VERSION ""

NS_ :

BS_:

BU_: LED_Driver ISC

BO_ 3221225472 VECTOR__INDEPENDENT_SIG_MSG: 0 Vector__XXX
 SG_ Led_S_0_value : 0|8@1+ (1,0) [0|255] "" Vector__XXX
 SG_ Led_break_value : 0|8@1+ (1,0) [0|255] "" Vector__XXX
 SG_ Led_S_0_value : 0|8@1+ (1,0) [0|255] "" Vector__XXX

BO_ 1280 ISC_Ctrl_Right_LED_A_00: 64 ISC
 SG_ Led0064_value : 504|8@1+ (1,0) [0|255] "" Vector__XXX
 SG_ Led0063_value : 496|8@1+ (1,0) [0|255] "" Vector__XXX
 SG_ Led0062_value : 488|8@1+ (1,0) [0|255] "" Vector__XXX
 SG_ Led0061_value : 480|8@1+ (1,0) [0|255] "" Vector__XXX
 SG_ Led0060_value : 472|8@1+ (1,0) [0|255] "" Vector__XXX
 SG_ Led0059_value : 464|8@1+ (1,0) [0|255] "" Vector__XXX
 SG_ Led0058_value : 456|8@1+ (1,0) [0|255] "" Vector__XXX
 SG_ Led0057_value : 448|8@1+ (1,0) [0|255] "" Vector__XXX
 SG_ Led0056_value : 440|8@1+ (1,0) [0|255] "" Vector__XXX
 SG_ Led0055_value : 432|8@1+ (1,0) [0|255] "" Vector__XXX
 SG_ Led0054_value : 424|8@1+ (1,0) [0|255] "" Vector__XXX
 SG_ Led0053_value : 416|8@1+ (1,0) [0|255] "" Vector__XXX
 SG_ Led0052_value : 408|8@1+ (1,0) [0|255] "" Vector__XXX
 SG_ Led0051_value : 400|8@1+ (1,0) [0|255] "" Vector__XXX
 SG_ Led0050_value : 392|8@1+ (1,0) [0|255] "" Vector__XXX
 SG_ Led0049_value : 384|8@1+ (1,0) [0|255] "" Vector__XXX
 SG_ Led0048_value : 376|8@1+ (1,0) [0|255] "" Vector__XXX
 SG_ Led0047_value : 368|8@1+ (1,0) [0|255] "" Vector__XXX
 SG_ Led0046_value : 360|8@1+ (1,0) [0|255] "" Vector__XXX
 SG_ Led0045_value : 352|8@1+ (1,0) [0|255] "" Vector__XXX
 SG_ Led0044_value : 344|8@1+ (1,0) [0|255] "" Vector__XXX
 SG_ Led0043_value : 336|8@1+ (1,0) [0|255] "" Vector__XXX
 SG_ Led0042_value : 328|8@1+ (1,0) [0|255] "" Vector__XXX
 SG_ Led0041_value : 320|8@1+ (1,0) [0|255] "" Vector__XXX
 SG_ Led0040_value : 312|8@1+ (1,0) [0|255] "" Vector__XXX
 SG_ Led0039_value : 304|8@1+ (1,0) [0|255] "" Vector__XXX
 SG_ Led0038_value : 296|8@1+ (1,0) [0|255] "" Vector__XXX
 SG_ Led0037_value : 288|8@1+ (1,0) [0|255] "" Vector__XXX
 SG_ Led0036_value : 280|8@1+ (1,0) [0|255] "" Vector__XXX
 SG_ Led0035_value : 272|8@1+ (1,0) [0|255] "" Vector__XXX
 SG_ Led0034_value : 264|8@1+ (1,0) [0|255] "" Vector__XXX
 SG_ Led0033_value : 256|8@1+ (1,0) [0|255] "" Vector__XXX
 SG_ Led0032_value : 248|8@1+ (1,0) [0|255] "" Vector__XXX
 SG_ Led0031_value : 240|8@1+ (1,0) [0|255] "" Vector__XXX
 SG_ Led0030_value : 232|8@1+ (1,0) [0|255] "" Vector__XXX
 SG_ Led0029_value : 224|8@1+ (1,0) [0|255] "" Vector__XXX
 SG_ Led0028_value : 216|8@1+ (1,0) [0|255] "" Vector__XXX
 SG_ Led0027_value : 208|8@1+ (1,0) [0|255] "" Vector__XXX
 SG_ Led0026_value : 200|8@1+ (1,0) [0|255] "" Vector__XXX
 SG_ Led0025_value : 192|8@1+ (1,0) [0|255] "" Vector__XXX
 SG_ Led0024_value : 184|8@1+ (1,0) [0|255] "" Vector__XXX
 SG_ Led0023_value : 176|8@1+ (1,0) [0|255] "" Vector__XXX
 SG_ Led0022_value : 168|8@1+ (1,0) [0|255] "" Vector__XXX
 SG_ Led0021_value : 160|8@1+ (1,0) [0|255] "" Vector__XXX
 SG_ Led0020_value : 152|8@1+ (1,0) [0|255] "" Vector__XXX
 SG_ Led0019_value : 144|8@1+ (1,0) [0|255] "" Vector__XXX
 SG_ Led0018_value : 136|8@1+ (1,0) [0|255] "" Vector__XXX
 SG_ Led0017_value : 128|8@1+ (1,0) [0|255] "" Vector__XXX
 SG_ Led0016_value : 120|8@1+ (1,0) [0|255] "" Vector__XXX
 SG_ Led0015_value : 112|8@1+ (1,0) [0|255] "" Vector__XXX
 SG_ Led0014_value : 104|8@1+ (1,0) [0|255] "" Vector__XXX
 SG_ Led0013_value : 96|8@1+ (1,0) [0|255] "" Vector__XXX
 SG_ Led0012_value : 88|8@1+ (1,0) [0|255] "" Vector__XXX
 SG_ Led0011_value : 80|8@1+ (1,0) [0|255] "" Vector__XXX
 SG_ Led0010_value : 72|8@1+ (1,0) [0|255] "" Vector__XXX
 SG_ Led0009_value : 64|8@1+ (1,0) [0|255] "" Vector__XXX
 SG_ Led0008_value : 56|8@1+ (1,0) [0|255] "" Vector__XXX
 SG_ Led0007_value : 48|8@1+ (1,0) [0|255] "" Vector__XXX
 SG_ Led0006_value : 40|8@1+ (1,0) [0|255] "" Vector__XXX
 SG_ Led0005_value : 32|8@1+ (1,0) [0|255] "" Vector__XXX
 SG_ Led0004_value : 24|8@1+ (1,0) [0|255] "" Vector__XXX
 SG_ Led0003_value : 16|8@1+ (1,0) [0|255] "" Vector__XXX
 SG_ Led0002_value : 8|8@1+ (1,0) [0|255] "" Vector__XXX
 SG_ Led0001_value : 0|8@1+ (1,0) [0|255] "" Vector__XXX

BO_ 768 ISC_Ctrl_Left_LED_A_00: 64 ISC
 SG_ Led0064_value : 504|8@1+ (1,0) [0|255] "" Vector__XXX
 SG_ Led0063_value : 496|8@1+ (1,0) [0|255] "" Vector__XXX
 SG_ Led0062_value : 488|8@1+ (1,0) [0|255] "" Vector__XXX
 SG_ Led0061_value : 480|8@1+ (1,0) [0|255] "" Vector__XXX
 SG_ Led0060_value : 472|8@1+ (1,0) [0|255] "" Vector__XXX
 SG_ Led0059_value : 464|8@1+ (1,0) [0|255] "" Vector__XXX
 SG_ Led0058_value : 456|8@1+ (1,0) [0|255] "" Vector__XXX
 SG_ Led0057_value : 448|8@1+ (1,0) [0|255] "" Vector__XXX
 SG_ Led0056_value : 440|8@1+ (1,0) [0|255] "" Vector__XXX
 SG_ Led0055_value : 432|8@1+ (1,0) [0|255] "" Vector__XXX
 SG_ Led0054_value : 424|8@1+ (1,0) [0|255] "" Vector__XXX
 SG_ Led0053_value : 416|8@1+ (1,0) [0|255] "" Vector__XXX
 SG_ Led0052_value : 408|8@1+ (1,0) [0|255] "" Vector__XXX
 SG_ Led0051_value : 400|8@1+ (1,0) [0|255] "" Vector__XXX
 SG_ Led0050_value : 392|8@1+ (1,0) [0|255] "" Vector__XXX
 SG_ Led0049_value : 384|8@1+ (1,0) [0|255] "" Vector__XXX
 SG_ Led0048_value : 376|8@1+ (1,0) [0|255] "" Vector__XXX
 SG_ Led0047_value : 368|8@1+ (1,0) [0|255] "" Vector__XXX
 SG_ Led0046_value : 360|8@1+ (1,0) [0|255] "" Vector__XXX
 SG_ Led0045_value : 352|8@1+ (1,0) [0|255] "" Vector__XXX
 SG_ Led0044_value : 344|8@1+ (1,0) [0|255] "" Vector__XXX
 SG_ Led0043_value : 336|8@1+ (1,0) [0|255] "" Vector__XXX
 SG_ Led0042_value : 328|8@1+ (1,0) [0|255] "" Vector__XXX
 SG_ Led0041_value : 320|8@1+ (1,0) [0|255] "" Vector__XXX
 SG_ Led0040_value : 312|8@1+ (1,0) [0|255] "" Vector__XXX
 SG_ Led0039_value : 304|8@1+ (1,0) [0|255] "" Vector__XXX
 SG_ Led0038_value : 296|8@1+ (1,0) [0|255] "" Vector__XXX
 SG_ Led0037_value : 288|8@1+ (1,0) [0|255] "" Vector__XXX
 SG_ Led0036_value : 280|8@1+ (1,0) [0|255] "" Vector__XXX
 SG_ Led0035_value : 272|8@1+ (1,0) [0|255] "" Vector__XXX
 SG_ Led0034_value : 264|8@1+ (1,0) [0|255] "" Vector__XXX
 SG_ Led0033_value : 256|8@1+ (1,0) [0|255] "" Vector__XXX
 SG_ Led0032_value : 248|8@1+ (1,0) [0|255] "" Vector__XXX
 SG_ Led0031_value : 240|8@1+ (1,0) [0|255] "" Vector__XXX
 SG_ Led0030_value : 232|8@1+ (1,0) [0|255] "" Vector__XXX
 SG_ Led0029_value : 224|8@1+ (1,0) [0|255] "" Vector__XXX
 SG_ Led0028_value : 216|8@1+ (1,0) [0|255] "" Vector__XXX
 SG_ Led0027_value : 208|8@1+ (1,0) [0|255] "" Vector__XXX
 SG_ Led0026_value : 200|8@1+ (1,0) [0|255] "" Vector__XXX
 SG_ Led0025_value : 192|8@1+ (1,0) [0|255] "" Vector__XXX
 SG_ Led0024_value : 184|8@1+ (1,0) [0|255] "" Vector__XXX
 SG_ Led0023_value : 176|8@1+ (1,0) [0|255] "" Vector__XXX
 SG_ Led0022_value : 168|8@1+ (1,0) [0|255] "" Vector__XXX
 SG_ Led0021_value : 160|8@1+ (1,0) [0|255] "" Vector__XXX
 SG_ Led0020_value : 152|8@1+ (1,0) [0|255] "" Vector__XXX
 SG_ Led0019_value : 144|8@1+ (1,0) [0|255] "" Vector__XXX
 SG_ Led0018_value : 136|8@1+ (1,0) [0|255] "" Vector__XXX
 SG_ Led0017_value : 128|8@1+ (1,0) [0|255] "" Vector__XXX
 SG_ Led0016_value : 120|8@1+ (1,0) [0|255] "" Vector__XXX
 SG_ Led0015_value : 112|8@1+ (1,0) [0|255] "" Vector__XXX
 SG_ Led0014_value : 104|8@1+ (1,0) [0|255] "" Vector__XXX
 SG_ Led0013_value : 96|8@1+ (1,0) [0|255] "" Vector__XXX
 SG_ Led0012_value : 88|8@1+ (1,0) [0|255] "" Vector__XXX
 SG_ Led0011_value : 80|8@1+ (1,0) [0|255] "" Vector__XXX
 SG_ Led0010_value : 72|8@1+ (1,0) [0|255] "" Vector__XXX
 SG_ Led0009_value : 64|8@1+ (1,0) [0|255] "" Vector__XXX
 SG_ Led0008_value : 56|8@1+ (1,0) [0|255] "" Vector__XXX
 SG_ Led0007_value : 48|8@1+ (1,0) [0|255] "" Vector__XXX
 SG_ Led0006_value : 40|8@1+ (1,0) [0|255] "" Vector__XXX
 SG_ Led0005_value : 32|8@1+ (1,0) [0|255] "" Vector__XXX
 SG_ Led0004_value : 24|8@1+ (1,0) [0|255] "" Vector__XXX
 SG_ Led0003_value : 16|8@1+ (1,0) [0|255] "" Vector__XXX
 SG_ Led0002_value : 8|8@1+ (1,0) [0|255] "" Vector__XXX
 SG_ Led0001_value : 0|8@1+ (1,0) [0|255] "" Vector__XXX

BO_ 1024 ISC_Ctrl_LED_B_00: 64 ISC
 SG_ Led0064_value : 504|8@1+ (1,0) [0|255] "" Vector__XXX
 SG_ Led0063_value : 496|8@1+ (1,0) [0|255] "" Vector__XXX
 SG_ Led0062_value : 488|8@1+ (1,0) [0|255] "" Vector__XXX
 SG_ Led0061_value : 480|8@1+ (1,0) [0|255] "" Vector__XXX
 SG_ Led0060_value : 472|8@1+ (1,0) [0|255] "" Vector__XXX
 SG_ Led0059_value : 464|8@1+ (1,0) [0|255] "" Vector__XXX
 SG_ Led0058_value : 456|8@1+ (1,0) [0|255] "" Vector__XXX
 SG_ Led0057_value : 448|8@1+ (1,0) [0|255] "" Vector__XXX
 SG_ Led0056_value : 440|8@1+ (1,0) [0|255] "" Vector__XXX
 SG_ Led0055_value : 432|8@1+ (1,0) [0|255] "" Vector__XXX
 SG_ Led0054_value : 424|8@1+ (1,0) [0|255] "" Vector__XXX
 SG_ Led0053_value : 416|8@1+ (1,0) [0|255] "" Vector__XXX
 SG_ Led0052_value : 408|8@1+ (1,0) [0|255] "" Vector__XXX
 SG_ Led0051_value : 400|8@1+ (1,0) [0|255] "" Vector__XXX
 SG_ Led0050_value : 392|8@1+ (1,0) [0|255] "" Vector__XXX
 SG_ Led0049_value : 384|8@1+ (1,0) [0|255] "" Vector__XXX
 SG_ Led0048_value : 376|8@1+ (1,0) [0|255] "" Vector__XXX
 SG_ Led0047_value : 368|8@1+ (1,0) [0|255] "" Vector__XXX
 SG_ Led0046_value : 360|8@1+ (1,0) [0|255] "" Vector__XXX
 SG_ Led0045_value : 352|8@1+ (1,0) [0|255] "" Vector__XXX
 SG_ Led0044_value : 344|8@1+ (1,0) [0|255] "" Vector__XXX
 SG_ Led0043_value : 336|8@1+ (1,0) [0|255] "" Vector__XXX
 SG_ Led0042_value : 328|8@1+ (1,0) [0|255] "" Vector__XXX
 SG_ Led0041_value : 320|8@1+ (1,0) [0|255] "" Vector__XXX
 SG_ Led0040_value : 312|8@1+ (1,0) [0|255] "" Vector__XXX
 SG_ Led0039_value : 304|8@1+ (1,0) [0|255] "" Vector__XXX
 SG_ Led0038_value : 296|8@1+ (1,0) [0|255] "" Vector__XXX
 SG_ Led0037_value : 288|8@1+ (1,0) [0|255] "" Vector__XXX
 SG_ Led0036_value : 280|8@1+ (1,0) [0|255] "" Vector__XXX
 SG_ Led0035_value : 272|8@1+ (1,0) [0|255] "" Vector__XXX
 SG_ Led0034_value : 264|8@1+ (1,0) [0|255] "" Vector__XXX
 SG_ Led0033_value : 256|8@1+ (1,0) [0|255] "" Vector__XXX
 SG_ Led0032_value : 248|8@1+ (1,0) [0|255] "" Vector__XXX
 SG_ Led0031_value : 240|8@1+ (1,0) [0|255] "" Vector__XXX
 SG_ Led0030_value : 232|8@1+ (1,0) [0|255] "" Vector__XXX
 SG_ Led0029_value : 224|8@1+ (1,0) [0|255] "" Vector__XXX
 SG_ Led0028_value : 216|8@1+ (1,0) [0|255] "" Vector__XXX
 SG_ Led0027_value : 208|8@1+ (1,0) [0|255] "" Vector__XXX
 SG_ Led0026_value : 200|8@1+ (1,0) [0|255] "" Vector__XXX
 SG_ Led0025_value : 192|8@1+ (1,0) [0|255] "" Vector__XXX
 SG_ Led0024_value : 184|8@1+ (1,0) [0|255] "" Vector__XXX
 SG_ Led0023_value : 176|8@1+ (1,0) [0|255] "" Vector__XXX
 SG_ Led0022_value : 168|8@1+ (1,0) [0|255] "" Vector__XXX
 SG_ Led0021_value : 160|8@1+ (1,0) [0|255] "" Vector__XXX
 SG_ Led0020_value : 152|8@1+ (1,0) [0|255] "" Vector__XXX
 SG_ Led0019_value : 144|8@1+ (1,0) [0|255] "" Vector__XXX
 SG_ Led0018_value : 136|8@1+ (1,0) [0|255] "" Vector__XXX
 SG_ Led0017_value : 128|8@1+ (1,0) [0|255] "" Vector__XXX
 SG_ Led0016_value : 120|8@1+ (1,0) [0|255] "" Vector__XXX
 SG_ Led0015_value : 112|8@1+ (1,0) [0|255] "" Vector__XXX
 SG_ Led0014_value : 104|8@1+ (1,0) [0|255] "" Vector__XXX
 SG_ Led0013_value : 96|8@1+ (1,0) [0|255] "" Vector__XXX
 SG_ Led0012_value : 88|8@1+ (1,0) [0|255] "" Vector__XXX
 SG_ Led0011_value : 80|8@1+ (1,0) [0|255] "" Vector__XXX
 SG_ Led0010_value : 72|8@1+ (1,0) [0|255] "" Vector__XXX
 SG_ Led0009_value : 64|8@1+ (1,0) [0|255] "" Vector__XXX
 SG_ Led0008_value : 56|8@1+ (1,0) [0|255] "" Vector__XXX
 SG_ Led0007_value : 48|8@1+ (1,0) [0|255] "" Vector__XXX
 SG_ Led0006_value : 40|8@1+ (1,0) [0|255] "" Vector__XXX
 SG_ Led0005_value : 32|8@1+ (1,0) [0|255] "" Vector__XXX
 SG_ Led0004_value : 24|8@1+ (1,0) [0|255] "" Vector__XXX
 SG_ Led0003_value : 16|8@1+ (1,0) [0|255] "" Vector__XXX
 SG_ Led0002_value : 8|8@1+ (1,0) [0|255] "" Vector__XXX
 SG_ Led0001_value : 0|8@1+ (1,0) [0|255] "" Vector__XXX

BO_ 1713 Rear_FaultLed_Feedback_Right_A: 64 LED_Driver
 SG_ Led0299_fault : 298|1@1+ (1,0) [0|1] "" Vector__XXX
 SG_ Led0298_fault : 297|1@1+ (1,0) [0|1] "" Vector__XXX
 SG_ Led0297_fault : 296|1@1+ (1,0) [0|1] "" Vector__XXX
 SG_ Led0296_fault : 295|1@1+ (1,0) [0|1] "" Vector__XXX
 SG_ Led0295_fault : 294|1@1+ (1,0) [0|1] "" Vector__XXX
 SG_ Led0294_fault : 293|1@1+ (1,0) [0|1] "" Vector__XXX
 SG_ Led0293_fault : 292|1@1+ (1,0) [0|1] "" Vector__XXX
 SG_ Led0292_fault : 291|1@1+ (1,0) [0|1] "" Vector__XXX
 SG_ Led0291_fault : 290|1@1+ (1,0) [0|1] "" Vector__XXX
 SG_ Led0290_fault : 289|1@1+ (1,0) [0|1] "" Vector__XXX
 SG_ Led0289_fault : 288|1@1+ (1,0) [0|1] "" Vector__XXX
 SG_ Led0288_fault : 287|1@1+ (1,0) [0|1] "" Vector__XXX
 SG_ Led0287_fault : 286|1@1+ (1,0) [0|1] "" Vector__XXX
 SG_ Led0286_fault : 285|1@1+ (1,0) [0|1] "" Vector__XXX
 SG_ Led0285_fault : 284|1@1+ (1,0) [0|1] "" Vector__XXX
 SG_ Led0284_fault : 283|1@1+ (1,0) [0|1] "" Vector__XXX
 SG_ Led0283_fault : 282|1@1+ (1,0) [0|1] "" Vector__XXX
 SG_ Led0282_fault : 281|1@1+ (1,0) [0|1] "" Vector__XXX
 SG_ Led0281_fault : 280|1@1+ (1,0) [0|1] "" Vector__XXX
 SG_ Led0280_fault : 279|1@1+ (1,0) [0|1] "" Vector__XXX
 SG_ Led0279_fault : 278|1@1+ (1,0) [0|1] "" Vector__XXX
 SG_ Led0278_fault : 277|1@1+ (1,0) [0|1] "" Vector__XXX
 SG_ Led0277_fault : 276|1@1+ (1,0) [0|1] "" Vector__XXX
 SG_ Led0276_fault : 275|1@1+ (1,0) [0|1] "" Vector__XXX
 SG_ Led0275_fault : 274|1@1+ (1,0) [0|1] "" Vector__XXX
 SG_ Led0274_fault : 273|1@1+ (1,0) [0|1] "" Vector__XXX
 SG_ Led0273_fault : 272|1@1+ (1,0) [0|1] "" Vector__XXX
 SG_ Led0272_fault : 271|1@1+ (1,0) [0|1] "" Vector__XXX
 SG_ Led0271_fault : 270|1@1+ (1,0) [0|1] "" Vector__XXX
 SG_ Led0270_fault : 269|1@1+ (1,0) [0|1] "" Vector__XXX
 SG_ Led0269_fault : 268|1@1+ (1,0) [0|1] "" Vector__XXX
 SG_ Led0268_fault : 267|1@1+ (1,0) [0|1] "" Vector__XXX
 SG_ Led0267_fault : 266|1@1+ (1,0) [0|1] "" Vector__XXX
 SG_ Led0266_fault : 265|1@1+ (1,0) [0|1] "" Vector__XXX
 SG_ Led0265_fault : 264|1@1+ (1,0) [0|1] "" Vector__XXX
 SG_ Led0264_fault : 263|1@1+ (1,0) [0|1] "" Vector__XXX
 SG_ Led0263_fault : 262|1@1+ (1,0) [0|1] "" Vector__XXX
 SG_ Led0262_fault : 261|1@1+ (1,0) [0|1] "" Vector__XXX
 SG_ Led0261_fault : 260|1@1+ (1,0) [0|1] "" Vector__XXX
 SG_ Led0260_fault : 259|1@1+ (1,0) [0|1] "" Vector__XXX
 SG_ Led0259_fault : 258|1@1+ (1,0) [0|1] "" Vector__XXX
 SG_ Led0258_fault : 257|1@1+ (1,0) [0|1] "" Vector__XXX
 SG_ Led0257_fault : 256|1@1+ (1,0) [0|1] "" Vector__XXX
 SG_ Led0256_fault : 255|1@1+ (1,0) [0|1] "" Vector__XXX
 SG_ Led0255_fault : 254|1@1+ (1,0) [0|1] "" Vector__XXX
 SG_ Led0254_fault : 253|1@1+ (1,0) [0|1] "" Vector__XXX
 SG_ Led0253_fault : 252|1@1+ (1,0) [0|1] "" Vector__XXX
 SG_ Led0252_fault : 251|1@1+ (1,0) [0|1] "" Vector__XXX
 SG_ Led0251_fault : 250|1@1+ (1,0) [0|1] "" Vector__XXX
 SG_ Led0250_fault : 249|1@1+ (1,0) [0|1] "" Vector__XXX
 SG_ Led0249_fault : 248|1@1+ (1,0) [0|1] "" Vector__XXX
 SG_ Led0248_fault : 247|1@1+ (1,0) [0|1] "" Vector__XXX
 SG_ Led0247_fault : 246|1@1+ (1,0) [0|1] "" Vector__XXX
 SG_ Led0246_fault : 245|1@1+ (1,0) [0|1] "" Vector__XXX
 SG_ Led0245_fault : 244|1@1+ (1,0) [0|1] "" Vector__XXX
 SG_ Led0244_fault : 243|1@1+ (1,0) [0|1] "" Vector__XXX
 SG_ Led0243_fault : 242|1@1+ (1,0) [0|1] "" Vector__XXX
 SG_ Led0242_fault : 241|1@1+ (1,0) [0|1] "" Vector__XXX
 SG_ Led0241_fault : 240|1@1+ (1,0) [0|1] "" Vector__XXX
 SG_ Led0240_fault : 239|1@1+ (1,0) [0|1] "" Vector__XXX
 SG_ Led0239_fault : 238|1@1+ (1,0) [0|1] "" Vector__XXX
 SG_ Led0238_fault : 237|1@1+ (1,0) [0|1] "" Vector__XXX
 SG_ Led0237_fault : 236|1@1+ (1,0) [0|1] "" Vector__XXX
 SG_ Led0236_fault : 235|1@1+ (1,0) [0|1] "" Vector__XXX
 SG_ Led0235_fault : 234|1@1+ (1,0) [0|1] "" Vector__XXX
 SG_ Led0234_fault : 233|1@1+ (1,0) [0|1] "" Vector__XXX
 SG_ Led0233_fault : 232|1@1+ (1,0) [0|1] "" Vector__XXX
 SG_ Led0232_fault : 231|1@1+ (1,0) [0|1] "" Vector__XXX
 SG_ Led0231_fault : 230|1@1+ (1,0) [0|1] "" Vector__XXX
 SG_ Led0230_fault : 229|1@1+ (1,0) [0|1] "" Vector__XXX
 SG_ Led0229_fault : 228|1@1+ (1,0) [0|1] "" Vector__XXX
 SG_ Led0228_fault : 227|1@1+ (1,0) [0|1] "" Vector__XXX
 SG_ Led0227_fault : 226|1@1+ (1,0) [0|1] "" Vector__XXX
 SG_ Led0226_fault : 225|1@1+ (1,0) [0|1] "" Vector__XXX
 SG_ Led0225_fault : 224|1@1+ (1,0) [0|1] "" Vector__XXX
 SG_ Led0224_fault : 223|1@1+ (1,0) [0|1] "" Vector__XXX
 SG_ Led0223_fault : 222|1@1+ (1,0) [0|1] "" Vector__XXX
 SG_ Led0222_fault : 221|1@1+ (1,0) [0|1] "" Vector__XXX
 SG_ Led0221_fault : 220|1@1+ (1,0) [0|1] "" Vector__XXX
 SG_ Led0220_fault : 219|1@1+ (1,0) [0|1] "" Vector__XXX
 SG_ Led0219_fault : 218|1@1+ (1,0) [0|1] "" Vector__XXX
 SG_ Led0218_fault : 217|1@1+ (1,0) [0|1] "" Vector__XXX
 SG_ Led0217_fault : 216|1@1+ (1,0) [0|1] "" Vector__XXX
 SG_ Led0216_fault : 215|1@1+ (1,0) [0|1] "" Vector__XXX
 SG_ Led0215_fault : 214|1@1+ (1,0) [0|1] "" Vector__XXX
 SG_ Led0214_fault : 213|1@1+ (1,0) [0|1] "" Vector__XXX
 SG_ Led0213_fault : 212|1@1+ (1,0) [0|1] "" Vector__XXX
 SG_ Led0212_fault : 211|1@1+ (1,0) [0|1] "" Vector__XXX
 SG_ Led0211_fault : 210|1@1+ (1,0) [0|1] "" Vector__XXX
 SG_ Led0210_fault : 209|1@1+ (1,0) [0|1] "" Vector__XXX
 SG_ Led0209_fault : 208|1@1+ (1,0) [0|1] "" Vector__XXX
 SG_ Led0208_fault : 207|1@1+ (1,0) [0|1] "" Vector__XXX
 SG_ Led0207_fault : 206|1@1+ (1,0) [0|1] "" Vector__XXX
 SG_ Led0206_fault : 205|1@1+ (1,0) [0|1] "" Vector__XXX
 SG_ Led0205_fault : 204|1@1+ (1,0) [0|1] "" Vector__XXX
 SG_ Led0204_fault : 203|1@1+ (1,0) [0|1] "" Vector__XXX
 SG_ Led0203_fault : 202|1@1+ (1,0) [0|1] "" Vector__XXX
 SG_ Led0202_fault : 201|1@1+ (1,0) [0|1] "" Vector__XXX
 SG_ Led0201_fault : 200|1@1+ (1,0) [0|1] "" Vector__XXX
 SG_ Led0200_fault : 199|1@1+ (1,0) [0|1] "" Vector__XXX
 SG_ Led0199_fault : 198|1@1+ (1,0) [0|1] "" Vector__XXX
 SG_ Led0198_fault : 197|1@1+ (1,0) [0|1] "" Vector__XXX
 SG_ Led0197_fault : 196|1@1+ (1,0) [0|1] "" Vector__XXX
 SG_ Led0196_fault : 195|1@1+ (1,0) [0|1] "" Vector__XXX
 SG_ Led0195_fault : 194|1@1+ (1,0) [0|1] "" Vector__XXX
 SG_ Led0194_fault : 193|1@1+ (1,0) [0|1] "" Vector__XXX
 SG_ Led0193_fault : 192|1@1+ (1,0) [0|1] "" Vector__XXX
 SG_ Led0192_fault : 191|1@1+ (1,0) [0|1] "" Vector__XXX
 SG_ Led0191_fault : 190|1@1+ (1,0) [0|1] "" Vector__XXX
 SG_ Led0190_fault : 189|1@1+ (1,0) [0|1] "" Vector__XXX
 SG_ Led0189_fault : 188|1@1+ (1,0) [0|1] "" Vector__XXX
 SG_ Led0188_fault : 187|1@1+ (1,0) [0|1] "" Vector__XXX
 SG_ Led0187_fault : 186|1@1+ (1,0) [0|1] "" Vector__XXX
 SG_ Led0186_fault : 185|1@1+ (1,0) [0|1] "" Vector__XXX
 SG_ Led0185_fault : 184|1@1+ (1,0) [0|1] "" Vector__XXX
 SG_ Led0184_fault : 183|1@1+ (1,0) [0|1] "" Vector__XXX
 SG_ Led0183_fault : 182|1@1+ (1,0) [0|1] "" Vector__XXX
 SG_ Led0182_fault : 181|1@1+ (1,0) [0|1] "" Vector__XXX
 SG_ Led0181_fault : 180|1@1+ (1,0) [0|1] "" Vector__XXX
 SG_ Led0180_fault : 179|1@1+ (1,0) [0|1] "" Vector__XXX
 SG_ Led0179_fault : 178|1@1+ (1,0) [0|1] "" Vector__XXX
 SG_ Led0178_fault : 177|1@1+ (1,0) [0|1] "" Vector__XXX
 SG_ Led0177_fault : 176|1@1+ (1,0) [0|1] "" Vector__XXX
 SG_ Led0176_fault : 175|1@1+ (1,0) [0|1] "" Vector__XXX
 SG_ Led0175_fault : 174|1@1+ (1,0) [0|1] "" Vector__XXX
 SG_ Led0174_fault : 173|1@1+ (1,0) [0|1] "" Vector__XXX
 SG_ Led0173_fault : 172|1@1+ (1,0) [0|1] "" Vector__XXX
 SG_ Led0172_fault : 171|1@1+ (1,0) [0|1] "" Vector__XXX
 SG_ Led0171_fault : 170|1@1+ (1,0) [0|1] "" Vector__XXX
 SG_ Led0170_fault : 169|1@1+ (1,0) [0|1] "" Vector__XXX
 SG_ Led0169_fault : 168|1@1+ (1,0) [0|1] "" Vector__XXX
 SG_ Led0168_fault : 167|1@1+ (1,0) [0|1] "" Vector__XXX
 SG_ Led0167_fault : 166|1@1+ (1,0) [0|1] "" Vector__XXX
 SG_ Led0166_fault : 165|1@1+ (1,0) [0|1] "" Vector__XXX
 SG_ Led0165_fault : 164|1@1+ (1,0) [0|1] "" Vector__XXX
 SG_ Led0164_fault : 163|1@1+ (1,0) [0|1] "" Vector__XXX
 SG_ Led0163_fault : 162|1@1+ (1,0) [0|1] "" Vector__XXX
 SG_ Led0162_fault : 161|1@1+ (1,0) [0|1] "" Vector__XXX
 SG_ Led0161_fault : 160|1@1+ (1,0) [0|1] "" Vector__XXX
 SG_ Led0160_fault : 159|1@1+ (1,0) [0|1] "" Vector__XXX
 SG_ Led0159_fault : 158|1@1+ (1,0) [0|1] "" Vector__XXX
 SG_ Led0158_fault : 157|1@1+ (1,0) [0|1] "" Vector__XXX
 SG_ Led0157_fault : 156|1@1+ (1,0) [0|1] "" Vector__XXX
 SG_ Led0156_fault : 155|1@1+ (1,0) [0|1] "" Vector__XXX
 SG_ Led0155_fault : 154|1@1+ (1,0) [0|1] "" Vector__XXX
 SG_ Led0154_fault : 153|1@1+ (1,0) [0|1] "" Vector__XXX
 SG_ Led0153_fault : 152|1@1+ (1,0) [0|1] "" Vector__XXX
 SG_ Led0152_fault : 151|1@1+ (1,0) [0|1] "" Vector__XXX
 SG_ Led0151_fault : 150|1@1+ (1,0) [0|1] "" Vector__XXX
 SG_ Led0150_fault : 149|1@1+ (1,0) [0|1] "" Vector__XXX
 SG_ Led0149_fault : 148|1@1+ (1,0) [0|1] "" Vector__XXX
 SG_ Led0148_fault : 147|1@1+ (1,0) [0|1] "" Vector__XXX
 SG_ Led0147_fault : 146|1@1+ (1,0) [0|1] "" Vector__XXX
 SG_ Led0146_fault : 145|1@1+ (1,0) [0|1] "" Vector__XXX
 SG_ Led0145_fault : 144|1@1+ (1,0) [0|1] "" Vector__XXX
 SG_ Led0144_fault : 143|1@1+ (1,0) [0|1] "" Vector__XXX
 SG_ Led0143_fault : 142|1@1+ (1,0) [0|1] "" Vector__XXX
 SG_ Led0142_fault : 141|1@1+ (1,0) [0|1] "" Vector__XXX
 SG_ Led0141_fault : 140|1@1+ (1,0) [0|1] "" Vector__XXX
 SG_ Led0140_fault : 139|1@1+ (1,0) [0|1] "" Vector__XXX
 SG_ Led0139_fault : 138|1@1+ (1,0) [0|1] "" Vector__XXX
 SG_ Led0138_fault : 137|1@1+ (1,0) [0|1] "" Vector__XXX
 SG_ Led0137_fault : 136|1@1+ (1,0) [0|1] "" Vector__XXX
 SG_ Led0136_fault : 135|1@1+ (1,0) [0|1] "" Vector__XXX
 SG_ Led0135_fault : 134|1@1+ (1,0) [0|1] "" Vector__XXX
 SG_ Led0134_fault : 133|1@1+ (1,0) [0|1] "" Vector__XXX
 SG_ Led0133_fault : 132|1@1+ (1,0) [0|1] "" Vector__XXX
 SG_ Led0132_fault : 131|1@1+ (1,0) [0|1] "" Vector__XXX
 SG_ Led0131_fault : 130|1@1+ (1,0) [0|1] "" Vector__XXX
 SG_ Led0130_fault : 129|1@1+ (1,0) [0|1] "" Vector__XXX
 SG_ Led0129_fault : 128|1@1+ (1,0) [0|1] "" Vector__XXX
 SG_ Led0128_fault : 127|1@1+ (1,0) [0|1] "" Vector__XXX
 SG_ Led0127_fault : 126|1@1+ (1,0) [0|1] "" Vector__XXX
 SG_ Led0126_fault : 125|1@1+ (1,0) [0|1] "" Vector__XXX
 SG_ Led0125_fault : 124|1@1+ (1,0) [0|1] "" Vector__XXX
 SG_ Led0124_fault : 123|1@1+ (1,0) [0|1] "" Vector__XXX
 SG_ Led0123_fault : 122|1@1+ (1,0) [0|1] "" Vector__XXX
 SG_ Led0122_fault : 121|1@1+ (1,0) [0|1] "" Vector__XXX
 SG_ Led0121_fault : 120|1@1+ (1,0) [0|1] "" Vector__XXX
 SG_ Led0120_fault : 119|1@1+ (1,0) [0|1] "" Vector__XXX
 SG_ Led0119_fault : 118|1@1+ (1,0) [0|1] "" Vector__XXX
 SG_ Led0118_fault : 117|1@1+ (1,0) [0|1] "" Vector__XXX
 SG_ Led0117_fault : 116|1@1+ (1,0) [0|1] "" Vector__XXX
 SG_ Led0116_fault : 115|1@1+ (1,0) [0|1] "" Vector__XXX
 SG_ Led0115_fault : 114|1@1+ (1,0) [0|1] "" Vector__XXX
 SG_ Led0114_fault : 113|1@1+ (1,0) [0|1] "" Vector__XXX
 SG_ Led0113_fault : 112|1@1+ (1,0) [0|1] "" Vector__XXX
 SG_ Led0112_fault : 111|1@1+ (1,0) [0|1] "" Vector__XXX
 SG_ Led0111_fault : 110|1@1+ (1,0) [0|1] "" Vector__XXX
 SG_ Led0110_fault : 109|1@1+ (1,0) [0|1] "" Vector__XXX
 SG_ Led0109_fault : 108|1@1+ (1,0) [0|1] "" Vector__XXX
 SG_ Led0108_fault : 107|1@1+ (1,0) [0|1] "" Vector__XXX
 SG_ Led0107_fault : 106|1@1+ (1,0) [0|1] "" Vector__XXX
 SG_ Led0106_fault : 105|1@1+ (1,0) [0|1] "" Vector__XXX
 SG_ Led0105_fault : 104|1@1+ (1,0) [0|1] "" Vector__XXX
 SG_ Led0104_fault : 103|1@1+ (1,0) [0|1] "" Vector__XXX
 SG_ Led0103_fault : 102|1@1+ (1,0) [0|1] "" Vector__XXX
 SG_ Led0102_fault : 101|1@1+ (1,0) [0|1] "" Vector__XXX
 SG_ Led0101_fault : 100|1@1+ (1,0) [0|1] "" Vector__XXX
 SG_ Led0100_fault : 99|1@1+ (1,0) [0|1] "" Vector__XXX
 SG_ Led0099_fault : 98|1@1+ (1,0) [0|1] "" Vector__XXX
 SG_ Led0098_fault : 97|1@1+ (1,0) [0|1] "" Vector__XXX
 SG_ Led0097_fault : 96|1@1+ (1,0) [0|1] "" Vector__XXX
 SG_ Led0096_fault : 95|1@1+ (1,0) [0|1] "" Vector__XXX
 SG_ Led0095_fault : 94|1@1+ (1,0) [0|1] "" Vector__XXX
 SG_ Led0094_fault : 93|1@1+ (1,0) [0|1] "" Vector__XXX
 SG_ Led0093_fault : 92|1@1+ (1,0) [0|1] "" Vector__XXX
 SG_ Led0092_fault : 91|1@1+ (1,0) [0|1] "" Vector__XXX
 SG_ Led0091_fault : 90|1@1+ (1,0) [0|1] "" Vector__XXX
 SG_ Led0090_fault : 89|1@1+ (1,0) [0|1] "" Vector__XXX
 SG_ Led0089_fault : 88|1@1+ (1,0) [0|1] "" Vector__XXX
 SG_ Led0088_fault : 87|1@1+ (1,0) [0|1] "" Vector__XXX
 SG_ Led0087_fault : 86|1@1+ (1,0) [0|1] "" Vector__XXX
 SG_ Led0086_fault : 85|1@1+ (1,0) [0|1] "" Vector__XXX
 SG_ Led0085_fault : 84|1@1+ (1,0) [0|1] "" Vector__XXX
 SG_ Led0084_fault : 83|1@1+ (1,0) [0|1] "" Vector__XXX
 SG_ Led0083_fault : 82|1@1+ (1,0) [0|1] "" Vector__XXX
 SG_ Led0082_fault : 81|1@1+ (1,0) [0|1] "" Vector__XXX
 SG_ Led0081_fault : 80|1@1+ (1,0) [0|1] "" Vector__XXX
 SG_ Led0080_fault : 79|1@1+ (1,0) [0|1] "" Vector__XXX
 SG_ Led0079_fault : 78|1@1+ (1,0) [0|1] "" Vector__XXX
 SG_ Led0078_fault : 77|1@1+ (1,0) [0|1] "" Vector__XXX
 SG_ Led0077_fault : 76|1@1+ (1,0) [0|1] "" Vector__XXX
 SG_ Led0076_fault : 75|1@1+ (1,0) [0|1] "" Vector__XXX
 SG_ Led0075_fault : 74|1@1+ (1,0) [0|1] "" Vector__XXX
 SG_ Led0074_fault : 73|1@1+ (1,0) [0|1] "" Vector__XXX
 SG_ Led0073_fault : 72|1@1+ (1,0) [0|1] "" Vector__XXX
 SG_ Led0072_fault : 71|1@1+ (1,0) [0|1] "" Vector__XXX
 SG_ Led0071_fault : 70|1@1+ (1,0) [0|1] "" Vector__XXX
 SG_ Led0070_fault : 69|1@1+ (1,0) [0|1] "" Vector__XXX
 SG_ Led0069_fault : 68|1@1+ (1,0) [0|1] "" Vector__XXX
 SG_ Led0068_fault : 67|1@1+ (1,0) [0|1] "" Vector__XXX
 SG_ Led0067_fault : 66|1@1+ (1,0) [0|1] "" Vector__XXX
 SG_ Led0066_fault : 65|1@1+ (1,0) [0|1] "" Vector__XXX
 SG_ Led0065_fault : 64|1@1+ (1,0) [0|1] "" Vector__XXX
 SG_ Led0064_fault : 63|1@1+ (1,0) [0|1] "" Vector__XXX
 SG_ Led0063_fault : 62|1@1+ (1,0) [0|1] "" Vector__XXX
 SG_ Led0062_fault : 61|1@1+ (1,0) [0|1] "" Vector__XXX
 SG_ Led0061_fault : 60|1@1+ (1,0) [0|1] "" Vector__XXX
 SG_ Led0060_fault : 59|1@1+ (1,0) [0|1] "" Vector__XXX
 SG_ Led0059_fault : 58|1@1+ (1,0) [0|1] "" Vector__XXX
 SG_ Led0058_fault : 57|1@1+ (1,0) [0|1] "" Vector__XXX
 SG_ Led0057_fault : 56|1@1+ (1,0) [0|1] "" Vector__XXX
 SG_ Led0056_fault : 55|1@1+ (1,0) [0|1] "" Vector__XXX
 SG_ Led0055_fault : 54|1@1+ (1,0) [0|1] "" Vector__XXX
 SG_ Led0054_fault : 53|1@1+ (1,0) [0|1] "" Vector__XXX
 SG_ Led0053_fault : 52|1@1+ (1,0) [0|1] "" Vector__XXX
 SG_ Led0052_fault : 51|1@1+ (1,0) [0|1] "" Vector__XXX
 SG_ Led0051_fault : 50|1@1+ (1,0) [0|1] "" Vector__XXX
 SG_ Led0050_fault : 49|1@1+ (1,0) [0|1] "" Vector__XXX
 SG_ Led0049_fault : 48|1@1+ (1,0) [0|1] "" Vector__XXX
 SG_ Led0048_fault : 47|1@1+ (1,0) [0|1] "" Vector__XXX
 SG_ Led0047_fault : 46|1@1+ (1,0) [0|1] "" Vector__XXX
 SG_ Led0046_fault : 45|1@1+ (1,0) [0|1] "" Vector__XXX
 SG_ Led0045_fault : 44|1@1+ (1,0) [0|1] "" Vector__XXX
 SG_ Led0044_fault : 43|1@1+ (1,0) [0|1] "" Vector__XXX
 SG_ Led0043_fault : 42|1@1+ (1,0) [0|1] "" Vector__XXX
 SG_ Led0042_fault : 41|1@1+ (1,0) [0|1] "" Vector__XXX
 SG_ Led0041_fault : 40|1@1+ (1,0) [0|1] "" Vector__XXX
 SG_ Led0040_fault : 39|1@1+ (1,0) [0|1] "" Vector__XXX
 SG_ Led0039_fault : 38|1@1+ (1,0) [0|1] "" Vector__XXX
 SG_ Led0038_fault : 37|1@1+ (1,0) [0|1] "" Vector__XXX
 SG_ Led0037_fault : 36|1@1+ (1,0) [0|1] "" Vector__XXX
 SG_ Led0036_fault : 35|1@1+ (1,0) [0|1] "" Vector__XXX
 SG_ Led0035_fault : 34|1@1+ (1,0) [0|1] "" Vector__XXX
 SG_ Led0034_fault : 33|1@1+ (1,0) [0|1] "" Vector__XXX
 SG_ Led0033_fault : 32|1@1+ (1,0) [0|1] "" Vector__XXX
 SG_ Led0032_fault : 31|1@1+ (1,0) [0|1] "" Vector__XXX
 SG_ Led0031_fault : 30|1@1+ (1,0) [0|1] "" Vector__XXX
 SG_ Led0030_fault : 29|1@1+ (1,0) [0|1] "" Vector__XXX
 SG_ Led0029_fault : 28|1@1+ (1,0) [0|1] "" Vector__XXX
 SG_ Led0028_fault : 27|1@1+ (1,0) [0|1] "" Vector__XXX
 SG_ Led0027_fault : 26|1@1+ (1,0) [0|1] "" Vector__XXX
 SG_ Led0026_fault : 25|1@1+ (1,0) [0|1] "" Vector__XXX
 SG_ Led0025_fault : 24|1@1+ (1,0) [0|1] "" Vector__XXX
 SG_ Led0024_fault : 23|1@1+ (1,0) [0|1] "" Vector__XXX
 SG_ Led0023_fault : 22|1@1+ (1,0) [0|1] "" Vector__XXX
 SG_ Led0022_fault : 21|1@1+ (1,0) [0|1] "" Vector__XXX
 SG_ Led0021_fault : 20|1@1+ (1,0) [0|1] "" Vector__XXX
 SG_ Led0020_fault : 19|1@1+ (1,0) [0|1] "" Vector__XXX
 SG_ Led0019_fault : 18|1@1+ (1,0) [0|1] "" Vector__XXX
 SG_ Led0018_fault : 17|1@1+ (1,0) [0|1] "" Vector__XXX
 SG_ Led0017_fault : 16|1@1+ (1,0) [0|1] "" Vector__XXX
 SG_ Led0016_fault : 15|1@1+ (1,0) [0|1] "" Vector__XXX
 SG_ Led0015_fault : 14|1@1+ (1,0) [0|1] "" Vector__XXX
 SG_ Led0014_fault : 13|1@1+ (1,0) [0|1] "" Vector__XXX
 SG_ Led0013_fault : 12|1@1+ (1,0) [0|1] "" Vector__XXX
 SG_ Led0012_fault : 11|1@1+ (1,0) [0|1] "" Vector__XXX
 SG_ Led0011_fault : 10|1@1+ (1,0) [0|1] "" Vector__XXX
 SG_ Led0010_fault : 9|1@1+ (1,0) [0|1] "" Vector__XXX
 SG_ Led0007_fault : 6|1@1+ (1,0) [0|1] "" Vector__XXX
 SG_ Led0009_fault : 8|1@1+ (1,0) [0|1] "" Vector__XXX
 SG_ Led0008_fault : 7|1@1+ (1,0) [0|1] "" Vector__XXX
 SG_ Led0006_fault : 5|1@1+ (1,0) [0|1] "" Vector__XXX
 SG_ Led0005_fault : 4|1@1+ (1,0) [0|1] "" Vector__XXX
 SG_ Led0004_fault : 3|1@1+ (1,0) [0|1] "" Vector__XXX
 SG_ Led0003_fault : 2|1@1+ (1,0) [0|1] "" Vector__XXX
 SG_ Led0002_fault : 1|1@1+ (1,0) [0|1] "" Vector__XXX
 SG_ Led0001_fault : 0|1@1+ (1,0) [0|1] "" Vector__XXX

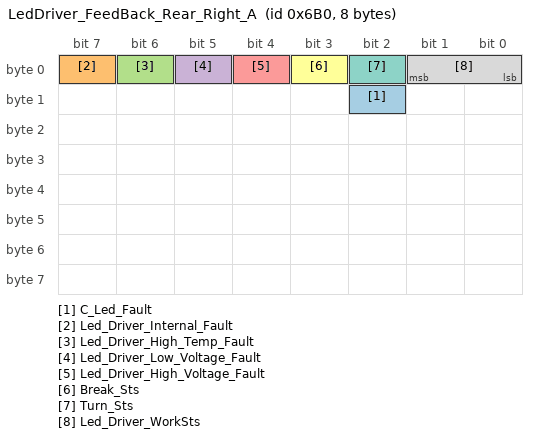
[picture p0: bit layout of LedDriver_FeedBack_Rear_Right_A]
BO_ 1712 LedDriver_FeedBack_Rear_Right_A: 8 LED_Driver
 SG_ C_Led_Fault : 10|1@1+ (1,0) [0|1] "" Vector__XXX
 SG_ Led_Driver_Internal_Fault : 7|1@1+ (1,0) [0|1] "" Vector__XXX
 SG_ Led_Driver_High_Temp_Fault : 6|1@1+ (1,0) [0|1] "" Vector__XXX
 SG_ Led_Driver_Low_Voltage_Fault : 5|1@1+ (1,0) [0|1] "" Vector__XXX
 SG_ Led_Driver_High_Voltage_Fault : 4|1@1+ (1,0) [0|1] "" Vector__XXX
 SG_ Break_Sts : 3|1@1+ (1,0) [0|1] "" Vector__XXX
 SG_ Turn_Sts : 2|1@1+ (1,0) [0|1] "" Vector__XXX
 SG_ Led_Driver_WorkSts : 0|2@1+ (1,0) [0|3] "" Vector__XXX

BO_ 1701 Rear_FaultLed_Feedback_B_05: 64 LED_Driver
 SG_ Led0415_fault : 414|1@1+ (1,0) [0|1] "" Vector__XXX
 SG_ Led0414_fault : 413|1@1+ (1,0) [0|1] "" Vector__XXX
 SG_ Led0413_fault : 412|1@1+ (1,0) [0|1] "" Vector__XXX
 SG_ Led0412_fault : 411|1@1+ (1,0) [0|1] "" Vector__XXX
 SG_ Led0411_fault : 410|1@1+ (1,0) [0|1] "" Vector__XXX
 SG_ Led0410_fault : 409|1@1+ (1,0) [0|1] "" Vector__XXX
 SG_ Led0409_fault : 408|1@1+ (1,0) [0|1] "" Vector__XXX
 SG_ Led0408_fault : 407|1@1+ (1,0) [0|1] "" Vector__XXX
 SG_ Led0407_fault : 406|1@1+ (1,0) [0|1] "" Vector__XXX
 SG_ Led0406_fault : 405|1@1+ (1,0) [0|1] "" Vector__XXX
 SG_ Led0405_fault : 404|1@1+ (1,0) [0|1] "" Vector__XXX
 SG_ Led0404_fault : 403|1@1+ (1,0) [0|1] "" Vector__XXX
 SG_ Led0403_fault : 402|1@1+ (1,0) [0|1] "" Vector__XXX
 SG_ Led0402_fault : 401|1@1+ (1,0) [0|1] "" Vector__XXX
 SG_ Led0401_fault : 400|1@1+ (1,0) [0|1] "" Vector__XXX
 SG_ Led0400_fault : 399|1@1+ (1,0) [0|1] "" Vector__XXX
 SG_ Led0399_fault : 398|1@1+ (1,0) [0|1] "" Vector__XXX
 SG_ Led0398_fault : 397|1@1+ (1,0) [0|1] "" Vector__XXX
 SG_ Led0397_fault : 396|1@1+ (1,0) [0|1] "" Vector__XXX
 SG_ Led0396_fault : 395|1@1+ (1,0) [0|1] "" Vector__XXX
 SG_ Led0395_fault : 394|1@1+ (1,0) [0|1] "" Vector__XXX
 SG_ Led0394_fault : 393|1@1+ (1,0) [0|1] "" Vector__XXX
 SG_ Led0393_fault : 392|1@1+ (1,0) [0|1] "" Vector__XXX
 SG_ Led0392_fault : 391|1@1+ (1,0) [0|1] "" Vector__XXX
 SG_ Led0391_fault : 390|1@1+ (1,0) [0|1] "" Vector__XXX
 SG_ Led0390_fault : 389|1@1+ (1,0) [0|1] "" Vector__XXX
 SG_ Led0389_fault : 388|1@1+ (1,0) [0|1] "" Vector__XXX
 SG_ Led0388_fault : 387|1@1+ (1,0) [0|1] "" Vector__XXX
 SG_ Led0387_fault : 386|1@1+ (1,0) [0|1] "" Vector__XXX
 SG_ Led0386_fault : 385|1@1+ (1,0) [0|1] "" Vector__XXX
 SG_ Led0385_fault : 384|1@1+ (1,0) [0|1] "" Vector__XXX
 SG_ Led0384_fault : 383|1@1+ (1,0) [0|1] "" Vector__XXX
 SG_ Led0383_fault : 382|1@1+ (1,0) [0|1] "" Vector__XXX
 SG_ Led0382_fault : 381|1@1+ (1,0) [0|1] "" Vector__XXX
 SG_ Led0381_fault : 380|1@1+ (1,0) [0|1] "" Vector__XXX
 SG_ Led0380_fault : 379|1@1+ (1,0) [0|1] "" Vector__XXX
 SG_ Led0379_fault : 378|1@1+ (1,0) [0|1] "" Vector__XXX
 SG_ Led0378_fault : 377|1@1+ (1,0) [0|1] "" Vector__XXX
 SG_ Led0377_fault : 376|1@1+ (1,0) [0|1] "" Vector__XXX
 SG_ Led0376_fault : 375|1@1+ (1,0) [0|1] "" Vector__XXX
 SG_ Led0375_fault : 374|1@1+ (1,0) [0|1] "" Vector__XXX
 SG_ Led0374_fault : 373|1@1+ (1,0) [0|1] "" Vector__XXX
 SG_ Led0373_fault : 372|1@1+ (1,0) [0|1] "" Vector__XXX
 SG_ Led0372_fault : 371|1@1+ (1,0) [0|1] "" Vector__XXX
 SG_ Led0371_fault : 370|1@1+ (1,0) [0|1] "" Vector__XXX
 SG_ Led0370_fault : 369|1@1+ (1,0) [0|1] "" Vector__XXX
 SG_ Led0369_fault : 368|1@1+ (1,0) [0|1] "" Vector__XXX
 SG_ Led0368_fault : 367|1@1+ (1,0) [0|1] "" Vector__XXX
 SG_ Led0367_fault : 366|1@1+ (1,0) [0|1] "" Vector__XXX
 SG_ Led0366_fault : 365|1@1+ (1,0) [0|1] "" Vector__XXX
 SG_ Led0365_fault : 364|1@1+ (1,0) [0|1] "" Vector__XXX
 SG_ Led0364_fault : 363|1@1+ (1,0) [0|1] "" Vector__XXX
 SG_ Led0363_fault : 362|1@1+ (1,0) [0|1] "" Vector__XXX
 SG_ Led0362_fault : 361|1@1+ (1,0) [0|1] "" Vector__XXX
 SG_ Led0361_fault : 360|1@1+ (1,0) [0|1] "" Vector__XXX
 SG_ Led0360_fault : 359|1@1+ (1,0) [0|1] "" Vector__XXX
 SG_ Led0359_fault : 358|1@1+ (1,0) [0|1] "" Vector__XXX
 SG_ Led0358_fault : 357|1@1+ (1,0) [0|1] "" Vector__XXX
 SG_ Led0357_fault : 356|1@1+ (1,0) [0|1] "" Vector__XXX
 SG_ Led0356_fault : 355|1@1+ (1,0) [0|1] "" Vector__XXX
 SG_ Led0355_fault : 354|1@1+ (1,0) [0|1] "" Vector__XXX
 SG_ Led0354_fault : 353|1@1+ (1,0) [0|1] "" Vector__XXX
 SG_ Led0353_fault : 352|1@1+ (1,0) [0|1] "" Vector__XXX
 SG_ Led0352_fault : 351|1@1+ (1,0) [0|1] "" Vector__XXX
 SG_ Led0351_fault : 350|1@1+ (1,0) [0|1] "" Vector__XXX
 SG_ Led0350_fault : 349|1@1+ (1,0) [0|1] "" Vector__XXX
 SG_ Led0349_fault : 348|1@1+ (1,0) [0|1] "" Vector__XXX
 SG_ Led0348_fault : 347|1@1+ (1,0) [0|1] "" Vector__XXX
 SG_ Led0347_fault : 346|1@1+ (1,0) [0|1] "" Vector__XXX
 SG_ Led0346_fault : 345|1@1+ (1,0) [0|1] "" Vector__XXX
 SG_ Led0345_fault : 344|1@1+ (1,0) [0|1] "" Vector__XXX
 SG_ Led0344_fault : 343|1@1+ (1,0) [0|1] "" Vector__XXX
 SG_ Led0343_fault : 342|1@1+ (1,0) [0|1] "" Vector__XXX
 SG_ Led0342_fault : 341|1@1+ (1,0) [0|1] "" Vector__XXX
 SG_ Led0341_fault : 340|1@1+ (1,0) [0|1] "" Vector__XXX
 SG_ Led0340_fault : 339|1@1+ (1,0) [0|1] "" Vector__XXX
 SG_ Led0339_fault : 338|1@1+ (1,0) [0|1] "" Vector__XXX
 SG_ Led0338_fault : 337|1@1+ (1,0) [0|1] "" Vector__XXX
 SG_ Led0337_fault : 336|1@1+ (1,0) [0|1] "" Vector__XXX
 SG_ Led0336_fault : 335|1@1+ (1,0) [0|1] "" Vector__XXX
 SG_ Led0335_fault : 334|1@1+ (1,0) [0|1] "" Vector__XXX
 SG_ Led0334_fault : 333|1@1+ (1,0) [0|1] "" Vector__XXX
 SG_ Led0333_fault : 332|1@1+ (1,0) [0|1] "" Vector__XXX
 SG_ Led0332_fault : 331|1@1+ (1,0) [0|1] "" Vector__XXX
 SG_ Led0331_fault : 330|1@1+ (1,0) [0|1] "" Vector__XXX
 SG_ Led0330_fault : 329|1@1+ (1,0) [0|1] "" Vector__XXX
 SG_ Led0329_fault : 328|1@1+ (1,0) [0|1] "" Vector__XXX
 SG_ Led0328_fault : 327|1@1+ (1,0) [0|1] "" Vector__XXX
 SG_ Led0327_fault : 326|1@1+ (1,0) [0|1] "" Vector__XXX
 SG_ Led0326_fault : 325|1@1+ (1,0) [0|1] "" Vector__XXX
 SG_ Led0325_fault : 324|1@1+ (1,0) [0|1] "" Vector__XXX
 SG_ Led0324_fault : 323|1@1+ (1,0) [0|1] "" Vector__XXX
 SG_ Led0323_fault : 322|1@1+ (1,0) [0|1] "" Vector__XXX
 SG_ Led0322_fault : 321|1@1+ (1,0) [0|1] "" Vector__XXX
 SG_ Led0321_fault : 320|1@1+ (1,0) [0|1] "" Vector__XXX
 SG_ Led0320_fault : 319|1@1+ (1,0) [0|1] "" Vector__XXX
 SG_ Led0319_fault : 318|1@1+ (1,0) [0|1] "" Vector__XXX
 SG_ Led0318_fault : 317|1@1+ (1,0) [0|1] "" Vector__XXX
 SG_ Led0317_fault : 316|1@1+ (1,0) [0|1] "" Vector__XXX
 SG_ Led0316_fault : 315|1@1+ (1,0) [0|1] "" Vector__XXX
 SG_ Led0315_fault : 314|1@1+ (1,0) [0|1] "" Vector__XXX
 SG_ Led0314_fault : 313|1@1+ (1,0) [0|1] "" Vector__XXX
 SG_ Led0313_fault : 312|1@1+ (1,0) [0|1] "" Vector__XXX
 SG_ Led0312_fault : 311|1@1+ (1,0) [0|1] "" Vector__XXX
 SG_ Led0311_fault : 310|1@1+ (1,0) [0|1] "" Vector__XXX
 SG_ Led0310_fault : 309|1@1+ (1,0) [0|1] "" Vector__XXX
 SG_ Led0309_fault : 308|1@1+ (1,0) [0|1] "" Vector__XXX
 SG_ Led0308_fault : 307|1@1+ (1,0) [0|1] "" Vector__XXX
 SG_ Led0307_fault : 306|1@1+ (1,0) [0|1] "" Vector__XXX
 SG_ Led0306_fault : 305|1@1+ (1,0) [0|1] "" Vector__XXX
 SG_ Led0305_fault : 304|1@1+ (1,0) [0|1] "" Vector__XXX
 SG_ Led0304_fault : 303|1@1+ (1,0) [0|1] "" Vector__XXX
 SG_ Led0303_fault : 302|1@1+ (1,0) [0|1] "" Vector__XXX
 SG_ Led0302_fault : 301|1@1+ (1,0) [0|1] "" Vector__XXX
 SG_ Led0301_fault : 300|1@1+ (1,0) [0|1] "" Vector__XXX
 SG_ Led0300_fault : 299|1@1+ (1,0) [0|1] "" Vector__XXX
 SG_ Led0299_fault : 298|1@1+ (1,0) [0|1] "" Vector__XXX
 SG_ Led0298_fault : 297|1@1+ (1,0) [0|1] "" Vector__XXX
 SG_ Led0297_fault : 296|1@1+ (1,0) [0|1] "" Vector__XXX
 SG_ Led0296_fault : 295|1@1+ (1,0) [0|1] "" Vector__XXX
 SG_ Led0295_fault : 294|1@1+ (1,0) [0|1] "" Vector__XXX
 SG_ Led0294_fault : 293|1@1+ (1,0) [0|1] "" Vector__XXX
 SG_ Led0293_fault : 292|1@1+ (1,0) [0|1] "" Vector__XXX
 SG_ Led0292_fault : 291|1@1+ (1,0) [0|1] "" Vector__XXX
 SG_ Led0291_fault : 290|1@1+ (1,0) [0|1] "" Vector__XXX
 SG_ Led0290_fault : 289|1@1+ (1,0) [0|1] "" Vector__XXX
 SG_ Led0289_fault : 288|1@1+ (1,0) [0|1] "" Vector__XXX
 SG_ Led0288_fault : 287|1@1+ (1,0) [0|1] "" Vector__XXX
 SG_ Led0287_fault : 286|1@1+ (1,0) [0|1] "" Vector__XXX
 SG_ Led0286_fault : 285|1@1+ (1,0) [0|1] "" Vector__XXX
 SG_ Led0285_fault : 284|1@1+ (1,0) [0|1] "" Vector__XXX
 SG_ Led0284_fault : 283|1@1+ (1,0) [0|1] "" Vector__XXX
 SG_ Led0283_fault : 282|1@1+ (1,0) [0|1] "" Vector__XXX
 SG_ Led0282_fault : 281|1@1+ (1,0) [0|1] "" Vector__XXX
 SG_ Led0281_fault : 280|1@1+ (1,0) [0|1] "" Vector__XXX
 SG_ Led0280_fault : 279|1@1+ (1,0) [0|1] "" Vector__XXX
 SG_ Led0279_fault : 278|1@1+ (1,0) [0|1] "" Vector__XXX
 SG_ Led0278_fault : 277|1@1+ (1,0) [0|1] "" Vector__XXX
 SG_ Led0277_fault : 276|1@1+ (1,0) [0|1] "" Vector__XXX
 SG_ Led0276_fault : 275|1@1+ (1,0) [0|1] "" Vector__XXX
 SG_ Led0275_fault : 274|1@1+ (1,0) [0|1] "" Vector__XXX
 SG_ Led0274_fault : 273|1@1+ (1,0) [0|1] "" Vector__XXX
 SG_ Led0273_fault : 272|1@1+ (1,0) [0|1] "" Vector__XXX
 SG_ Led0272_fault : 271|1@1+ (1,0) [0|1] "" Vector__XXX
 SG_ Led0271_fault : 270|1@1+ (1,0) [0|1] "" Vector__XXX
 SG_ Led0270_fault : 269|1@1+ (1,0) [0|1] "" Vector__XXX
 SG_ Led0269_fault : 268|1@1+ (1,0) [0|1] "" Vector__XXX
 SG_ Led0268_fault : 267|1@1+ (1,0) [0|1] "" Vector__XXX
 SG_ Led0267_fault : 266|1@1+ (1,0) [0|1] "" Vector__XXX
 SG_ Led0266_fault : 265|1@1+ (1,0) [0|1] "" Vector__XXX
 SG_ Led0265_fault : 264|1@1+ (1,0) [0|1] "" Vector__XXX
 SG_ Led0264_fault : 263|1@1+ (1,0) [0|1] "" Vector__XXX
 SG_ Led0263_fault : 262|1@1+ (1,0) [0|1] "" Vector__XXX
 SG_ Led0262_fault : 261|1@1+ (1,0) [0|1] "" Vector__XXX
 SG_ Led0261_fault : 260|1@1+ (1,0) [0|1] "" Vector__XXX
 SG_ Led0260_fault : 259|1@1+ (1,0) [0|1] "" Vector__XXX
 SG_ Led0259_fault : 258|1@1+ (1,0) [0|1] "" Vector__XXX
 SG_ Led0258_fault : 257|1@1+ (1,0) [0|1] "" Vector__XXX
 SG_ Led0257_fault : 256|1@1+ (1,0) [0|1] "" Vector__XXX
 SG_ Led0256_fault : 255|1@1+ (1,0) [0|1] "" Vector__XXX
 SG_ Led0255_fault : 254|1@1+ (1,0) [0|1] "" Vector__XXX
 SG_ Led0254_fault : 253|1@1+ (1,0) [0|1] "" Vector__XXX
 SG_ Led0253_fault : 252|1@1+ (1,0) [0|1] "" Vector__XXX
 SG_ Led0252_fault : 251|1@1+ (1,0) [0|1] "" Vector__XXX
 SG_ Led0251_fault : 250|1@1+ (1,0) [0|1] "" Vector__XXX
 SG_ Led0250_fault : 249|1@1+ (1,0) [0|1] "" Vector__XXX
 SG_ Led0249_fault : 248|1@1+ (1,0) [0|1] "" Vector__XXX
 SG_ Led0248_fault : 247|1@1+ (1,0) [0|1] "" Vector__XXX
 SG_ Led0247_fault : 246|1@1+ (1,0) [0|1] "" Vector__XXX
 SG_ Led0246_fault : 245|1@1+ (1,0) [0|1] "" Vector__XXX
 SG_ Led0245_fault : 244|1@1+ (1,0) [0|1] "" Vector__XXX
 SG_ Led0244_fault : 243|1@1+ (1,0) [0|1] "" Vector__XXX
 SG_ Led0243_fault : 242|1@1+ (1,0) [0|1] "" Vector__XXX
 SG_ Led0242_fault : 241|1@1+ (1,0) [0|1] "" Vector__XXX
 SG_ Led0241_fault : 240|1@1+ (1,0) [0|1] "" Vector__XXX
 SG_ Led0240_fault : 239|1@1+ (1,0) [0|1] "" Vector__XXX
 SG_ Led0239_fault : 238|1@1+ (1,0) [0|1] "" Vector__XXX
 SG_ Led0238_fault : 237|1@1+ (1,0) [0|1] "" Vector__XXX
 SG_ Led0237_fault : 236|1@1+ (1,0) [0|1] "" Vector__XXX
 SG_ Led0236_fault : 235|1@1+ (1,0) [0|1] "" Vector__XXX
 SG_ Led0235_fault : 234|1@1+ (1,0) [0|1] "" Vector__XXX
 SG_ Led0234_fault : 233|1@1+ (1,0) [0|1] "" Vector__XXX
 SG_ Led0233_fault : 232|1@1+ (1,0) [0|1] "" Vector__XXX
 SG_ Led0232_fault : 231|1@1+ (1,0) [0|1] "" Vector__XXX
 SG_ Led0231_fault : 230|1@1+ (1,0) [0|1] "" Vector__XXX
 SG_ Led0230_fault : 229|1@1+ (1,0) [0|1] "" Vector__XXX
 SG_ Led0229_fault : 228|1@1+ (1,0) [0|1] "" Vector__XXX
 SG_ Led0228_fault : 227|1@1+ (1,0) [0|1] "" Vector__XXX
 SG_ Led0227_fault : 226|1@1+ (1,0) [0|1] "" Vector__XXX
 SG_ Led0226_fault : 225|1@1+ (1,0) [0|1] "" Vector__XXX
 SG_ Led0225_fault : 224|1@1+ (1,0) [0|1] "" Vector__XXX
 SG_ Led0224_fault : 223|1@1+ (1,0) [0|1] "" Vector__XXX
 SG_ Led0223_fault : 222|1@1+ (1,0) [0|1] "" Vector__XXX
 SG_ Led0222_fault : 221|1@1+ (1,0) [0|1] "" Vector__XXX
 SG_ Led0221_fault : 220|1@1+ (1,0) [0|1] "" Vector__XXX
 SG_ Led0220_fault : 219|1@1+ (1,0) [0|1] "" Vector__XXX
 SG_ Led0219_fault : 218|1@1+ (1,0) [0|1] "" Vector__XXX
 SG_ Led0218_fault : 217|1@1+ (1,0) [0|1] "" Vector__XXX
 SG_ Led0217_fault : 216|1@1+ (1,0) [0|1] "" Vector__XXX
 SG_ Led0216_fault : 215|1@1+ (1,0) [0|1] "" Vector__XXX
 SG_ Led0215_fault : 214|1@1+ (1,0) [0|1] "" Vector__XXX
 SG_ Led0214_fault : 213|1@1+ (1,0) [0|1] "" Vector__XXX
 SG_ Led0213_fault : 212|1@1+ (1,0) [0|1] "" Vector__XXX
 SG_ Led0212_fault : 211|1@1+ (1,0) [0|1] "" Vector__XXX
 SG_ Led0211_fault : 210|1@1+ (1,0) [0|1] "" Vector__XXX
 SG_ Led0210_fault : 209|1@1+ (1,0) [0|1] "" Vector__XXX
 SG_ Led0209_fault : 208|1@1+ (1,0) [0|1] "" Vector__XXX
 SG_ Led0208_fault : 207|1@1+ (1,0) [0|1] "" Vector__XXX
 SG_ Led0207_fault : 206|1@1+ (1,0) [0|1] "" Vector__XXX
 SG_ Led0206_fault : 205|1@1+ (1,0) [0|1] "" Vector__XXX
 SG_ Led0205_fault : 204|1@1+ (1,0) [0|1] "" Vector__XXX
 SG_ Led0204_fault : 203|1@1+ (1,0) [0|1] "" Vector__XXX
 SG_ Led0203_fault : 202|1@1+ (1,0) [0|1] "" Vector__XXX
 SG_ Led0202_fault : 201|1@1+ (1,0) [0|1] "" Vector__XXX
 SG_ Led0201_fault : 200|1@1+ (1,0) [0|1] "" Vector__XXX
 SG_ Led0200_fault : 199|1@1+ (1,0) [0|1] "" Vector__XXX
 SG_ Led0199_fault : 198|1@1+ (1,0) [0|1] "" Vector__XXX
 SG_ Led0198_fault : 197|1@1+ (1,0) [0|1] "" Vector__XXX
 SG_ Led0197_fault : 196|1@1+ (1,0) [0|1] "" Vector__XXX
 SG_ Led0196_fault : 195|1@1+ (1,0) [0|1] "" Vector__XXX
 SG_ Led0195_fault : 194|1@1+ (1,0) [0|1] "" Vector__XXX
 SG_ Led0194_fault : 193|1@1+ (1,0) [0|1] "" Vector__XXX
 SG_ Led0193_fault : 192|1@1+ (1,0) [0|1] "" Vector__XXX
 SG_ Led0192_fault : 191|1@1+ (1,0) [0|1] "" Vector__XXX
 SG_ Led0191_fault : 190|1@1+ (1,0) [0|1] "" Vector__XXX
 SG_ Led0190_fault : 189|1@1+ (1,0) [0|1] "" Vector__XXX
 SG_ Led0189_fault : 188|1@1+ (1,0) [0|1] "" Vector__XXX
 SG_ Led0188_fault : 187|1@1+ (1,0) [0|1] "" Vector__XXX
 SG_ Led0187_fault : 186|1@1+ (1,0) [0|1] "" Vector__XXX
 SG_ Led0186_fault : 185|1@1+ (1,0) [0|1] "" Vector__XXX
 SG_ Led0185_fault : 184|1@1+ (1,0) [0|1] "" Vector__XXX
 SG_ Led0184_fault : 183|1@1+ (1,0) [0|1] "" Vector__XXX
 SG_ Led0183_fault : 182|1@1+ (1,0) [0|1] "" Vector__XXX
 SG_ Led0182_fault : 181|1@1+ (1,0) [0|1] "" Vector__XXX
 SG_ Led0181_fault : 180|1@1+ (1,0) [0|1] "" Vector__XXX
 SG_ Led0180_fault : 179|1@1+ (1,0) [0|1] "" Vector__XXX
 SG_ Led0179_fault : 178|1@1+ (1,0) [0|1] "" Vector__XXX
 SG_ Led0178_fault : 177|1@1+ (1,0) [0|1] "" Vector__XXX
 SG_ Led0177_fault : 176|1@1+ (1,0) [0|1] "" Vector__XXX
 SG_ Led0176_fault : 175|1@1+ (1,0) [0|1] "" Vector__XXX
 SG_ Led0175_fault : 174|1@1+ (1,0) [0|1] "" Vector__XXX
 SG_ Led0174_fault : 173|1@1+ (1,0) [0|1] "" Vector__XXX
 SG_ Led0173_fault : 172|1@1+ (1,0) [0|1] "" Vector__XXX
 SG_ Led0172_fault : 171|1@1+ (1,0) [0|1] "" Vector__XXX
 SG_ Led0171_fault : 170|1@1+ (1,0) [0|1] "" Vector__XXX
 SG_ Led0170_fault : 169|1@1+ (1,0) [0|1] "" Vector__XXX
 SG_ Led0169_fault : 168|1@1+ (1,0) [0|1] "" Vector__XXX
 SG_ Led0168_fault : 167|1@1+ (1,0) [0|1] "" Vector__XXX
 SG_ Led0167_fault : 166|1@1+ (1,0) [0|1] "" Vector__XXX
 SG_ Led0166_fault : 165|1@1+ (1,0) [0|1] "" Vector__XXX
 SG_ Led0165_fault : 164|1@1+ (1,0) [0|1] "" Vector__XXX
 SG_ Led0164_fault : 163|1@1+ (1,0) [0|1] "" Vector__XXX
 SG_ Led0163_fault : 162|1@1+ (1,0) [0|1] "" Vector__XXX
 SG_ Led0162_fault : 161|1@1+ (1,0) [0|1] "" Vector__XXX
 SG_ Led0161_fault : 160|1@1+ (1,0) [0|1] "" Vector__XXX
 SG_ Led0160_fault : 159|1@1+ (1,0) [0|1] "" Vector__XXX
 SG_ Led0159_fault : 158|1@1+ (1,0) [0|1] "" Vector__XXX
 SG_ Led0158_fault : 157|1@1+ (1,0) [0|1] "" Vector__XXX
 SG_ Led0157_fault : 156|1@1+ (1,0) [0|1] "" Vector__XXX
 SG_ Led0156_fault : 155|1@1+ (1,0) [0|1] "" Vector__XXX
 SG_ Led0155_fault : 154|1@1+ (1,0) [0|1] "" Vector__XXX
 SG_ Led0154_fault : 153|1@1+ (1,0) [0|1] "" Vector__XXX
 SG_ Led0153_fault : 152|1@1+ (1,0) [0|1] "" Vector__XXX
 SG_ Led0152_fault : 151|1@1+ (1,0) [0|1] "" Vector__XXX
 SG_ Led0151_fault : 150|1@1+ (1,0) [0|1] "" Vector__XXX
 SG_ Led0150_fault : 149|1@1+ (1,0) [0|1] "" Vector__XXX
 SG_ Led0149_fault : 148|1@1+ (1,0) [0|1] "" Vector__XXX
 SG_ Led0148_fault : 147|1@1+ (1,0) [0|1] "" Vector__XXX
 SG_ Led0147_fault : 146|1@1+ (1,0) [0|1] "" Vector__XXX
 SG_ Led0146_fault : 145|1@1+ (1,0) [0|1] "" Vector__XXX
 SG_ Led0145_fault : 144|1@1+ (1,0) [0|1] "" Vector__XXX
 SG_ Led0144_fault : 143|1@1+ (1,0) [0|1] "" Vector__XXX
 SG_ Led0143_fault : 142|1@1+ (1,0) [0|1] "" Vector__XXX
 SG_ Led0142_fault : 141|1@1+ (1,0) [0|1] "" Vector__XXX
 SG_ Led0141_fault : 140|1@1+ (1,0) [0|1] "" Vector__XXX
 SG_ Led0140_fault : 139|1@1+ (1,0) [0|1] "" Vector__XXX
 SG_ Led0139_fault : 138|1@1+ (1,0) [0|1] "" Vector__XXX
 SG_ Led0138_fault : 137|1@1+ (1,0) [0|1] "" Vector__XXX
 SG_ Led0137_fault : 136|1@1+ (1,0) [0|1] "" Vector__XXX
 SG_ Led0136_fault : 135|1@1+ (1,0) [0|1] "" Vector__XXX
 SG_ Led0135_fault : 134|1@1+ (1,0) [0|1] "" Vector__XXX
 SG_ Led0134_fault : 133|1@1+ (1,0) [0|1] "" Vector__XXX
 SG_ Led0133_fault : 132|1@1+ (1,0) [0|1] "" Vector__XXX
 SG_ Led0132_fault : 131|1@1+ (1,0) [0|1] "" Vector__XXX
 SG_ Led0131_fault : 130|1@1+ (1,0) [0|1] "" Vector__XXX
 SG_ Led0130_fault : 129|1@1+ (1,0) [0|1] "" Vector__XXX
 SG_ Led0129_fault : 128|1@1+ (1,0) [0|1] "" Vector__XXX
 SG_ Led0128_fault : 127|1@1+ (1,0) [0|1] "" Vector__XXX
 SG_ Led0127_fault : 126|1@1+ (1,0) [0|1] "" Vector__XXX
 SG_ Led0126_fault : 125|1@1+ (1,0) [0|1] "" Vector__XXX
 SG_ Led0125_fault : 124|1@1+ (1,0) [0|1] "" Vector__XXX
 SG_ Led0124_fault : 123|1@1+ (1,0) [0|1] "" Vector__XXX
 SG_ Led0123_fault : 122|1@1+ (1,0) [0|1] "" Vector__XXX
 SG_ Led0122_fault : 121|1@1+ (1,0) [0|1] "" Vector__XXX
 SG_ Led0121_fault : 120|1@1+ (1,0) [0|1] "" Vector__XXX
 SG_ Led0120_fault : 119|1@1+ (1,0) [0|1] "" Vector__XXX
 SG_ Led0119_fault : 118|1@1+ (1,0) [0|1] "" Vector__XXX
 SG_ Led0118_fault : 117|1@1+ (1,0) [0|1] "" Vector__XXX
 SG_ Led0117_fault : 116|1@1+ (1,0) [0|1] "" Vector__XXX
 SG_ Led0116_fault : 115|1@1+ (1,0) [0|1] "" Vector__XXX
 SG_ Led0115_fault : 114|1@1+ (1,0) [0|1] "" Vector__XXX
 SG_ Led0114_fault : 113|1@1+ (1,0) [0|1] "" Vector__XXX
 SG_ Led0113_fault : 112|1@1+ (1,0) [0|1] "" Vector__XXX
 SG_ Led0112_fault : 111|1@1+ (1,0) [0|1] "" Vector__XXX
 SG_ Led0111_fault : 110|1@1+ (1,0) [0|1] "" Vector__XXX
 SG_ Led0110_fault : 109|1@1+ (1,0) [0|1] "" Vector__XXX
 SG_ Led0109_fault : 108|1@1+ (1,0) [0|1] "" Vector__XXX
 SG_ Led0108_fault : 107|1@1+ (1,0) [0|1] "" Vector__XXX
 SG_ Led0107_fault : 106|1@1+ (1,0) [0|1] "" Vector__XXX
 SG_ Led0106_fault : 105|1@1+ (1,0) [0|1] "" Vector__XXX
 SG_ Led0105_fault : 104|1@1+ (1,0) [0|1] "" Vector__XXX
 SG_ Led0104_fault : 103|1@1+ (1,0) [0|1] "" Vector__XXX
 SG_ Led0103_fault : 102|1@1+ (1,0) [0|1] "" Vector__XXX
 SG_ Led0102_fault : 101|1@1+ (1,0) [0|1] "" Vector__XXX
 SG_ Led0101_fault : 100|1@1+ (1,0) [0|1] "" Vector__XXX
 SG_ Led0100_fault : 99|1@1+ (1,0) [0|1] "" Vector__XXX
 SG_ Led0099_fault : 98|1@1+ (1,0) [0|1] "" Vector__XXX
 SG_ Led0098_fault : 97|1@1+ (1,0) [0|1] "" Vector__XXX
 SG_ Led0097_fault : 96|1@1+ (1,0) [0|1] "" Vector__XXX
 SG_ Led0096_fault : 95|1@1+ (1,0) [0|1] "" Vector__XXX
 SG_ Led0095_fault : 94|1@1+ (1,0) [0|1] "" Vector__XXX
 SG_ Led0094_fault : 93|1@1+ (1,0) [0|1] "" Vector__XXX
 SG_ Led0093_fault : 92|1@1+ (1,0) [0|1] "" Vector__XXX
 SG_ Led0092_fault : 91|1@1+ (1,0) [0|1] "" Vector__XXX
 SG_ Led0091_fault : 90|1@1+ (1,0) [0|1] "" Vector__XXX
 SG_ Led0090_fault : 89|1@1+ (1,0) [0|1] "" Vector__XXX
 SG_ Led0089_fault : 88|1@1+ (1,0) [0|1] "" Vector__XXX
 SG_ Led0088_fault : 87|1@1+ (1,0) [0|1] "" Vector__XXX
 SG_ Led0087_fault : 86|1@1+ (1,0) [0|1] "" Vector__XXX
 SG_ Led0086_fault : 85|1@1+ (1,0) [0|1] "" Vector__XXX
 SG_ Led0085_fault : 84|1@1+ (1,0) [0|1] "" Vector__XXX
 SG_ Led0084_fault : 83|1@1+ (1,0) [0|1] "" Vector__XXX
 SG_ Led0083_fault : 82|1@1+ (1,0) [0|1] "" Vector__XXX
 SG_ Led0082_fault : 81|1@1+ (1,0) [0|1] "" Vector__XXX
 SG_ Led0081_fault : 80|1@1+ (1,0) [0|1] "" Vector__XXX
 SG_ Led0080_fault : 79|1@1+ (1,0) [0|1] "" Vector__XXX
 SG_ Led0079_fault : 78|1@1+ (1,0) [0|1] "" Vector__XXX
 SG_ Led0078_fault : 77|1@1+ (1,0) [0|1] "" Vector__XXX
 SG_ Led0077_fault : 76|1@1+ (1,0) [0|1] "" Vector__XXX
 SG_ Led0076_fault : 75|1@1+ (1,0) [0|1] "" Vector__XXX
 SG_ Led0075_fault : 74|1@1+ (1,0) [0|1] "" Vector__XXX
 SG_ Led0074_fault : 73|1@1+ (1,0) [0|1] "" Vector__XXX
 SG_ Led0073_fault : 72|1@1+ (1,0) [0|1] "" Vector__XXX
 SG_ Led0072_fault : 71|1@1+ (1,0) [0|1] "" Vector__XXX
 SG_ Led0071_fault : 70|1@1+ (1,0) [0|1] "" Vector__XXX
 SG_ Led0070_fault : 69|1@1+ (1,0) [0|1] "" Vector__XXX
 SG_ Led0069_fault : 68|1@1+ (1,0) [0|1] "" Vector__XXX
 SG_ Led0068_fault : 67|1@1+ (1,0) [0|1] "" Vector__XXX
 SG_ Led0067_fault : 66|1@1+ (1,0) [0|1] "" Vector__XXX
 SG_ Led0066_fault : 65|1@1+ (1,0) [0|1] "" Vector__XXX
 SG_ Led0065_fault : 64|1@1+ (1,0) [0|1] "" Vector__XXX
 SG_ Led0064_fault : 63|1@1+ (1,0) [0|1] "" Vector__XXX
 SG_ Led0063_fault : 62|1@1+ (1,0) [0|1] "" Vector__XXX
 SG_ Led0062_fault : 61|1@1+ (1,0) [0|1] "" Vector__XXX
 SG_ Led0061_fault : 60|1@1+ (1,0) [0|1] "" Vector__XXX
 SG_ Led0060_fault : 59|1@1+ (1,0) [0|1] "" Vector__XXX
 SG_ Led0059_fault : 58|1@1+ (1,0) [0|1] "" Vector__XXX
 SG_ Led0058_fault : 57|1@1+ (1,0) [0|1] "" Vector__XXX
 SG_ Led0057_fault : 56|1@1+ (1,0) [0|1] "" Vector__XXX
 SG_ Led0056_fault : 55|1@1+ (1,0) [0|1] "" Vector__XXX
 SG_ Led0055_fault : 54|1@1+ (1,0) [0|1] "" Vector__XXX
 SG_ Led0054_fault : 53|1@1+ (1,0) [0|1] "" Vector__XXX
 SG_ Led0053_fault : 52|1@1+ (1,0) [0|1] "" Vector__XXX
 SG_ Led0052_fault : 51|1@1+ (1,0) [0|1] "" Vector__XXX
 SG_ Led0051_fault : 50|1@1+ (1,0) [0|1] "" Vector__XXX
 SG_ Led0050_fault : 49|1@1+ (1,0) [0|1] "" Vector__XXX
 SG_ Led0049_fault : 48|1@1+ (1,0) [0|1] "" Vector__XXX
 SG_ Led0048_fault : 47|1@1+ (1,0) [0|1] "" Vector__XXX
 SG_ Led0047_fault : 46|1@1+ (1,0) [0|1] "" Vector__XXX
 SG_ Led0046_fault : 45|1@1+ (1,0) [0|1] "" Vector__XXX
 SG_ Led0045_fault : 44|1@1+ (1,0) [0|1] "" Vector__XXX
 SG_ Led0044_fault : 43|1@1+ (1,0) [0|1] "" Vector__XXX
 SG_ Led0043_fault : 42|1@1+ (1,0) [0|1] "" Vector__XXX
 SG_ Led0042_fault : 41|1@1+ (1,0) [0|1] "" Vector__XXX
 SG_ Led0041_fault : 40|1@1+ (1,0) [0|1] "" Vector__XXX
 SG_ Led0040_fault : 39|1@1+ (1,0) [0|1] "" Vector__XXX
 SG_ Led0039_fault : 38|1@1+ (1,0) [0|1] "" Vector__XXX
 SG_ Led0038_fault : 37|1@1+ (1,0) [0|1] "" Vector__XXX
 SG_ Led0037_fault : 36|1@1+ (1,0) [0|1] "" Vector__XXX
 SG_ Led0036_fault : 35|1@1+ (1,0) [0|1] "" Vector__XXX
 SG_ Led0035_fault : 34|1@1+ (1,0) [0|1] "" Vector__XXX
 SG_ Led0034_fault : 33|1@1+ (1,0) [0|1] "" Vector__XXX
 SG_ Led0033_fault : 32|1@1+ (1,0) [0|1] "" Vector__XXX
 SG_ Led0032_fault : 31|1@1+ (1,0) [0|1] "" Vector__XXX
 SG_ Led0031_fault : 30|1@1+ (1,0) [0|1] "" Vector__XXX
 SG_ Led0030_fault : 29|1@1+ (1,0) [0|1] "" Vector__XXX
 SG_ Led0029_fault : 28|1@1+ (1,0) [0|1] "" Vector__XXX
 SG_ Led0028_fault : 27|1@1+ (1,0) [0|1] "" Vector__XXX
 SG_ Led0027_fault : 26|1@1+ (1,0) [0|1] "" Vector__XXX
 SG_ Led0026_fault : 25|1@1+ (1,0) [0|1] "" Vector__XXX
 SG_ Led0025_fault : 24|1@1+ (1,0) [0|1] "" Vector__XXX
 SG_ Led0024_fault : 23|1@1+ (1,0) [0|1] "" Vector__XXX
 SG_ Led0023_fault : 22|1@1+ (1,0) [0|1] "" Vector__XXX
 SG_ Led0022_fault : 21|1@1+ (1,0) [0|1] "" Vector__XXX
 SG_ Led0021_fault : 20|1@1+ (1,0) [0|1] "" Vector__XXX
 SG_ Led0020_fault : 19|1@1+ (1,0) [0|1] "" Vector__XXX
 SG_ Led0019_fault : 18|1@1+ (1,0) [0|1] "" Vector__XXX
 SG_ Led0018_fault : 17|1@1+ (1,0) [0|1] "" Vector__XXX
 SG_ Led0017_fault : 16|1@1+ (1,0) [0|1] "" Vector__XXX
 SG_ Led0016_fault : 15|1@1+ (1,0) [0|1] "" Vector__XXX
 SG_ Led0015_fault : 14|1@1+ (1,0) [0|1] "" Vector__XXX
 SG_ Led0014_fault : 13|1@1+ (1,0) [0|1] "" Vector__XXX
 SG_ Led0013_fault : 12|1@1+ (1,0) [0|1] "" Vector__XXX
 SG_ Led0012_fault : 11|1@1+ (1,0) [0|1] "" Vector__XXX
 SG_ Led0011_fault : 10|1@1+ (1,0) [0|1] "" Vector__XXX
 SG_ Led0010_fault : 9|1@1+ (1,0) [0|1] "" Vector__XXX
 SG_ Led0007_fault : 6|1@1+ (1,0) [0|1] "" Vector__XXX
 SG_ Led0009_fault : 8|1@1+ (1,0) [0|1] "" Vector__XXX
 SG_ Led0008_fault : 7|1@1+ (1,0) [0|1] "" Vector__XXX
 SG_ Led0006_fault : 5|1@1+ (1,0) [0|1] "" Vector__XXX
 SG_ Led0005_fault : 4|1@1+ (1,0) [0|1] "" Vector__XXX
 SG_ Led0004_fault : 3|1@1+ (1,0) [0|1] "" Vector__XXX
 SG_ Led0003_fault : 2|1@1+ (1,0) [0|1] "" Vector__XXX
 SG_ Led0002_fault : 1|1@1+ (1,0) [0|1] "" Vector__XXX
 SG_ Led0001_fault : 0|1@1+ (1,0) [0|1] "" Vector__XXX

BO_ 1700 Rear_FaultLed_Feedback_B_04: 64 LED_Driver
 SG_ Led0512_fault : 511|1@1+ (1,0) [0|1] "" Vector__XXX
 SG_ Led0511_fault : 510|1@1+ (1,0) [0|1] "" Vector__XXX
 SG_ Led0510_fault : 509|1@1+ (1,0) [0|1] "" Vector__XXX
 SG_ Led0509_fault : 508|1@1+ (1,0) [0|1] "" Vector__XXX
 SG_ Led0508_fault : 507|1@1+ (1,0) [0|1] "" Vector__XXX
 SG_ Led0507_fault : 506|1@1+ (1,0) [0|1] "" Vector__XXX
 SG_ Led0506_fault : 505|1@1+ (1,0) [0|1] "" Vector__XXX
 SG_ Led0505_fault : 504|1@1+ (1,0) [0|1] "" Vector__XXX
 SG_ Led0504_fault : 503|1@1+ (1,0) [0|1] "" Vector__XXX
 SG_ Led0503_fault : 502|1@1+ (1,0) [0|1] "" Vector__XXX
 SG_ Led0502_fault : 501|1@1+ (1,0) [0|1] "" Vector__XXX
 SG_ Led0501_fault : 500|1@1+ (1,0) [0|1] "" Vector__XXX
 SG_ Led0500_fault : 499|1@1+ (1,0) [0|1] "" Vector__XXX
 SG_ Led0499_fault : 498|1@1+ (1,0) [0|1] "" Vector__XXX
 SG_ Led0498_fault : 497|1@1+ (1,0) [0|1] "" Vector__XXX
 SG_ Led0497_fault : 496|1@1+ (1,0) [0|1] "" Vector__XXX
 SG_ Led0496_fault : 495|1@1+ (1,0) [0|1] "" Vector__XXX
 SG_ Led0495_fault : 494|1@1+ (1,0) [0|1] "" Vector__XXX
 SG_ Led0494_fault : 493|1@1+ (1,0) [0|1] "" Vector__XXX
 SG_ Led0493_fault : 492|1@1+ (1,0) [0|1] "" Vector__XXX
 SG_ Led0492_fault : 491|1@1+ (1,0) [0|1] "" Vector__XXX
 SG_ Led0491_fault : 490|1@1+ (1,0) [0|1] "" Vector__XXX
 SG_ Led0490_fault : 489|1@1+ (1,0) [0|1] "" Vector__XXX
 SG_ Led0489_fault : 488|1@1+ (1,0) [0|1] "" Vector__XXX
 SG_ Led0488_fault : 487|1@1+ (1,0) [0|1] "" Vector__XXX
 SG_ Led0487_fault : 486|1@1+ (1,0) [0|1] "" Vector__XXX
 SG_ Led0486_fault : 485|1@1+ (1,0) [0|1] "" Vector__XXX
 SG_ Led0485_fault : 484|1@1+ (1,0) [0|1] "" Vector__XXX
 SG_ Led0484_fault : 483|1@1+ (1,0) [0|1] "" Vector__XXX
 SG_ Led0483_fault : 482|1@1+ (1,0) [0|1] "" Vector__XXX
 SG_ Led0482_fault : 481|1@1+ (1,0) [0|1] "" Vector__XXX
 SG_ Led0481_fault : 480|1@1+ (1,0) [0|1] "" Vector__XXX
 SG_ Led0480_fault : 479|1@1+ (1,0) [0|1] "" Vector__XXX
 SG_ Led0479_fault : 478|1@1+ (1,0) [0|1] "" Vector__XXX
 SG_ Led0478_fault : 477|1@1+ (1,0) [0|1] "" Vector__XXX
 SG_ Led0477_fault : 476|1@1+ (1,0) [0|1] "" Vector__XXX
 SG_ Led0476_fault : 475|1@1+ (1,0) [0|1] "" Vector__XXX
 SG_ Led0475_fault : 474|1@1+ (1,0) [0|1] "" Vector__XXX
 SG_ Led0474_fault : 473|1@1+ (1,0) [0|1] "" Vector__XXX
 SG_ Led0473_fault : 472|1@1+ (1,0) [0|1] "" Vector__XXX
 SG_ Led0472_fault : 471|1@1+ (1,0) [0|1] "" Vector__XXX
 SG_ Led0471_fault : 470|1@1+ (1,0) [0|1] "" Vector__XXX
 SG_ Led0470_fault : 469|1@1+ (1,0) [0|1] "" Vector__XXX
 SG_ Led0469_fault : 468|1@1+ (1,0) [0|1] "" Vector__XXX
 SG_ Led0468_fault : 467|1@1+ (1,0) [0|1] "" Vector__XXX
 SG_ Led0467_fault : 466|1@1+ (1,0) [0|1] "" Vector__XXX
 SG_ Led0466_fault : 465|1@1+ (1,0) [0|1] "" Vector__XXX
 SG_ Led0465_fault : 464|1@1+ (1,0) [0|1] "" Vector__XXX
 SG_ Led0464_fault : 463|1@1+ (1,0) [0|1] "" Vector__XXX
 SG_ Led0463_fault : 462|1@1+ (1,0) [0|1] "" Vector__XXX
 SG_ Led0462_fault : 461|1@1+ (1,0) [0|1] "" Vector__XXX
 SG_ Led0461_fault : 460|1@1+ (1,0) [0|1] "" Vector__XXX
 SG_ Led0460_fault : 459|1@1+ (1,0) [0|1] "" Vector__XXX
 SG_ Led0459_fault : 458|1@1+ (1,0) [0|1] "" Vector__XXX
 SG_ Led0458_fault : 457|1@1+ (1,0) [0|1] "" Vector__XXX
 SG_ Led0457_fault : 456|1@1+ (1,0) [0|1] "" Vector__XXX
 SG_ Led0456_fault : 455|1@1+ (1,0) [0|1] "" Vector__XXX
 SG_ Led0455_fault : 454|1@1+ (1,0) [0|1] "" Vector__XXX
 SG_ Led0454_fault : 453|1@1+ (1,0) [0|1] "" Vector__XXX
 SG_ Led0453_fault : 452|1@1+ (1,0) [0|1] "" Vector__XXX
 SG_ Led0452_fault : 451|1@1+ (1,0) [0|1] "" Vector__XXX
 SG_ Led0451_fault : 450|1@1+ (1,0) [0|1] "" Vector__XXX
 SG_ Led0450_fault : 449|1@1+ (1,0) [0|1] "" Vector__XXX
 SG_ Led0449_fault : 448|1@1+ (1,0) [0|1] "" Vector__XXX
 SG_ Led0448_fault : 447|1@1+ (1,0) [0|1] "" Vector__XXX
 SG_ Led0447_fault : 446|1@1+ (1,0) [0|1] "" Vector__XXX
 SG_ Led0446_fault : 445|1@1+ (1,0) [0|1] "" Vector__XXX
 SG_ Led0445_fault : 444|1@1+ (1,0) [0|1] "" Vector__XXX
 SG_ Led0444_fault : 443|1@1+ (1,0) [0|1] "" Vector__XXX
 SG_ Led0443_fault : 442|1@1+ (1,0) [0|1] "" Vector__XXX
 SG_ Led0442_fault : 441|1@1+ (1,0) [0|1] "" Vector__XXX
 SG_ Led0441_fault : 440|1@1+ (1,0) [0|1] "" Vector__XXX
 SG_ Led0440_fault : 439|1@1+ (1,0) [0|1] "" Vector__XXX
 SG_ Led0439_fault : 438|1@1+ (1,0) [0|1] "" Vector__XXX
 SG_ Led0438_fault : 437|1@1+ (1,0) [0|1] "" Vector__XXX
 SG_ Led0437_fault : 436|1@1+ (1,0) [0|1] "" Vector__XXX
 SG_ Led0436_fault : 435|1@1+ (1,0) [0|1] "" Vector__XXX
 SG_ Led0435_fault : 434|1@1+ (1,0) [0|1] "" Vector__XXX
 SG_ Led0434_fault : 433|1@1+ (1,0) [0|1] "" Vector__XXX
 SG_ Led0433_fault : 432|1@1+ (1,0) [0|1] "" Vector__XXX
 SG_ Led0432_fault : 431|1@1+ (1,0) [0|1] "" Vector__XXX
 SG_ Led0431_fault : 430|1@1+ (1,0) [0|1] "" Vector__XXX
 SG_ Led0430_fault : 429|1@1+ (1,0) [0|1] "" Vector__XXX
 SG_ Led0429_fault : 428|1@1+ (1,0) [0|1] "" Vector__XXX
 SG_ Led0428_fault : 427|1@1+ (1,0) [0|1] "" Vector__XXX
 SG_ Led0427_fault : 426|1@1+ (1,0) [0|1] "" Vector__XXX
 SG_ Led0426_fault : 425|1@1+ (1,0) [0|1] "" Vector__XXX
 SG_ Led0425_fault : 424|1@1+ (1,0) [0|1] "" Vector__XXX
 SG_ Led0424_fault : 423|1@1+ (1,0) [0|1] "" Vector__XXX
 SG_ Led0423_fault : 422|1@1+ (1,0) [0|1] "" Vector__XXX
 SG_ Led0422_fault : 421|1@1+ (1,0) [0|1] "" Vector__XXX
 SG_ Led0421_fault : 420|1@1+ (1,0) [0|1] "" Vector__XXX
 SG_ Led0420_fault : 419|1@1+ (1,0) [0|1] "" Vector__XXX
 SG_ Led0419_fault : 418|1@1+ (1,0) [0|1] "" Vector__XXX
 SG_ Led0418_fault : 417|1@1+ (1,0) [0|1] "" Vector__XXX
 SG_ Led0417_fault : 416|1@1+ (1,0) [0|1] "" Vector__XXX
 SG_ Led0416_fault : 415|1@1+ (1,0) [0|1] "" Vector__XXX
 SG_ Led0415_fault : 414|1@1+ (1,0) [0|1] "" Vector__XXX
 SG_ Led0414_fault : 413|1@1+ (1,0) [0|1] "" Vector__XXX
 SG_ Led0413_fault : 412|1@1+ (1,0) [0|1] "" Vector__XXX
 SG_ Led0412_fault : 411|1@1+ (1,0) [0|1] "" Vector__XXX
 SG_ Led0411_fault : 410|1@1+ (1,0) [0|1] "" Vector__XXX
 SG_ Led0410_fault : 409|1@1+ (1,0) [0|1] "" Vector__XXX
 SG_ Led0409_fault : 408|1@1+ (1,0) [0|1] "" Vector__XXX
 SG_ Led0408_fault : 407|1@1+ (1,0) [0|1] "" Vector__XXX
 SG_ Led0407_fault : 406|1@1+ (1,0) [0|1] "" Vector__XXX
 SG_ Led0406_fault : 405|1@1+ (1,0) [0|1] "" Vector__XXX
 SG_ Led0405_fault : 404|1@1+ (1,0) [0|1] "" Vector__XXX
 SG_ Led0404_fault : 403|1@1+ (1,0) [0|1] "" Vector__XXX
 SG_ Led0403_fault : 402|1@1+ (1,0) [0|1] "" Vector__XXX
 SG_ Led0402_fault : 401|1@1+ (1,0) [0|1] "" Vector__XXX
 SG_ Led0401_fault : 400|1@1+ (1,0) [0|1] "" Vector__XXX
 SG_ Led0400_fault : 399|1@1+ (1,0) [0|1] "" Vector__XXX
 SG_ Led0399_fault : 398|1@1+ (1,0) [0|1] "" Vector__XXX
 SG_ Led0398_fault : 397|1@1+ (1,0) [0|1] "" Vector__XXX
 SG_ Led0397_fault : 396|1@1+ (1,0) [0|1] "" Vector__XXX
 SG_ Led0396_fault : 395|1@1+ (1,0) [0|1] "" Vector__XXX
 SG_ Led0395_fault : 394|1@1+ (1,0) [0|1] "" Vector__XXX
 SG_ Led0394_fault : 393|1@1+ (1,0) [0|1] "" Vector__XXX
 SG_ Led0393_fault : 392|1@1+ (1,0) [0|1] "" Vector__XXX
 SG_ Led0392_fault : 391|1@1+ (1,0) [0|1] "" Vector__XXX
 SG_ Led0391_fault : 390|1@1+ (1,0) [0|1] "" Vector__XXX
 SG_ Led0390_fault : 389|1@1+ (1,0) [0|1] "" Vector__XXX
 SG_ Led0389_fault : 388|1@1+ (1,0) [0|1] "" Vector__XXX
 SG_ Led0388_fault : 387|1@1+ (1,0) [0|1] "" Vector__XXX
 SG_ Led0387_fault : 386|1@1+ (1,0) [0|1] "" Vector__XXX
 SG_ Led0386_fault : 385|1@1+ (1,0) [0|1] "" Vector__XXX
 SG_ Led0385_fault : 384|1@1+ (1,0) [0|1] "" Vector__XXX
 SG_ Led0384_fault : 383|1@1+ (1,0) [0|1] "" Vector__XXX
 SG_ Led0383_fault : 382|1@1+ (1,0) [0|1] "" Vector__XXX
 SG_ Led0382_fault : 381|1@1+ (1,0) [0|1] "" Vector__XXX
 SG_ Led0381_fault : 380|1@1+ (1,0) [0|1] "" Vector__XXX
 SG_ Led0380_fault : 379|1@1+ (1,0) [0|1] "" Vector__XXX
 SG_ Led0379_fault : 378|1@1+ (1,0) [0|1] "" Vector__XXX
 SG_ Led0378_fault : 377|1@1+ (1,0) [0|1] "" Vector__XXX
 SG_ Led0377_fault : 376|1@1+ (1,0) [0|1] "" Vector__XXX
 SG_ Led0376_fault : 375|1@1+ (1,0) [0|1] "" Vector__XXX
 SG_ Led0375_fault : 374|1@1+ (1,0) [0|1] "" Vector__XXX
 SG_ Led0374_fault : 373|1@1+ (1,0) [0|1] "" Vector__XXX
 SG_ Led0373_fault : 372|1@1+ (1,0) [0|1] "" Vector__XXX
 SG_ Led0372_fault : 371|1@1+ (1,0) [0|1] "" Vector__XXX
 SG_ Led0371_fault : 370|1@1+ (1,0) [0|1] "" Vector__XXX
 SG_ Led0370_fault : 369|1@1+ (1,0) [0|1] "" Vector__XXX
 SG_ Led0369_fault : 368|1@1+ (1,0) [0|1] "" Vector__XXX
 SG_ Led0368_fault : 367|1@1+ (1,0) [0|1] "" Vector__XXX
 SG_ Led0367_fault : 366|1@1+ (1,0) [0|1] "" Vector__XXX
 SG_ Led0366_fault : 365|1@1+ (1,0) [0|1] "" Vector__XXX
 SG_ Led0365_fault : 364|1@1+ (1,0) [0|1] "" Vector__XXX
 SG_ Led0364_fault : 363|1@1+ (1,0) [0|1] "" Vector__XXX
 SG_ Led0363_fault : 362|1@1+ (1,0) [0|1] "" Vector__XXX
 SG_ Led0362_fault : 361|1@1+ (1,0) [0|1] "" Vector__XXX
 SG_ Led0361_fault : 360|1@1+ (1,0) [0|1] "" Vector__XXX
 SG_ Led0360_fault : 359|1@1+ (1,0) [0|1] "" Vector__XXX
 SG_ Led0359_fault : 358|1@1+ (1,0) [0|1] "" Vector__XXX
 SG_ Led0358_fault : 357|1@1+ (1,0) [0|1] "" Vector__XXX
 SG_ Led0357_fault : 356|1@1+ (1,0) [0|1] "" Vector__XXX
 SG_ Led0356_fault : 355|1@1+ (1,0) [0|1] "" Vector__XXX
 SG_ Led0355_fault : 354|1@1+ (1,0) [0|1] "" Vector__XXX
 SG_ Led0354_fault : 353|1@1+ (1,0) [0|1] "" Vector__XXX
 SG_ Led0353_fault : 352|1@1+ (1,0) [0|1] "" Vector__XXX
 SG_ Led0352_fault : 351|1@1+ (1,0) [0|1] "" Vector__XXX
 SG_ Led0351_fault : 350|1@1+ (1,0) [0|1] "" Vector__XXX
 SG_ Led0350_fault : 349|1@1+ (1,0) [0|1] "" Vector__XXX
 SG_ Led0349_fault : 348|1@1+ (1,0) [0|1] "" Vector__XXX
 SG_ Led0348_fault : 347|1@1+ (1,0) [0|1] "" Vector__XXX
 SG_ Led0347_fault : 346|1@1+ (1,0) [0|1] "" Vector__XXX
 SG_ Led0346_fault : 345|1@1+ (1,0) [0|1] "" Vector__XXX
 SG_ Led0345_fault : 344|1@1+ (1,0) [0|1] "" Vector__XXX
 SG_ Led0344_fault : 343|1@1+ (1,0) [0|1] "" Vector__XXX
 SG_ Led0343_fault : 342|1@1+ (1,0) [0|1] "" Vector__XXX
 SG_ Led0342_fault : 341|1@1+ (1,0) [0|1] "" Vector__XXX
 SG_ Led0341_fault : 340|1@1+ (1,0) [0|1] "" Vector__XXX
 SG_ Led0340_fault : 339|1@1+ (1,0) [0|1] "" Vector__XXX
 SG_ Led0339_fault : 338|1@1+ (1,0) [0|1] "" Vector__XXX
 SG_ Led0338_fault : 337|1@1+ (1,0) [0|1] "" Vector__XXX
 SG_ Led0337_fault : 336|1@1+ (1,0) [0|1] "" Vector__XXX
 SG_ Led0336_fault : 335|1@1+ (1,0) [0|1] "" Vector__XXX
 SG_ Led0335_fault : 334|1@1+ (1,0) [0|1] "" Vector__XXX
 SG_ Led0334_fault : 333|1@1+ (1,0) [0|1] "" Vector__XXX
 SG_ Led0333_fault : 332|1@1+ (1,0) [0|1] "" Vector__XXX
 SG_ Led0332_fault : 331|1@1+ (1,0) [0|1] "" Vector__XXX
 SG_ Led0331_fault : 330|1@1+ (1,0) [0|1] "" Vector__XXX
 SG_ Led0330_fault : 329|1@1+ (1,0) [0|1] "" Vector__XXX
 SG_ Led0329_fault : 328|1@1+ (1,0) [0|1] "" Vector__XXX
 SG_ Led0328_fault : 327|1@1+ (1,0) [0|1] "" Vector__XXX
 SG_ Led0327_fault : 326|1@1+ (1,0) [0|1] "" Vector__XXX
 SG_ Led0326_fault : 325|1@1+ (1,0) [0|1] "" Vector__XXX
 SG_ Led0325_fault : 324|1@1+ (1,0) [0|1] "" Vector__XXX
 SG_ Led0324_fault : 323|1@1+ (1,0) [0|1] "" Vector__XXX
 SG_ Led0323_fault : 322|1@1+ (1,0) [0|1] "" Vector__XXX
 SG_ Led0322_fault : 321|1@1+ (1,0) [0|1] "" Vector__XXX
 SG_ Led0321_fault : 320|1@1+ (1,0) [0|1] "" Vector__XXX
 SG_ Led0320_fault : 319|1@1+ (1,0) [0|1] "" Vector__XXX
 SG_ Led0319_fault : 318|1@1+ (1,0) [0|1] "" Vector__XXX
 SG_ Led0318_fault : 317|1@1+ (1,0) [0|1] "" Vector__XXX
 SG_ Led0317_fault : 316|1@1+ (1,0) [0|1] "" Vector__XXX
 SG_ Led0316_fault : 315|1@1+ (1,0) [0|1] "" Vector__XXX
 SG_ Led0315_fault : 314|1@1+ (1,0) [0|1] "" Vector__XXX
 SG_ Led0314_fault : 313|1@1+ (1,0) [0|1] "" Vector__XXX
 SG_ Led0313_fault : 312|1@1+ (1,0) [0|1] "" Vector__XXX
 SG_ Led0312_fault : 311|1@1+ (1,0) [0|1] "" Vector__XXX
 SG_ Led0311_fault : 310|1@1+ (1,0) [0|1] "" Vector__XXX
 SG_ Led0310_fault : 309|1@1+ (1,0) [0|1] "" Vector__XXX
 SG_ Led0309_fault : 308|1@1+ (1,0) [0|1] "" Vector__XXX
 SG_ Led0308_fault : 307|1@1+ (1,0) [0|1] "" Vector__XXX
 SG_ Led0307_fault : 306|1@1+ (1,0) [0|1] "" Vector__XXX
 SG_ Led0306_fault : 305|1@1+ (1,0) [0|1] "" Vector__XXX
 SG_ Led0305_fault : 304|1@1+ (1,0) [0|1] "" Vector__XXX
 SG_ Led0304_fault : 303|1@1+ (1,0) [0|1] "" Vector__XXX
 SG_ Led0303_fault : 302|1@1+ (1,0) [0|1] "" Vector__XXX
 SG_ Led0302_fault : 301|1@1+ (1,0) [0|1] "" Vector__XXX
 SG_ Led0301_fault : 300|1@1+ (1,0) [0|1] "" Vector__XXX
 SG_ Led0300_fault : 299|1@1+ (1,0) [0|1] "" Vector__XXX
 SG_ Led0299_fault : 298|1@1+ (1,0) [0|1] "" Vector__XXX
 SG_ Led0298_fault : 297|1@1+ (1,0) [0|1] "" Vector__XXX
 SG_ Led0297_fault : 296|1@1+ (1,0) [0|1] "" Vector__XXX
 SG_ Led0296_fault : 295|1@1+ (1,0) [0|1] "" Vector__XXX
 SG_ Led0295_fault : 294|1@1+ (1,0) [0|1] "" Vector__XXX
 SG_ Led0294_fault : 293|1@1+ (1,0) [0|1] "" Vector__XXX
 SG_ Led0293_fault : 292|1@1+ (1,0) [0|1] "" Vector__XXX
 SG_ Led0292_fault : 291|1@1+ (1,0) [0|1] "" Vector__XXX
 SG_ Led0291_fault : 290|1@1+ (1,0) [0|1] "" Vector__XXX
 SG_ Led0290_fault : 289|1@1+ (1,0) [0|1] "" Vector__XXX
 SG_ Led0289_fault : 288|1@1+ (1,0) [0|1] "" Vector__XXX
 SG_ Led0288_fault : 287|1@1+ (1,0) [0|1] "" Vector__XXX
 SG_ Led0287_fault : 286|1@1+ (1,0) [0|1] "" Vector__XXX
 SG_ Led0286_fault : 285|1@1+ (1,0) [0|1] "" Vector__XXX
 SG_ Led0285_fault : 284|1@1+ (1,0) [0|1] "" Vector__XXX
 SG_ Led0284_fault : 283|1@1+ (1,0) [0|1] "" Vector__XXX
 SG_ Led0283_fault : 282|1@1+ (1,0) [0|1] "" Vector__XXX
 SG_ Led0282_fault : 281|1@1+ (1,0) [0|1] "" Vector__XXX
 SG_ Led0281_fault : 280|1@1+ (1,0) [0|1] "" Vector__XXX
 SG_ Led0280_fault : 279|1@1+ (1,0) [0|1] "" Vector__XXX
 SG_ Led0279_fault : 278|1@1+ (1,0) [0|1] "" Vector__XXX
 SG_ Led0278_fault : 277|1@1+ (1,0) [0|1] "" Vector__XXX
 SG_ Led0277_fault : 276|1@1+ (1,0) [0|1] "" Vector__XXX
 SG_ Led0276_fault : 275|1@1+ (1,0) [0|1] "" Vector__XXX
 SG_ Led0275_fault : 274|1@1+ (1,0) [0|1] "" Vector__XXX
 SG_ Led0274_fault : 273|1@1+ (1,0) [0|1] "" Vector__XXX
 SG_ Led0273_fault : 272|1@1+ (1,0) [0|1] "" Vector__XXX
 SG_ Led0272_fault : 271|1@1+ (1,0) [0|1] "" Vector__XXX
 SG_ Led0271_fault : 270|1@1+ (1,0) [0|1] "" Vector__XXX
 SG_ Led0270_fault : 269|1@1+ (1,0) [0|1] "" Vector__XXX
 SG_ Led0269_fault : 268|1@1+ (1,0) [0|1] "" Vector__XXX
 SG_ Led0268_fault : 267|1@1+ (1,0) [0|1] "" Vector__XXX
 SG_ Led0267_fault : 266|1@1+ (1,0) [0|1] "" Vector__XXX
 SG_ Led0266_fault : 265|1@1+ (1,0) [0|1] "" Vector__XXX
 SG_ Led0265_fault : 264|1@1+ (1,0) [0|1] "" Vector__XXX
 SG_ Led0264_fault : 263|1@1+ (1,0) [0|1] "" Vector__XXX
 SG_ Led0263_fault : 262|1@1+ (1,0) [0|1] "" Vector__XXX
 SG_ Led0262_fault : 261|1@1+ (1,0) [0|1] "" Vector__XXX
 SG_ Led0261_fault : 260|1@1+ (1,0) [0|1] "" Vector__XXX
 SG_ Led0260_fault : 259|1@1+ (1,0) [0|1] "" Vector__XXX
 SG_ Led0259_fault : 258|1@1+ (1,0) [0|1] "" Vector__XXX
 SG_ Led0258_fault : 257|1@1+ (1,0) [0|1] "" Vector__XXX
 SG_ Led0257_fault : 256|1@1+ (1,0) [0|1] "" Vector__XXX
 SG_ Led0256_fault : 255|1@1+ (1,0) [0|1] "" Vector__XXX
 SG_ Led0255_fault : 254|1@1+ (1,0) [0|1] "" Vector__XXX
 SG_ Led0254_fault : 253|1@1+ (1,0) [0|1] "" Vector__XXX
 SG_ Led0253_fault : 252|1@1+ (1,0) [0|1] "" Vector__XXX
 SG_ Led0252_fault : 251|1@1+ (1,0) [0|1] "" Vector__XXX
 SG_ Led0251_fault : 250|1@1+ (1,0) [0|1] "" Vector__XXX
 SG_ Led0250_fault : 249|1@1+ (1,0) [0|1] "" Vector__XXX
 SG_ Led0249_fault : 248|1@1+ (1,0) [0|1] "" Vector__XXX
 SG_ Led0248_fault : 247|1@1+ (1,0) [0|1] "" Vector__XXX
 SG_ Led0247_fault : 246|1@1+ (1,0) [0|1] "" Vector__XXX
 SG_ Led0246_fault : 245|1@1+ (1,0) [0|1] "" Vector__XXX
 SG_ Led0245_fault : 244|1@1+ (1,0) [0|1] "" Vector__XXX
 SG_ Led0244_fault : 243|1@1+ (1,0) [0|1] "" Vector__XXX
 SG_ Led0243_fault : 242|1@1+ (1,0) [0|1] "" Vector__XXX
 SG_ Led0242_fault : 241|1@1+ (1,0) [0|1] "" Vector__XXX
 SG_ Led0241_fault : 240|1@1+ (1,0) [0|1] "" Vector__XXX
 SG_ Led0240_fault : 239|1@1+ (1,0) [0|1] "" Vector__XXX
 SG_ Led0239_fault : 238|1@1+ (1,0) [0|1] "" Vector__XXX
 SG_ Led0238_fault : 237|1@1+ (1,0) [0|1] "" Vector__XXX
 SG_ Led0237_fault : 236|1@1+ (1,0) [0|1] "" Vector__XXX
 SG_ Led0236_fault : 235|1@1+ (1,0) [0|1] "" Vector__XXX
 SG_ Led0235_fault : 234|1@1+ (1,0) [0|1] "" Vector__XXX
 SG_ Led0234_fault : 233|1@1+ (1,0) [0|1] "" Vector__XXX
 SG_ Led0233_fault : 232|1@1+ (1,0) [0|1] "" Vector__XXX
 SG_ Led0232_fault : 231|1@1+ (1,0) [0|1] "" Vector__XXX
 SG_ Led0231_fault : 230|1@1+ (1,0) [0|1] "" Vector__XXX
 SG_ Led0230_fault : 229|1@1+ (1,0) [0|1] "" Vector__XXX
 SG_ Led0229_fault : 228|1@1+ (1,0) [0|1] "" Vector__XXX
 SG_ Led0228_fault : 227|1@1+ (1,0) [0|1] "" Vector__XXX
 SG_ Led0227_fault : 226|1@1+ (1,0) [0|1] "" Vector__XXX
 SG_ Led0226_fault : 225|1@1+ (1,0) [0|1] "" Vector__XXX
 SG_ Led0225_fault : 224|1@1+ (1,0) [0|1] "" Vector__XXX
 SG_ Led0224_fault : 223|1@1+ (1,0) [0|1] "" Vector__XXX
 SG_ Led0223_fault : 222|1@1+ (1,0) [0|1] "" Vector__XXX
 SG_ Led0222_fault : 221|1@1+ (1,0) [0|1] "" Vector__XXX
 SG_ Led0221_fault : 220|1@1+ (1,0) [0|1] "" Vector__XXX
 SG_ Led0220_fault : 219|1@1+ (1,0) [0|1] "" Vector__XXX
 SG_ Led0219_fault : 218|1@1+ (1,0) [0|1] "" Vector__XXX
 SG_ Led0218_fault : 217|1@1+ (1,0) [0|1] "" Vector__XXX
 SG_ Led0217_fault : 216|1@1+ (1,0) [0|1] "" Vector__XXX
 SG_ Led0216_fault : 215|1@1+ (1,0) [0|1] "" Vector__XXX
 SG_ Led0215_fault : 214|1@1+ (1,0) [0|1] "" Vector__XXX
 SG_ Led0214_fault : 213|1@1+ (1,0) [0|1] "" Vector__XXX
 SG_ Led0213_fault : 212|1@1+ (1,0) [0|1] "" Vector__XXX
 SG_ Led0212_fault : 211|1@1+ (1,0) [0|1] "" Vector__XXX
 SG_ Led0211_fault : 210|1@1+ (1,0) [0|1] "" Vector__XXX
 SG_ Led0210_fault : 209|1@1+ (1,0) [0|1] "" Vector__XXX
 SG_ Led0209_fault : 208|1@1+ (1,0) [0|1] "" Vector__XXX
 SG_ Led0208_fault : 207|1@1+ (1,0) [0|1] "" Vector__XXX
 SG_ Led0207_fault : 206|1@1+ (1,0) [0|1] "" Vector__XXX
 SG_ Led0206_fault : 205|1@1+ (1,0) [0|1] "" Vector__XXX
 SG_ Led0205_fault : 204|1@1+ (1,0) [0|1] "" Vector__XXX
 SG_ Led0204_fault : 203|1@1+ (1,0) [0|1] "" Vector__XXX
 SG_ Led0203_fault : 202|1@1+ (1,0) [0|1] "" Vector__XXX
 SG_ Led0202_fault : 201|1@1+ (1,0) [0|1] "" Vector__XXX
 SG_ Led0201_fault : 200|1@1+ (1,0) [0|1] "" Vector__XXX
 SG_ Led0200_fault : 199|1@1+ (1,0) [0|1] "" Vector__XXX
 SG_ Led0199_fault : 198|1@1+ (1,0) [0|1] "" Vector__XXX
 SG_ Led0198_fault : 197|1@1+ (1,0) [0|1] "" Vector__XXX
 SG_ Led0197_fault : 196|1@1+ (1,0) [0|1] "" Vector__XXX
 SG_ Led0196_fault : 195|1@1+ (1,0) [0|1] "" Vector__XXX
 SG_ Led0195_fault : 194|1@1+ (1,0) [0|1] "" Vector__XXX
 SG_ Led0194_fault : 193|1@1+ (1,0) [0|1] "" Vector__XXX
 SG_ Led0193_fault : 192|1@1+ (1,0) [0|1] "" Vector__XXX
 SG_ Led0192_fault : 191|1@1+ (1,0) [0|1] "" Vector__XXX
 SG_ Led0191_fault : 190|1@1+ (1,0) [0|1] "" Vector__XXX
 SG_ Led0190_fault : 189|1@1+ (1,0) [0|1] "" Vector__XXX
 SG_ Led0189_fault : 188|1@1+ (1,0) [0|1] "" Vector__XXX
 SG_ Led0188_fault : 187|1@1+ (1,0) [0|1] "" Vector__XXX
 SG_ Led0187_fault : 186|1@1+ (1,0) [0|1] "" Vector__XXX
 SG_ Led0186_fault : 185|1@1+ (1,0) [0|1] "" Vector__XXX
 SG_ Led0185_fault : 184|1@1+ (1,0) [0|1] "" Vector__XXX
 SG_ Led0184_fault : 183|1@1+ (1,0) [0|1] "" Vector__XXX
 SG_ Led0183_fault : 182|1@1+ (1,0) [0|1] "" Vector__XXX
 SG_ Led0182_fault : 181|1@1+ (1,0) [0|1] "" Vector__XXX
 SG_ Led0181_fault : 180|1@1+ (1,0) [0|1] "" Vector__XXX
 SG_ Led0180_fault : 179|1@1+ (1,0) [0|1] "" Vector__XXX
 SG_ Led0179_fault : 178|1@1+ (1,0) [0|1] "" Vector__XXX
 SG_ Led0178_fault : 177|1@1+ (1,0) [0|1] "" Vector__XXX
 SG_ Led0177_fault : 176|1@1+ (1,0) [0|1] "" Vector__XXX
 SG_ Led0176_fault : 175|1@1+ (1,0) [0|1] "" Vector__XXX
 SG_ Led0175_fault : 174|1@1+ (1,0) [0|1] "" Vector__XXX
 SG_ Led0174_fault : 173|1@1+ (1,0) [0|1] "" Vector__XXX
 SG_ Led0173_fault : 172|1@1+ (1,0) [0|1] "" Vector__XXX
 SG_ Led0172_fault : 171|1@1+ (1,0) [0|1] "" Vector__XXX
 SG_ Led0171_fault : 170|1@1+ (1,0) [0|1] "" Vector__XXX
 SG_ Led0170_fault : 169|1@1+ (1,0) [0|1] "" Vector__XXX
 SG_ Led0169_fault : 168|1@1+ (1,0) [0|1] "" Vector__XXX
 SG_ Led0168_fault : 167|1@1+ (1,0) [0|1] "" Vector__XXX
 SG_ Led0167_fault : 166|1@1+ (1,0) [0|1] "" Vector__XXX
 SG_ Led0166_fault : 165|1@1+ (1,0) [0|1] "" Vector__XXX
 SG_ Led0165_fault : 164|1@1+ (1,0) [0|1] "" Vector__XXX
 SG_ Led0164_fault : 163|1@1+ (1,0) [0|1] "" Vector__XXX
 SG_ Led0163_fault : 162|1@1+ (1,0) [0|1] "" Vector__XXX
 SG_ Led0162_fault : 161|1@1+ (1,0) [0|1] "" Vector__XXX
 SG_ Led0161_fault : 160|1@1+ (1,0) [0|1] "" Vector__XXX
 SG_ Led0160_fault : 159|1@1+ (1,0) [0|1] "" Vector__XXX
 SG_ Led0159_fault : 158|1@1+ (1,0) [0|1] "" Vector__XXX
 SG_ Led0158_fault : 157|1@1+ (1,0) [0|1] "" Vector__XXX
 SG_ Led0157_fault : 156|1@1+ (1,0) [0|1] "" Vector__XXX
 SG_ Led0156_fault : 155|1@1+ (1,0) [0|1] "" Vector__XXX
 SG_ Led0155_fault : 154|1@1+ (1,0) [0|1] "" Vector__XXX
 SG_ Led0154_fault : 153|1@1+ (1,0) [0|1] "" Vector__XXX
 SG_ Led0153_fault : 152|1@1+ (1,0) [0|1] "" Vector__XXX
 SG_ Led0152_fault : 151|1@1+ (1,0) [0|1] "" Vector__XXX
 SG_ Led0151_fault : 150|1@1+ (1,0) [0|1] "" Vector__XXX
 SG_ Led0150_fault : 149|1@1+ (1,0) [0|1] "" Vector__XXX
 SG_ Led0149_fault : 148|1@1+ (1,0) [0|1] "" Vector__XXX
 SG_ Led0148_fault : 147|1@1+ (1,0) [0|1] "" Vector__XXX
 SG_ Led0147_fault : 146|1@1+ (1,0) [0|1] "" Vector__XXX
 SG_ Led0146_fault : 145|1@1+ (1,0) [0|1] "" Vector__XXX
 SG_ Led0145_fault : 144|1@1+ (1,0) [0|1] "" Vector__XXX
 SG_ Led0144_fault : 143|1@1+ (1,0) [0|1] "" Vector__XXX
 SG_ Led0143_fault : 142|1@1+ (1,0) [0|1] "" Vector__XXX
 SG_ Led0142_fault : 141|1@1+ (1,0) [0|1] "" Vector__XXX
 SG_ Led0141_fault : 140|1@1+ (1,0) [0|1] "" Vector__XXX
 SG_ Led0140_fault : 139|1@1+ (1,0) [0|1] "" Vector__XXX
 SG_ Led0139_fault : 138|1@1+ (1,0) [0|1] "" Vector__XXX
 SG_ Led0138_fault : 137|1@1+ (1,0) [0|1] "" Vector__XXX
 SG_ Led0137_fault : 136|1@1+ (1,0) [0|1] "" Vector__XXX
 SG_ Led0136_fault : 135|1@1+ (1,0) [0|1] "" Vector__XXX
 SG_ Led0135_fault : 134|1@1+ (1,0) [0|1] "" Vector__XXX
 SG_ Led0134_fault : 133|1@1+ (1,0) [0|1] "" Vector__XXX
 SG_ Led0133_fault : 132|1@1+ (1,0) [0|1] "" Vector__XXX
 SG_ Led0132_fault : 131|1@1+ (1,0) [0|1] "" Vector__XXX
 SG_ Led0131_fault : 130|1@1+ (1,0) [0|1] "" Vector__XXX
 SG_ Led0130_fault : 129|1@1+ (1,0) [0|1] "" Vector__XXX
 SG_ Led0129_fault : 128|1@1+ (1,0) [0|1] "" Vector__XXX
 SG_ Led0128_fault : 127|1@1+ (1,0) [0|1] "" Vector__XXX
 SG_ Led0127_fault : 126|1@1+ (1,0) [0|1] "" Vector__XXX
 SG_ Led0126_fault : 125|1@1+ (1,0) [0|1] "" Vector__XXX
 SG_ Led0125_fault : 124|1@1+ (1,0) [0|1] "" Vector__XXX
 SG_ Led0124_fault : 123|1@1+ (1,0) [0|1] "" Vector__XXX
 SG_ Led0123_fault : 122|1@1+ (1,0) [0|1] "" Vector__XXX
 SG_ Led0122_fault : 121|1@1+ (1,0) [0|1] "" Vector__XXX
 SG_ Led0121_fault : 120|1@1+ (1,0) [0|1] "" Vector__XXX
 SG_ Led0120_fault : 119|1@1+ (1,0) [0|1] "" Vector__XXX
 SG_ Led0119_fault : 118|1@1+ (1,0) [0|1] "" Vector__XXX
 SG_ Led0118_fault : 117|1@1+ (1,0) [0|1] "" Vector__XXX
 SG_ Led0117_fault : 116|1@1+ (1,0) [0|1] "" Vector__XXX
 SG_ Led0116_fault : 115|1@1+ (1,0) [0|1] "" Vector__XXX
 SG_ Led0115_fault : 114|1@1+ (1,0) [0|1] "" Vector__XXX
 SG_ Led0114_fault : 113|1@1+ (1,0) [0|1] "" Vector__XXX
 SG_ Led0113_fault : 112|1@1+ (1,0) [0|1] "" Vector__XXX
 SG_ Led0112_fault : 111|1@1+ (1,0) [0|1] "" Vector__XXX
 SG_ Led0111_fault : 110|1@1+ (1,0) [0|1] "" Vector__XXX
 SG_ Led0110_fault : 109|1@1+ (1,0) [0|1] "" Vector__XXX
 SG_ Led0109_fault : 108|1@1+ (1,0) [0|1] "" Vector__XXX
 SG_ Led0108_fault : 107|1@1+ (1,0) [0|1] "" Vector__XXX
 SG_ Led0107_fault : 106|1@1+ (1,0) [0|1] "" Vector__XXX
 SG_ Led0106_fault : 105|1@1+ (1,0) [0|1] "" Vector__XXX
 SG_ Led0105_fault : 104|1@1+ (1,0) [0|1] "" Vector__XXX
 SG_ Led0104_fault : 103|1@1+ (1,0) [0|1] "" Vector__XXX
 SG_ Led0103_fault : 102|1@1+ (1,0) [0|1] "" Vector__XXX
 SG_ Led0102_fault : 101|1@1+ (1,0) [0|1] "" Vector__XXX
 SG_ Led0101_fault : 100|1@1+ (1,0) [0|1] "" Vector__XXX
 SG_ Led0100_fault : 99|1@1+ (1,0) [0|1] "" Vector__XXX
 SG_ Led0099_fault : 98|1@1+ (1,0) [0|1] "" Vector__XXX
 SG_ Led0098_fault : 97|1@1+ (1,0) [0|1] "" Vector__XXX
 SG_ Led0097_fault : 96|1@1+ (1,0) [0|1] "" Vector__XXX
 SG_ Led0096_fault : 95|1@1+ (1,0) [0|1] "" Vector__XXX
 SG_ Led0095_fault : 94|1@1+ (1,0) [0|1] "" Vector__XXX
 SG_ Led0094_fault : 93|1@1+ (1,0) [0|1] "" Vector__XXX
 SG_ Led0093_fault : 92|1@1+ (1,0) [0|1] "" Vector__XXX
 SG_ Led0092_fault : 91|1@1+ (1,0) [0|1] "" Vector__XXX
 SG_ Led0091_fault : 90|1@1+ (1,0) [0|1] "" Vector__XXX
 SG_ Led0090_fault : 89|1@1+ (1,0) [0|1] "" Vector__XXX
 SG_ Led0089_fault : 88|1@1+ (1,0) [0|1] "" Vector__XXX
 SG_ Led0088_fault : 87|1@1+ (1,0) [0|1] "" Vector__XXX
 SG_ Led0087_fault : 86|1@1+ (1,0) [0|1] "" Vector__XXX
 SG_ Led0086_fault : 85|1@1+ (1,0) [0|1] "" Vector__XXX
 SG_ Led0085_fault : 84|1@1+ (1,0) [0|1] "" Vector__XXX
 SG_ Led0084_fault : 83|1@1+ (1,0) [0|1] "" Vector__XXX
 SG_ Led0083_fault : 82|1@1+ (1,0) [0|1] "" Vector__XXX
 SG_ Led0082_fault : 81|1@1+ (1,0) [0|1] "" Vector__XXX
 SG_ Led0081_fault : 80|1@1+ (1,0) [0|1] "" Vector__XXX
 SG_ Led0080_fault : 79|1@1+ (1,0) [0|1] "" Vector__XXX
 SG_ Led0079_fault : 78|1@1+ (1,0) [0|1] "" Vector__XXX
 SG_ Led0078_fault : 77|1@1+ (1,0) [0|1] "" Vector__XXX
 SG_ Led0077_fault : 76|1@1+ (1,0) [0|1] "" Vector__XXX
 SG_ Led0076_fault : 75|1@1+ (1,0) [0|1] "" Vector__XXX
 SG_ Led0075_fault : 74|1@1+ (1,0) [0|1] "" Vector__XXX
 SG_ Led0074_fault : 73|1@1+ (1,0) [0|1] "" Vector__XXX
 SG_ Led0073_fault : 72|1@1+ (1,0) [0|1] "" Vector__XXX
 SG_ Led0072_fault : 71|1@1+ (1,0) [0|1] "" Vector__XXX
 SG_ Led0071_fault : 70|1@1+ (1,0) [0|1] "" Vector__XXX
 SG_ Led0070_fault : 69|1@1+ (1,0) [0|1] "" Vector__XXX
 SG_ Led0069_fault : 68|1@1+ (1,0) [0|1] "" Vector__XXX
 SG_ Led0068_fault : 67|1@1+ (1,0) [0|1] "" Vector__XXX
 SG_ Led0067_fault : 66|1@1+ (1,0) [0|1] "" Vector__XXX
 SG_ Led0066_fault : 65|1@1+ (1,0) [0|1] "" Vector__XXX
 SG_ Led0065_fault : 64|1@1+ (1,0) [0|1] "" Vector__XXX
 SG_ Led0064_fault : 63|1@1+ (1,0) [0|1] "" Vector__XXX
 SG_ Led0063_fault : 62|1@1+ (1,0) [0|1] "" Vector__XXX
 SG_ Led0062_fault : 61|1@1+ (1,0) [0|1] "" Vector__XXX
 SG_ Led0061_fault : 60|1@1+ (1,0) [0|1] "" Vector__XXX
 SG_ Led0060_fault : 59|1@1+ (1,0) [0|1] "" Vector__XXX
 SG_ Led0059_fault : 58|1@1+ (1,0) [0|1] "" Vector__XXX
 SG_ Led0058_fault : 57|1@1+ (1,0) [0|1] "" Vector__XXX
 SG_ Led0057_fault : 56|1@1+ (1,0) [0|1] "" Vector__XXX
 SG_ Led0056_fault : 55|1@1+ (1,0) [0|1] "" Vector__XXX
 SG_ Led0055_fault : 54|1@1+ (1,0) [0|1] "" Vector__XXX
 SG_ Led0054_fault : 53|1@1+ (1,0) [0|1] "" Vector__XXX
 SG_ Led0053_fault : 52|1@1+ (1,0) [0|1] "" Vector__XXX
 SG_ Led0052_fault : 51|1@1+ (1,0) [0|1] "" Vector__XXX
 SG_ Led0051_fault : 50|1@1+ (1,0) [0|1] "" Vector__XXX
 SG_ Led0050_fault : 49|1@1+ (1,0) [0|1] "" Vector__XXX
 SG_ Led0049_fault : 48|1@1+ (1,0) [0|1] "" Vector__XXX
 SG_ Led0048_fault : 47|1@1+ (1,0) [0|1] "" Vector__XXX
 SG_ Led0047_fault : 46|1@1+ (1,0) [0|1] "" Vector__XXX
 SG_ Led0046_fault : 45|1@1+ (1,0) [0|1] "" Vector__XXX
 SG_ Led0045_fault : 44|1@1+ (1,0) [0|1] "" Vector__XXX
 SG_ Led0044_fault : 43|1@1+ (1,0) [0|1] "" Vector__XXX
 SG_ Led0043_fault : 42|1@1+ (1,0) [0|1] "" Vector__XXX
 SG_ Led0042_fault : 41|1@1+ (1,0) [0|1] "" Vector__XXX
 SG_ Led0041_fault : 40|1@1+ (1,0) [0|1] "" Vector__XXX
 SG_ Led0040_fault : 39|1@1+ (1,0) [0|1] "" Vector__XXX
 SG_ Led0039_fault : 38|1@1+ (1,0) [0|1] "" Vector__XXX
 SG_ Led0038_fault : 37|1@1+ (1,0) [0|1] "" Vector__XXX
 SG_ Led0037_fault : 36|1@1+ (1,0) [0|1] "" Vector__XXX
 SG_ Led0036_fault : 35|1@1+ (1,0) [0|1] "" Vector__XXX
 SG_ Led0035_fault : 34|1@1+ (1,0) [0|1] "" Vector__XXX
 SG_ Led0034_fault : 33|1@1+ (1,0) [0|1] "" Vector__XXX
 SG_ Led0033_fault : 32|1@1+ (1,0) [0|1] "" Vector__XXX
 SG_ Led0032_fault : 31|1@1+ (1,0) [0|1] "" Vector__XXX
 SG_ Led0031_fault : 30|1@1+ (1,0) [0|1] "" Vector__XXX
 SG_ Led0030_fault : 29|1@1+ (1,0) [0|1] "" Vector__XXX
 SG_ Led0029_fault : 28|1@1+ (1,0) [0|1] "" Vector__XXX
 SG_ Led0028_fault : 27|1@1+ (1,0) [0|1] "" Vector__XXX
 SG_ Led0027_fault : 26|1@1+ (1,0) [0|1] "" Vector__XXX
 SG_ Led0026_fault : 25|1@1+ (1,0) [0|1] "" Vector__XXX
 SG_ Led0025_fault : 24|1@1+ (1,0) [0|1] "" Vector__XXX
 SG_ Led0024_fault : 23|1@1+ (1,0) [0|1] "" Vector__XXX
 SG_ Led0023_fault : 22|1@1+ (1,0) [0|1] "" Vector__XXX
 SG_ Led0022_fault : 21|1@1+ (1,0) [0|1] "" Vector__XXX
 SG_ Led0021_fault : 20|1@1+ (1,0) [0|1] "" Vector__XXX
 SG_ Led0020_fault : 19|1@1+ (1,0) [0|1] "" Vector__XXX
 SG_ Led0019_fault : 18|1@1+ (1,0) [0|1] "" Vector__XXX
 SG_ Led0018_fault : 17|1@1+ (1,0) [0|1] "" Vector__XXX
 SG_ Led0017_fault : 16|1@1+ (1,0) [0|1] "" Vector__XXX
 SG_ Led0016_fault : 15|1@1+ (1,0) [0|1] "" Vector__XXX
 SG_ Led0015_fault : 14|1@1+ (1,0) [0|1] "" Vector__XXX
 SG_ Led0014_fault : 13|1@1+ (1,0) [0|1] "" Vector__XXX
 SG_ Led0013_fault : 12|1@1+ (1,0) [0|1] "" Vector__XXX
 SG_ Led0012_fault : 11|1@1+ (1,0) [0|1] "" Vector__XXX
 SG_ Led0011_fault : 10|1@1+ (1,0) [0|1] "" Vector__XXX
 SG_ Led0010_fault : 9|1@1+ (1,0) [0|1] "" Vector__XXX
 SG_ Led0007_fault : 6|1@1+ (1,0) [0|1] "" Vector__XXX
 SG_ Led0009_fault : 8|1@1+ (1,0) [0|1] "" Vector__XXX
 SG_ Led0008_fault : 7|1@1+ (1,0) [0|1] "" Vector__XXX
 SG_ Led0006_fault : 5|1@1+ (1,0) [0|1] "" Vector__XXX
 SG_ Led0005_fault : 4|1@1+ (1,0) [0|1] "" Vector__XXX
 SG_ Led0004_fault : 3|1@1+ (1,0) [0|1] "" Vector__XXX
 SG_ Led0003_fault : 2|1@1+ (1,0) [0|1] "" Vector__XXX
 SG_ Led0002_fault : 1|1@1+ (1,0) [0|1] "" Vector__XXX
 SG_ Led0001_fault : 0|1@1+ (1,0) [0|1] "" Vector__XXX

CM_ BO_ 3221225472 "This is a message for not used signals, created by Vector CANdb++ DBC OLE DB Provider.";
CM_ BO_ 1280 "ISC控制后右A灯1~64 灰度信息帧";
CM_ BO_ 768 "ISC控制后左A灯1~64 灰度信息帧";
CM_ BO_ 1024 "ISC控制后B灯1~64 灰度信息帧";
CM_ BO_ 1713 "后右A灯1~299 的LED 故障反馈帧";
CM_ BO_ 1712 "后右A灯 的LED Driver反馈帧";
CM_ SG_ 1712 C_Led_Fault "C灯故障";
CM_ SG_ 1712 Led_Driver_Internal_Fault "LED Driver内部故障";
CM_ SG_ 1712 Led_Driver_High_Temp_Fault "LED Driver高温故障";
CM_ SG_ 1712 Led_Driver_Low_Voltage_Fault "LED Driver低压故障";
CM_ SG_ 1712 Led_Driver_High_Voltage_Fault "LED Driver高压故障";
CM_ SG_ 1712 Break_Sts "刹车灯信号状态";
CM_ SG_ 1712 Turn_Sts "转向灯信号状态";
CM_ SG_ 1712 Led_Driver_WorkSts "LED Driver工作状态";
CM_ BO_ 1701 "后B灯2049~2463 的LED 故障反馈帧";
CM_ BO_ 1700 "后B灯1537~2048 的LED 故障反馈帧";
BA_DEF_ BO_  "CANFD_BRS" ENUM  "0","1";
BA_DEF_  "DBName" STRING ;
BA_DEF_  "BusType" STRING ;
BA_DEF_ BO_  "VFrameFormat" ENUM  "StandardCAN","ExtendedCAN","reserved","reserved","reserved","reserved","reserved","reserved","reserved","reserved","reserved","reserved","reserved","reserved","StandardCAN_FD","ExtendedCAN_FD";
BA_DEF_DEF_  "CANFD_BRS" "1";
BA_DEF_DEF_  "DBName" "";
BA_DEF_DEF_  "BusType" "";
BA_DEF_DEF_  "VFrameFormat" "StandardCAN";
BA_ "BusType" "CAN FD";
BA_ "DBName" "S11L";
BA_ "VFrameFormat" BO_ 1280 14;
BA_ "VFrameFormat" BO_ 768 14;
BA_ "VFrameFormat" BO_ 1024 14;
BA_ "VFrameFormat" BO_ 1713 14;
BA_ "VFrameFormat" BO_ 1712 14;
BA_ "VFrameFormat" BO_ 1701 14;
BA_ "VFrameFormat" BO_ 1700 14;
VAL_ 1713 Led0299_fault 1 "fault" 0 "normal" ;
VAL_ 1713 Led0298_fault 1 "fault" 0 "normal" ;
VAL_ 1713 Led0297_fault 1 "fault" 0 "normal" ;
VAL_ 1713 Led0296_fault 1 "fault" 0 "normal" ;
VAL_ 1713 Led0295_fault 1 "fault" 0 "normal" ;
VAL_ 1713 Led0294_fault 1 "fault" 0 "normal" ;
VAL_ 1713 Led0293_fault 1 "fault" 0 "normal" ;
VAL_ 1713 Led0292_fault 1 "fault" 0 "normal" ;
VAL_ 1713 Led0291_fault 1 "fault" 0 "normal" ;
VAL_ 1713 Led0290_fault 1 "fault" 0 "normal" ;
VAL_ 1713 Led0289_fault 1 "fault" 0 "normal" ;
VAL_ 1713 Led0288_fault 1 "fault" 0 "normal" ;
VAL_ 1713 Led0287_fault 1 "fault" 0 "normal" ;
VAL_ 1713 Led0286_fault 1 "fault" 0 "normal" ;
VAL_ 1713 Led0285_fault 1 "fault" 0 "normal" ;
VAL_ 1713 Led0284_fault 1 "fault" 0 "normal" ;
VAL_ 1713 Led0283_fault 1 "fault" 0 "normal" ;
VAL_ 1713 Led0282_fault 1 "fault" 0 "normal" ;
VAL_ 1713 Led0281_fault 1 "fault" 0 "normal" ;
VAL_ 1713 Led0280_fault 1 "fault" 0 "normal" ;
VAL_ 1713 Led0279_fault 1 "fault" 0 "normal" ;
VAL_ 1713 Led0278_fault 1 "fault" 0 "normal" ;
VAL_ 1713 Led0277_fault 1 "fault" 0 "normal" ;
VAL_ 1713 Led0276_fault 1 "fault" 0 "normal" ;
VAL_ 1713 Led0275_fault 1 "fault" 0 "normal" ;
VAL_ 1713 Led0274_fault 1 "fault" 0 "normal" ;
VAL_ 1713 Led0273_fault 1 "fault" 0 "normal" ;
VAL_ 1713 Led0272_fault 1 "fault" 0 "normal" ;
VAL_ 1713 Led0271_fault 1 "fault" 0 "normal" ;
VAL_ 1713 Led0270_fault 1 "fault" 0 "normal" ;
VAL_ 1713 Led0269_fault 1 "fault" 0 "normal" ;
VAL_ 1713 Led0268_fault 1 "fault" 0 "normal" ;
VAL_ 1713 Led0267_fault 1 "fault" 0 "normal" ;
VAL_ 1713 Led0266_fault 1 "fault" 0 "normal" ;
VAL_ 1713 Led0265_fault 1 "fault" 0 "normal" ;
VAL_ 1713 Led0264_fault 1 "fault" 0 "normal" ;
VAL_ 1713 Led0263_fault 1 "fault" 0 "normal" ;
VAL_ 1713 Led0262_fault 1 "fault" 0 "normal" ;
VAL_ 1713 Led0261_fault 1 "fault" 0 "normal" ;
VAL_ 1713 Led0260_fault 1 "fault" 0 "normal" ;
VAL_ 1713 Led0259_fault 1 "fault" 0 "normal" ;
VAL_ 1713 Led0258_fault 1 "fault" 0 "normal" ;
VAL_ 1713 Led0257_fault 1 "fault" 0 "normal" ;
VAL_ 1713 Led0256_fault 1 "fault" 0 "normal" ;
VAL_ 1713 Led0255_fault 1 "fault" 0 "normal" ;
VAL_ 1713 Led0254_fault 1 "fault" 0 "normal" ;
VAL_ 1713 Led0253_fault 1 "fault" 0 "normal" ;
VAL_ 1713 Led0252_fault 1 "fault" 0 "normal" ;
VAL_ 1713 Led0251_fault 1 "fault" 0 "normal" ;
VAL_ 1713 Led0250_fault 1 "fault" 0 "normal" ;
VAL_ 1713 Led0249_fault 1 "fault" 0 "normal" ;
VAL_ 1713 Led0248_fault 1 "fault" 0 "normal" ;
VAL_ 1713 Led0247_fault 1 "fault" 0 "normal" ;
VAL_ 1713 Led0246_fault 1 "fault" 0 "normal" ;
VAL_ 1713 Led0245_fault 1 "fault" 0 "normal" ;
VAL_ 1713 Led0244_fault 1 "fault" 0 "normal" ;
VAL_ 1713 Led0243_fault 1 "fault" 0 "normal" ;
VAL_ 1713 Led0242_fault 1 "fault" 0 "normal" ;
VAL_ 1713 Led0241_fault 1 "fault" 0 "normal" ;
VAL_ 1713 Led0240_fault 1 "fault" 0 "normal" ;
VAL_ 1713 Led0239_fault 1 "fault" 0 "normal" ;
VAL_ 1713 Led0238_fault 1 "fault" 0 "normal" ;
VAL_ 1713 Led0237_fault 1 "fault" 0 "normal" ;
VAL_ 1713 Led0236_fault 1 "fault" 0 "normal" ;
VAL_ 1713 Led0235_fault 1 "fault" 0 "normal" ;
VAL_ 1713 Led0234_fault 1 "fault" 0 "normal" ;
VAL_ 1713 Led0233_fault 1 "fault" 0 "normal" ;
VAL_ 1713 Led0232_fault 1 "fault" 0 "normal" ;
VAL_ 1713 Led0231_fault 1 "fault" 0 "normal" ;
VAL_ 1713 Led0230_fault 1 "fault" 0 "normal" ;
VAL_ 1713 Led0229_fault 1 "fault" 0 "normal" ;
VAL_ 1713 Led0228_fault 1 "fault" 0 "normal" ;
VAL_ 1713 Led0227_fault 1 "fault" 0 "normal" ;
VAL_ 1713 Led0226_fault 1 "fault" 0 "normal" ;
VAL_ 1713 Led0225_fault 1 "fault" 0 "normal" ;
VAL_ 1713 Led0224_fault 1 "fault" 0 "normal" ;
VAL_ 1713 Led0223_fault 1 "fault" 0 "normal" ;
VAL_ 1713 Led0222_fault 1 "fault" 0 "normal" ;
VAL_ 1713 Led0221_fault 1 "fault" 0 "normal" ;
VAL_ 1713 Led0220_fault 1 "fault" 0 "normal" ;
VAL_ 1713 Led0219_fault 1 "fault" 0 "normal" ;
VAL_ 1713 Led0218_fault 1 "fault" 0 "normal" ;
VAL_ 1713 Led0217_fault 1 "fault" 0 "normal" ;
VAL_ 1713 Led0216_fault 1 "fault" 0 "normal" ;
VAL_ 1713 Led0215_fault 1 "fault" 0 "normal" ;
VAL_ 1713 Led0214_fault 1 "fault" 0 "normal" ;
VAL_ 1713 Led0213_fault 1 "fault" 0 "normal" ;
VAL_ 1713 Led0212_fault 1 "fault" 0 "normal" ;
VAL_ 1713 Led0211_fault 1 "fault" 0 "normal" ;
VAL_ 1713 Led0210_fault 1 "fault" 0 "normal" ;
VAL_ 1713 Led0209_fault 1 "fault" 0 "normal" ;
VAL_ 1713 Led0208_fault 1 "fault" 0 "normal" ;
VAL_ 1713 Led0207_fault 1 "fault" 0 "normal" ;
VAL_ 1713 Led0206_fault 1 "fault" 0 "normal" ;
VAL_ 1713 Led0205_fault 1 "fault" 0 "normal" ;
VAL_ 1713 Led0204_fault 1 "fault" 0 "normal" ;
VAL_ 1713 Led0203_fault 1 "fault" 0 "normal" ;
VAL_ 1713 Led0202_fault 1 "fault" 0 "normal" ;
VAL_ 1713 Led0201_fault 1 "fault" 0 "normal" ;
VAL_ 1713 Led0200_fault 1 "fault" 0 "normal" ;
VAL_ 1713 Led0199_fault 1 "fault" 0 "normal" ;
VAL_ 1713 Led0198_fault 1 "fault" 0 "normal" ;
VAL_ 1713 Led0197_fault 1 "fault" 0 "normal" ;
VAL_ 1713 Led0196_fault 1 "fault" 0 "normal" ;
VAL_ 1713 Led0195_fault 1 "fault" 0 "normal" ;
VAL_ 1713 Led0194_fault 1 "fault" 0 "normal" ;
VAL_ 1713 Led0193_fault 1 "fault" 0 "normal" ;
VAL_ 1713 Led0192_fault 1 "fault" 0 "normal" ;
VAL_ 1713 Led0191_fault 1 "fault" 0 "normal" ;
VAL_ 1713 Led0190_fault 1 "fault" 0 "normal" ;
VAL_ 1713 Led0189_fault 1 "fault" 0 "normal" ;
VAL_ 1713 Led0188_fault 1 "fault" 0 "normal" ;
VAL_ 1713 Led0187_fault 1 "fault" 0 "normal" ;
VAL_ 1713 Led0186_fault 1 "fault" 0 "normal" ;
VAL_ 1713 Led0185_fault 1 "fault" 0 "normal" ;
VAL_ 1713 Led0184_fault 1 "fault" 0 "normal" ;
VAL_ 1713 Led0183_fault 1 "fault" 0 "normal" ;
VAL_ 1713 Led0182_fault 1 "fault" 0 "normal" ;
VAL_ 1713 Led0181_fault 1 "fault" 0 "normal" ;
VAL_ 1713 Led0180_fault 1 "fault" 0 "normal" ;
VAL_ 1713 Led0179_fault 1 "fault" 0 "normal" ;
VAL_ 1713 Led0178_fault 1 "fault" 0 "normal" ;
VAL_ 1713 Led0177_fault 1 "fault" 0 "normal" ;
VAL_ 1713 Led0176_fault 1 "fault" 0 "normal" ;
VAL_ 1713 Led0175_fault 1 "fault" 0 "normal" ;
VAL_ 1713 Led0174_fault 1 "fault" 0 "normal" ;
VAL_ 1713 Led0173_fault 1 "fault" 0 "normal" ;
VAL_ 1713 Led0172_fault 1 "fault" 0 "normal" ;
VAL_ 1713 Led0171_fault 1 "fault" 0 "normal" ;
VAL_ 1713 Led0170_fault 1 "fault" 0 "normal" ;
VAL_ 1713 Led0169_fault 1 "fault" 0 "normal" ;
VAL_ 1713 Led0168_fault 1 "fault" 0 "normal" ;
VAL_ 1713 Led0167_fault 1 "fault" 0 "normal" ;
VAL_ 1713 Led0166_fault 1 "fault" 0 "normal" ;
VAL_ 1713 Led0165_fault 1 "fault" 0 "normal" ;
VAL_ 1713 Led0164_fault 1 "fault" 0 "normal" ;
VAL_ 1713 Led0163_fault 1 "fault" 0 "normal" ;
VAL_ 1713 Led0162_fault 1 "fault" 0 "normal" ;
VAL_ 1713 Led0161_fault 1 "fault" 0 "normal" ;
VAL_ 1713 Led0160_fault 1 "fault" 0 "normal" ;
VAL_ 1713 Led0159_fault 1 "fault" 0 "normal" ;
VAL_ 1713 Led0158_fault 1 "fault" 0 "normal" ;
VAL_ 1713 Led0157_fault 1 "fault" 0 "normal" ;
VAL_ 1713 Led0156_fault 1 "fault" 0 "normal" ;
VAL_ 1713 Led0155_fault 1 "fault" 0 "normal" ;
VAL_ 1713 Led0154_fault 1 "fault" 0 "normal" ;
VAL_ 1713 Led0153_fault 1 "fault" 0 "normal" ;
VAL_ 1713 Led0152_fault 1 "fault" 0 "normal" ;
VAL_ 1713 Led0151_fault 1 "fault" 0 "normal" ;
VAL_ 1713 Led0150_fault 1 "fault" 0 "normal" ;
VAL_ 1713 Led0149_fault 1 "fault" 0 "normal" ;
VAL_ 1713 Led0148_fault 1 "fault" 0 "normal" ;
VAL_ 1713 Led0147_fault 1 "fault" 0 "normal" ;
VAL_ 1713 Led0146_fault 1 "fault" 0 "normal" ;
VAL_ 1713 Led0145_fault 1 "fault" 0 "normal" ;
VAL_ 1713 Led0144_fault 1 "fault" 0 "normal" ;
VAL_ 1713 Led0143_fault 1 "fault" 0 "normal" ;
VAL_ 1713 Led0142_fault 1 "fault" 0 "normal" ;
VAL_ 1713 Led0141_fault 1 "fault" 0 "normal" ;
VAL_ 1713 Led0140_fault 1 "fault" 0 "normal" ;
VAL_ 1713 Led0139_fault 1 "fault" 0 "normal" ;
VAL_ 1713 Led0138_fault 1 "fault" 0 "normal" ;
VAL_ 1713 Led0137_fault 1 "fault" 0 "normal" ;
VAL_ 1713 Led0136_fault 1 "fault" 0 "normal" ;
VAL_ 1713 Led0135_fault 1 "fault" 0 "normal" ;
VAL_ 1713 Led0134_fault 1 "fault" 0 "normal" ;
VAL_ 1713 Led0133_fault 1 "fault" 0 "normal" ;
VAL_ 1713 Led0132_fault 1 "fault" 0 "normal" ;
VAL_ 1713 Led0131_fault 1 "fault" 0 "normal" ;
VAL_ 1713 Led0130_fault 1 "fault" 0 "normal" ;
VAL_ 1713 Led0129_fault 1 "fault" 0 "normal" ;
VAL_ 1713 Led0128_fault 1 "fault" 0 "normal" ;
VAL_ 1713 Led0127_fault 1 "fault" 0 "normal" ;
VAL_ 1713 Led0126_fault 1 "fault" 0 "normal" ;
VAL_ 1713 Led0125_fault 1 "fault" 0 "normal" ;
VAL_ 1713 Led0124_fault 1 "fault" 0 "normal" ;
VAL_ 1713 Led0123_fault 1 "fault" 0 "normal" ;
VAL_ 1713 Led0122_fault 1 "fault" 0 "normal" ;
VAL_ 1713 Led0121_fault 1 "fault" 0 "normal" ;
VAL_ 1713 Led0120_fault 1 "fault" 0 "normal" ;
VAL_ 1713 Led0119_fault 1 "fault" 0 "normal" ;
VAL_ 1713 Led0118_fault 1 "fault" 0 "normal" ;
VAL_ 1713 Led0117_fault 1 "fault" 0 "normal" ;
VAL_ 1713 Led0116_fault 1 "fault" 0 "normal" ;
VAL_ 1713 Led0115_fault 1 "fault" 0 "normal" ;
VAL_ 1713 Led0114_fault 1 "fault" 0 "normal" ;
VAL_ 1713 Led0113_fault 1 "fault" 0 "normal" ;
VAL_ 1713 Led0112_fault 1 "fault" 0 "normal" ;
VAL_ 1713 Led0111_fault 1 "fault" 0 "normal" ;
VAL_ 1713 Led0110_fault 1 "fault" 0 "normal" ;
VAL_ 1713 Led0109_fault 1 "fault" 0 "normal" ;
VAL_ 1713 Led0108_fault 1 "fault" 0 "normal" ;
VAL_ 1713 Led0107_fault 1 "fault" 0 "normal" ;
VAL_ 1713 Led0106_fault 1 "fault" 0 "normal" ;
VAL_ 1713 Led0105_fault 1 "fault" 0 "normal" ;
VAL_ 1713 Led0104_fault 1 "fault" 0 "normal" ;
VAL_ 1713 Led0103_fault 1 "fault" 0 "normal" ;
VAL_ 1713 Led0102_fault 1 "fault" 0 "normal" ;
VAL_ 1713 Led0101_fault 1 "fault" 0 "normal" ;
VAL_ 1713 Led0100_fault 1 "fault" 0 "normal" ;
VAL_ 1713 Led0099_fault 1 "fault" 0 "normal" ;
VAL_ 1713 Led0098_fault 1 "fault" 0 "normal" ;
VAL_ 1713 Led0097_fault 1 "fault" 0 "normal" ;
VAL_ 1713 Led0096_fault 1 "fault" 0 "normal" ;
VAL_ 1713 Led0095_fault 1 "fault" 0 "normal" ;
VAL_ 1713 Led0094_fault 1 "fault" 0 "normal" ;
VAL_ 1713 Led0093_fault 1 "fault" 0 "normal" ;
VAL_ 1713 Led0092_fault 1 "fault" 0 "normal" ;
VAL_ 1713 Led0091_fault 1 "fault" 0 "normal" ;
VAL_ 1713 Led0090_fault 1 "fault" 0 "normal" ;
VAL_ 1713 Led0089_fault 1 "fault" 0 "normal" ;
VAL_ 1713 Led0088_fault 1 "fault" 0 "normal" ;
VAL_ 1713 Led0087_fault 1 "fault" 0 "normal" ;
VAL_ 1713 Led0086_fault 1 "fault" 0 "normal" ;
VAL_ 1713 Led0085_fault 1 "fault" 0 "normal" ;
VAL_ 1713 Led0084_fault 1 "fault" 0 "normal" ;
VAL_ 1713 Led0083_fault 1 "fault" 0 "normal" ;
VAL_ 1713 Led0082_fault 1 "fault" 0 "normal" ;
VAL_ 1713 Led0081_fault 1 "fault" 0 "normal" ;
VAL_ 1713 Led0080_fault 1 "fault" 0 "normal" ;
VAL_ 1713 Led0079_fault 1 "fault" 0 "normal" ;
VAL_ 1713 Led0078_fault 1 "fault" 0 "normal" ;
VAL_ 1713 Led0077_fault 1 "fault" 0 "normal" ;
VAL_ 1713 Led0076_fault 1 "fault" 0 "normal" ;
VAL_ 1713 Led0075_fault 1 "fault" 0 "normal" ;
VAL_ 1713 Led0074_fault 1 "fault" 0 "normal" ;
VAL_ 1713 Led0073_fault 1 "fault" 0 "normal" ;
VAL_ 1713 Led0072_fault 1 "fault" 0 "normal" ;
VAL_ 1713 Led0071_fault 1 "fault" 0 "normal" ;
VAL_ 1713 Led0070_fault 1 "fault" 0 "normal" ;
VAL_ 1713 Led0069_fault 1 "fault" 0 "normal" ;
VAL_ 1713 Led0068_fault 1 "fault" 0 "normal" ;
VAL_ 1713 Led0067_fault 1 "fault" 0 "normal" ;
VAL_ 1713 Led0066_fault 1 "fault" 0 "normal" ;
VAL_ 1713 Led0065_fault 1 "fault" 0 "normal" ;
VAL_ 1713 Led0064_fault 1 "fault" 0 "normal" ;
VAL_ 1713 Led0063_fault 1 "fault" 0 "normal" ;
VAL_ 1713 Led0062_fault 1 "fault" 0 "normal" ;
VAL_ 1713 Led0061_fault 1 "fault" 0 "normal" ;
VAL_ 1713 Led0060_fault 1 "fault" 0 "normal" ;
VAL_ 1713 Led0059_fault 1 "fault" 0 "normal" ;
VAL_ 1713 Led0058_fault 1 "fault" 0 "normal" ;
VAL_ 1713 Led0057_fault 1 "fault" 0 "normal" ;
VAL_ 1713 Led0056_fault 1 "fault" 0 "normal" ;
VAL_ 1713 Led0055_fault 1 "fault" 0 "normal" ;
VAL_ 1713 Led0054_fault 1 "fault" 0 "normal" ;
VAL_ 1713 Led0053_fault 1 "fault" 0 "normal" ;
VAL_ 1713 Led0052_fault 1 "fault" 0 "normal" ;
VAL_ 1713 Led0051_fault 1 "fault" 0 "normal" ;
VAL_ 1713 Led0050_fault 1 "fault" 0 "normal" ;
VAL_ 1713 Led0049_fault 1 "fault" 0 "normal" ;
VAL_ 1713 Led0048_fault 1 "fault" 0 "normal" ;
VAL_ 1713 Led0047_fault 1 "fault" 0 "normal" ;
VAL_ 1713 Led0046_fault 1 "fault" 0 "normal" ;
VAL_ 1713 Led0045_fault 1 "fault" 0 "normal" ;
VAL_ 1713 Led0044_fault 1 "fault" 0 "normal" ;
VAL_ 1713 Led0043_fault 1 "fault" 0 "normal" ;
VAL_ 1713 Led0042_fault 1 "fault" 0 "normal" ;
VAL_ 1713 Led0041_fault 1 "fault" 0 "normal" ;
VAL_ 1713 Led0040_fault 1 "fault" 0 "normal" ;
VAL_ 1713 Led0039_fault 1 "fault" 0 "normal" ;
VAL_ 1713 Led0038_fault 1 "fault" 0 "normal" ;
VAL_ 1713 Led0037_fault 1 "fault" 0 "normal" ;
VAL_ 1713 Led0036_fault 1 "fault" 0 "normal" ;
VAL_ 1713 Led0035_fault 1 "fault" 0 "normal" ;
VAL_ 1713 Led0034_fault 1 "fault" 0 "normal" ;
VAL_ 1713 Led0033_fault 1 "fault" 0 "normal" ;
VAL_ 1713 Led0032_fault 1 "fault" 0 "normal" ;
VAL_ 1713 Led0031_fault 1 "fault" 0 "normal" ;
VAL_ 1713 Led0030_fault 1 "fault" 0 "normal" ;
VAL_ 1713 Led0029_fault 1 "fault" 0 "normal" ;
VAL_ 1713 Led0028_fault 1 "fault" 0 "normal" ;
VAL_ 1713 Led0027_fault 1 "fault" 0 "normal" ;
VAL_ 1713 Led0026_fault 1 "fault" 0 "normal" ;
VAL_ 1713 Led0025_fault 1 "fault" 0 "normal" ;
VAL_ 1713 Led0024_fault 1 "fault" 0 "normal" ;
VAL_ 1713 Led0023_fault 1 "fault" 0 "normal" ;
VAL_ 1713 Led0022_fault 1 "fault" 0 "normal" ;
VAL_ 1713 Led0021_fault 1 "fault" 0 "normal" ;
VAL_ 1713 Led0020_fault 1 "fault" 0 "normal" ;
VAL_ 1713 Led0019_fault 1 "fault" 0 "normal" ;
VAL_ 1713 Led0018_fault 1 "fault" 0 "normal" ;
VAL_ 1713 Led0017_fault 1 "fault" 0 "normal" ;
VAL_ 1713 Led0016_fault 1 "fault" 0 "normal" ;
VAL_ 1713 Led0015_fault 1 "fault" 0 "normal" ;
VAL_ 1713 Led0014_fault 1 "fault" 0 "normal" ;
VAL_ 1713 Led0013_fault 1 "fault" 0 "normal" ;
VAL_ 1713 Led0012_fault 1 "fault" 0 "normal" ;
VAL_ 1713 Led0011_fault 1 "fault" 0 "normal" ;
VAL_ 1713 Led0010_fault 1 "fault" 0 "normal" ;
VAL_ 1713 Led0007_fault 1 "fault" 0 "normal" ;
VAL_ 1713 Led0009_fault 1 "fault" 0 "normal" ;
VAL_ 1713 Led0008_fault 1 "fault" 0 "normal" ;
VAL_ 1713 Led0006_fault 1 "fault" 0 "normal" ;
VAL_ 1713 Led0005_fault 1 "fault" 0 "normal" ;
VAL_ 1713 Led0004_fault 1 "fault" 0 "normal" ;
VAL_ 1713 Led0003_fault 1 "fault" 0 "normal" ;
VAL_ 1713 Led0002_fault 1 "fault" 0 "normal" ;
VAL_ 1713 Led0001_fault 1 "fault" 0 "normal" ;
VAL_ 1712 C_Led_Fault 1 "fault" 0 "normal" ;
VAL_ 1712 Led_Driver_Internal_Fault 1 "fault" 0 "normal" ;
VAL_ 1712 Led_Driver_High_Temp_Fault 1 "fault" 0 "normal" ;
VAL_ 1712 Led_Driver_Low_Voltage_Fault 1 "fault" 0 "normal" ;
VAL_ 1712 Led_Driver_High_Voltage_Fault 1 "fault" 0 "normal" ;
VAL_ 1712 Break_Sts 1 "Available" 0 "Inavailable" ;
VAL_ 1712 Turn_Sts 1 "Available" 0 "Inavailable" ;
VAL_ 1712 Led_Driver_WorkSts 3 "Swtched_Off_due_to_Error" 2 "Switched_On_but_Derating" 1 "Switched_On_Normal" 0 "Switched_Off" ;
VAL_ 1701 Led0415_fault 1 "fault" 0 "normal" ;
VAL_ 1701 Led0414_fault 1 "fault" 0 "normal" ;
VAL_ 1701 Led0413_fault 1 "fault" 0 "normal" ;
VAL_ 1701 Led0412_fault 1 "fault" 0 "normal" ;
VAL_ 1701 Led0411_fault 1 "fault" 0 "normal" ;
VAL_ 1701 Led0410_fault 1 "fault" 0 "normal" ;
VAL_ 1701 Led0409_fault 1 "fault" 0 "normal" ;
VAL_ 1701 Led0408_fault 1 "fault" 0 "normal" ;
VAL_ 1701 Led0407_fault 1 "fault" 0 "normal" ;
VAL_ 1701 Led0406_fault 1 "fault" 0 "normal" ;
VAL_ 1701 Led0405_fault 1 "fault" 0 "normal" ;
VAL_ 1701 Led0404_fault 1 "fault" 0 "normal" ;
VAL_ 1701 Led0403_fault 1 "fault" 0 "normal" ;
VAL_ 1701 Led0402_fault 1 "fault" 0 "normal" ;
VAL_ 1701 Led0401_fault 1 "fault" 0 "normal" ;
VAL_ 1701 Led0400_fault 1 "fault" 0 "normal" ;
VAL_ 1701 Led0399_fault 1 "fault" 0 "normal" ;
VAL_ 1701 Led0398_fault 1 "fault" 0 "normal" ;
VAL_ 1701 Led0397_fault 1 "fault" 0 "normal" ;
VAL_ 1701 Led0396_fault 1 "fault" 0 "normal" ;
VAL_ 1701 Led0395_fault 1 "fault" 0 "normal" ;
VAL_ 1701 Led0394_fault 1 "fault" 0 "normal" ;
VAL_ 1701 Led0393_fault 1 "fault" 0 "normal" ;
VAL_ 1701 Led0392_fault 1 "fault" 0 "normal" ;
VAL_ 1701 Led0391_fault 1 "fault" 0 "normal" ;
VAL_ 1701 Led0390_fault 1 "fault" 0 "normal" ;
VAL_ 1701 Led0389_fault 1 "fault" 0 "normal" ;
VAL_ 1701 Led0388_fault 1 "fault" 0 "normal" ;
VAL_ 1701 Led0387_fault 1 "fault" 0 "normal" ;
VAL_ 1701 Led0386_fault 1 "fault" 0 "normal" ;
VAL_ 1701 Led0385_fault 1 "fault" 0 "normal" ;
VAL_ 1701 Led0384_fault 1 "fault" 0 "normal" ;
VAL_ 1701 Led0383_fault 1 "fault" 0 "normal" ;
VAL_ 1701 Led0382_fault 1 "fault" 0 "normal" ;
VAL_ 1701 Led0381_fault 1 "fault" 0 "normal" ;
VAL_ 1701 Led0380_fault 1 "fault" 0 "normal" ;
VAL_ 1701 Led0379_fault 1 "fault" 0 "normal" ;
VAL_ 1701 Led0378_fault 1 "fault" 0 "normal" ;
VAL_ 1701 Led0377_fault 1 "fault" 0 "normal" ;
VAL_ 1701 Led0376_fault 1 "fault" 0 "normal" ;
VAL_ 1701 Led0375_fault 1 "fault" 0 "normal" ;
VAL_ 1701 Led0374_fault 1 "fault" 0 "normal" ;
VAL_ 1701 Led0373_fault 1 "fault" 0 "normal" ;
VAL_ 1701 Led0372_fault 1 "fault" 0 "normal" ;
VAL_ 1701 Led0371_fault 1 "fault" 0 "normal" ;
VAL_ 1701 Led0370_fault 1 "fault" 0 "normal" ;
VAL_ 1701 Led0369_fault 1 "fault" 0 "normal" ;
VAL_ 1701 Led0368_fault 1 "fault" 0 "normal" ;
VAL_ 1701 Led0367_fault 1 "fault" 0 "normal" ;
VAL_ 1701 Led0366_fault 1 "fault" 0 "normal" ;
VAL_ 1701 Led0365_fault 1 "fault" 0 "normal" ;
VAL_ 1701 Led0364_fault 1 "fault" 0 "normal" ;
VAL_ 1701 Led0363_fault 1 "fault" 0 "normal" ;
VAL_ 1701 Led0362_fault 1 "fault" 0 "normal" ;
VAL_ 1701 Led0361_fault 1 "fault" 0 "normal" ;
VAL_ 1701 Led0360_fault 1 "fault" 0 "normal" ;
VAL_ 1701 Led0359_fault 1 "fault" 0 "normal" ;
VAL_ 1701 Led0358_fault 1 "fault" 0 "normal" ;
VAL_ 1701 Led0357_fault 1 "fault" 0 "normal" ;
VAL_ 1701 Led0356_fault 1 "fault" 0 "normal" ;
VAL_ 1701 Led0355_fault 1 "fault" 0 "normal" ;
VAL_ 1701 Led0354_fault 1 "fault" 0 "normal" ;
VAL_ 1701 Led0353_fault 1 "fault" 0 "normal" ;
VAL_ 1701 Led0352_fault 1 "fault" 0 "normal" ;
VAL_ 1701 Led0351_fault 1 "fault" 0 "normal" ;
VAL_ 1701 Led0350_fault 1 "fault" 0 "normal" ;
VAL_ 1701 Led0349_fault 1 "fault" 0 "normal" ;
VAL_ 1701 Led0348_fault 1 "fault" 0 "normal" ;
VAL_ 1701 Led0347_fault 1 "fault" 0 "normal" ;
VAL_ 1701 Led0346_fault 1 "fault" 0 "normal" ;
VAL_ 1701 Led0345_fault 1 "fault" 0 "normal" ;
VAL_ 1701 Led0344_fault 1 "fault" 0 "normal" ;
VAL_ 1701 Led0343_fault 1 "fault" 0 "normal" ;
VAL_ 1701 Led0342_fault 1 "fault" 0 "normal" ;
VAL_ 1701 Led0341_fault 1 "fault" 0 "normal" ;
VAL_ 1701 Led0340_fault 1 "fault" 0 "normal" ;
VAL_ 1701 Led0339_fault 1 "fault" 0 "normal" ;
VAL_ 1701 Led0338_fault 1 "fault" 0 "normal" ;
VAL_ 1701 Led0337_fault 1 "fault" 0 "normal" ;
VAL_ 1701 Led0336_fault 1 "fault" 0 "normal" ;
VAL_ 1701 Led0335_fault 1 "fault" 0 "normal" ;
VAL_ 1701 Led0334_fault 1 "fault" 0 "normal" ;
VAL_ 1701 Led0333_fault 1 "fault" 0 "normal" ;
VAL_ 1701 Led0332_fault 1 "fault" 0 "normal" ;
VAL_ 1701 Led0331_fault 1 "fault" 0 "normal" ;
VAL_ 1701 Led0330_fault 1 "fault" 0 "normal" ;
VAL_ 1701 Led0329_fault 1 "fault" 0 "normal" ;
VAL_ 1701 Led0328_fault 1 "fault" 0 "normal" ;
VAL_ 1701 Led0327_fault 1 "fault" 0 "normal" ;
VAL_ 1701 Led0326_fault 1 "fault" 0 "normal" ;
VAL_ 1701 Led0325_fault 1 "fault" 0 "normal" ;
VAL_ 1701 Led0324_fault 1 "fault" 0 "normal" ;
VAL_ 1701 Led0323_fault 1 "fault" 0 "normal" ;
VAL_ 1701 Led0322_fault 1 "fault" 0 "normal" ;
VAL_ 1701 Led0321_fault 1 "fault" 0 "normal" ;
VAL_ 1701 Led0320_fault 1 "fault" 0 "normal" ;
VAL_ 1701 Led0319_fault 1 "fault" 0 "normal" ;
VAL_ 1701 Led0318_fault 1 "fault" 0 "normal" ;
VAL_ 1701 Led0317_fault 1 "fault" 0 "normal" ;
VAL_ 1701 Led0316_fault 1 "fault" 0 "normal" ;
VAL_ 1701 Led0315_fault 1 "fault" 0 "normal" ;
VAL_ 1701 Led0314_fault 1 "fault" 0 "normal" ;
VAL_ 1701 Led0313_fault 1 "fault" 0 "normal" ;
VAL_ 1701 Led0312_fault 1 "fault" 0 "normal" ;
VAL_ 1701 Led0311_fault 1 "fault" 0 "normal" ;
VAL_ 1701 Led0310_fault 1 "fault" 0 "normal" ;
VAL_ 1701 Led0309_fault 1 "fault" 0 "normal" ;
VAL_ 1701 Led0308_fault 1 "fault" 0 "normal" ;
VAL_ 1701 Led0307_fault 1 "fault" 0 "normal" ;
VAL_ 1701 Led0306_fault 1 "fault" 0 "normal" ;
VAL_ 1701 Led0305_fault 1 "fault" 0 "normal" ;
VAL_ 1701 Led0304_fault 1 "fault" 0 "normal" ;
VAL_ 1701 Led0303_fault 1 "fault" 0 "normal" ;
VAL_ 1701 Led0302_fault 1 "fault" 0 "normal" ;
VAL_ 1701 Led0301_fault 1 "fault" 0 "normal" ;
VAL_ 1701 Led0300_fault 1 "fault" 0 "normal" ;
VAL_ 1701 Led0299_fault 1 "fault" 0 "normal" ;
VAL_ 1701 Led0298_fault 1 "fault" 0 "normal" ;
VAL_ 1701 Led0297_fault 1 "fault" 0 "normal" ;
VAL_ 1701 Led0296_fault 1 "fault" 0 "normal" ;
VAL_ 1701 Led0295_fault 1 "fault" 0 "normal" ;
VAL_ 1701 Led0294_fault 1 "fault" 0 "normal" ;
VAL_ 1701 Led0293_fault 1 "fault" 0 "normal" ;
VAL_ 1701 Led0292_fault 1 "fault" 0 "normal" ;
VAL_ 1701 Led0291_fault 1 "fault" 0 "normal" ;
VAL_ 1701 Led0290_fault 1 "fault" 0 "normal" ;
VAL_ 1701 Led0289_fault 1 "fault" 0 "normal" ;
VAL_ 1701 Led0288_fault 1 "fault" 0 "normal" ;
VAL_ 1701 Led0287_fault 1 "fault" 0 "normal" ;
VAL_ 1701 Led0286_fault 1 "fault" 0 "normal" ;
VAL_ 1701 Led0285_fault 1 "fault" 0 "normal" ;
VAL_ 1701 Led0284_fault 1 "fault" 0 "normal" ;
VAL_ 1701 Led0283_fault 1 "fault" 0 "normal" ;
VAL_ 1701 Led0282_fault 1 "fault" 0 "normal" ;
VAL_ 1701 Led0281_fault 1 "fault" 0 "normal" ;
VAL_ 1701 Led0280_fault 1 "fault" 0 "normal" ;
VAL_ 1701 Led0279_fault 1 "fault" 0 "normal" ;
VAL_ 1701 Led0278_fault 1 "fault" 0 "normal" ;
VAL_ 1701 Led0277_fault 1 "fault" 0 "normal" ;
VAL_ 1701 Led0276_fault 1 "fault" 0 "normal" ;
VAL_ 1701 Led0275_fault 1 "fault" 0 "normal" ;
VAL_ 1701 Led0274_fault 1 "fault" 0 "normal" ;
VAL_ 1701 Led0273_fault 1 "fault" 0 "normal" ;
VAL_ 1701 Led0272_fault 1 "fault" 0 "normal" ;
VAL_ 1701 Led0271_fault 1 "fault" 0 "normal" ;
VAL_ 1701 Led0270_fault 1 "fault" 0 "normal" ;
VAL_ 1701 Led0269_fault 1 "fault" 0 "normal" ;
VAL_ 1701 Led0268_fault 1 "fault" 0 "normal" ;
VAL_ 1701 Led0267_fault 1 "fault" 0 "normal" ;
VAL_ 1701 Led0266_fault 1 "fault" 0 "normal" ;
VAL_ 1701 Led0265_fault 1 "fault" 0 "normal" ;
VAL_ 1701 Led0264_fault 1 "fault" 0 "normal" ;
VAL_ 1701 Led0263_fault 1 "fault" 0 "normal" ;
VAL_ 1701 Led0262_fault 1 "fault" 0 "normal" ;
VAL_ 1701 Led0261_fault 1 "fault" 0 "normal" ;
VAL_ 1701 Led0260_fault 1 "fault" 0 "normal" ;
VAL_ 1701 Led0259_fault 1 "fault" 0 "normal" ;
VAL_ 1701 Led0258_fault 1 "fault" 0 "normal" ;
VAL_ 1701 Led0257_fault 1 "fault" 0 "normal" ;
VAL_ 1701 Led0256_fault 1 "fault" 0 "normal" ;
VAL_ 1701 Led0255_fault 1 "fault" 0 "normal" ;
VAL_ 1701 Led0254_fault 1 "fault" 0 "normal" ;
VAL_ 1701 Led0253_fault 1 "fault" 0 "normal" ;
VAL_ 1701 Led0252_fault 1 "fault" 0 "normal" ;
VAL_ 1701 Led0251_fault 1 "fault" 0 "normal" ;
VAL_ 1701 Led0250_fault 1 "fault" 0 "normal" ;
VAL_ 1701 Led0249_fault 1 "fault" 0 "normal" ;
VAL_ 1701 Led0248_fault 1 "fault" 0 "normal" ;
VAL_ 1701 Led0247_fault 1 "fault" 0 "normal" ;
VAL_ 1701 Led0246_fault 1 "fault" 0 "normal" ;
VAL_ 1701 Led0245_fault 1 "fault" 0 "normal" ;
VAL_ 1701 Led0244_fault 1 "fault" 0 "normal" ;
VAL_ 1701 Led0243_fault 1 "fault" 0 "normal" ;
VAL_ 1701 Led0242_fault 1 "fault" 0 "normal" ;
VAL_ 1701 Led0241_fault 1 "fault" 0 "normal" ;
VAL_ 1701 Led0240_fault 1 "fault" 0 "normal" ;
VAL_ 1701 Led0239_fault 1 "fault" 0 "normal" ;
VAL_ 1701 Led0238_fault 1 "fault" 0 "normal" ;
VAL_ 1701 Led0237_fault 1 "fault" 0 "normal" ;
VAL_ 1701 Led0236_fault 1 "fault" 0 "normal" ;
VAL_ 1701 Led0235_fault 1 "fault" 0 "normal" ;
VAL_ 1701 Led0234_fault 1 "fault" 0 "normal" ;
VAL_ 1701 Led0233_fault 1 "fault" 0 "normal" ;
VAL_ 1701 Led0232_fault 1 "fault" 0 "normal" ;
VAL_ 1701 Led0231_fault 1 "fault" 0 "normal" ;
VAL_ 1701 Led0230_fault 1 "fault" 0 "normal" ;
VAL_ 1701 Led0229_fault 1 "fault" 0 "normal" ;
VAL_ 1701 Led0228_fault 1 "fault" 0 "normal" ;
VAL_ 1701 Led0227_fault 1 "fault" 0 "normal" ;
VAL_ 1701 Led0226_fault 1 "fault" 0 "normal" ;
VAL_ 1701 Led0225_fault 1 "fault" 0 "normal" ;
VAL_ 1701 Led0224_fault 1 "fault" 0 "normal" ;
VAL_ 1701 Led0223_fault 1 "fault" 0 "normal" ;
VAL_ 1701 Led0222_fault 1 "fault" 0 "normal" ;
VAL_ 1701 Led0221_fault 1 "fault" 0 "normal" ;
VAL_ 1701 Led0220_fault 1 "fault" 0 "normal" ;
VAL_ 1701 Led0219_fault 1 "fault" 0 "normal" ;
VAL_ 1701 Led0218_fault 1 "fault" 0 "normal" ;
VAL_ 1701 Led0217_fault 1 "fault" 0 "normal" ;
VAL_ 1701 Led0216_fault 1 "fault" 0 "normal" ;
VAL_ 1701 Led0215_fault 1 "fault" 0 "normal" ;
VAL_ 1701 Led0214_fault 1 "fault" 0 "normal" ;
VAL_ 1701 Led0213_fault 1 "fault" 0 "normal" ;
VAL_ 1701 Led0212_fault 1 "fault" 0 "normal" ;
VAL_ 1701 Led0211_fault 1 "fault" 0 "normal" ;
VAL_ 1701 Led0210_fault 1 "fault" 0 "normal" ;
VAL_ 1701 Led0209_fault 1 "fault" 0 "normal" ;
VAL_ 1701 Led0208_fault 1 "fault" 0 "normal" ;
VAL_ 1701 Led0207_fault 1 "fault" 0 "normal" ;
VAL_ 1701 Led0206_fault 1 "fault" 0 "normal" ;
VAL_ 1701 Led0205_fault 1 "fault" 0 "normal" ;
VAL_ 1701 Led0204_fault 1 "fault" 0 "normal" ;
VAL_ 1701 Led0203_fault 1 "fault" 0 "normal" ;
VAL_ 1701 Led0202_fault 1 "fault" 0 "normal" ;
VAL_ 1701 Led0201_fault 1 "fault" 0 "normal" ;
VAL_ 1701 Led0200_fault 1 "fault" 0 "normal" ;
VAL_ 1701 Led0199_fault 1 "fault" 0 "normal" ;
VAL_ 1701 Led0198_fault 1 "fault" 0 "normal" ;
VAL_ 1701 Led0197_fault 1 "fault" 0 "normal" ;
VAL_ 1701 Led0196_fault 1 "fault" 0 "normal" ;
VAL_ 1701 Led0195_fault 1 "fault" 0 "normal" ;
VAL_ 1701 Led0194_fault 1 "fault" 0 "normal" ;
VAL_ 1701 Led0193_fault 1 "fault" 0 "normal" ;
VAL_ 1701 Led0192_fault 1 "fault" 0 "normal" ;
VAL_ 1701 Led0191_fault 1 "fault" 0 "normal" ;
VAL_ 1701 Led0190_fault 1 "fault" 0 "normal" ;
VAL_ 1701 Led0189_fault 1 "fault" 0 "normal" ;
VAL_ 1701 Led0188_fault 1 "fault" 0 "normal" ;
VAL_ 1701 Led0187_fault 1 "fault" 0 "normal" ;
VAL_ 1701 Led0186_fault 1 "fault" 0 "normal" ;
VAL_ 1701 Led0185_fault 1 "fault" 0 "normal" ;
VAL_ 1701 Led0184_fault 1 "fault" 0 "normal" ;
VAL_ 1701 Led0183_fault 1 "fault" 0 "normal" ;
VAL_ 1701 Led0182_fault 1 "fault" 0 "normal" ;
VAL_ 1701 Led0181_fault 1 "fault" 0 "normal" ;
VAL_ 1701 Led0180_fault 1 "fault" 0 "normal" ;
VAL_ 1701 Led0179_fault 1 "fault" 0 "normal" ;
VAL_ 1701 Led0178_fault 1 "fault" 0 "normal" ;
VAL_ 1701 Led0177_fault 1 "fault" 0 "normal" ;
VAL_ 1701 Led0176_fault 1 "fault" 0 "normal" ;
VAL_ 1701 Led0175_fault 1 "fault" 0 "normal" ;
VAL_ 1701 Led0174_fault 1 "fault" 0 "normal" ;
VAL_ 1701 Led0173_fault 1 "fault" 0 "normal" ;
VAL_ 1701 Led0172_fault 1 "fault" 0 "normal" ;
VAL_ 1701 Led0171_fault 1 "fault" 0 "normal" ;
VAL_ 1701 Led0170_fault 1 "fault" 0 "normal" ;
VAL_ 1701 Led0169_fault 1 "fault" 0 "normal" ;
VAL_ 1701 Led0168_fault 1 "fault" 0 "normal" ;
VAL_ 1701 Led0167_fault 1 "fault" 0 "normal" ;
VAL_ 1701 Led0166_fault 1 "fault" 0 "normal" ;
VAL_ 1701 Led0165_fault 1 "fault" 0 "normal" ;
VAL_ 1701 Led0164_fault 1 "fault" 0 "normal" ;
VAL_ 1701 Led0163_fault 1 "fault" 0 "normal" ;
VAL_ 1701 Led0162_fault 1 "fault" 0 "normal" ;
VAL_ 1701 Led0161_fault 1 "fault" 0 "normal" ;
VAL_ 1701 Led0160_fault 1 "fault" 0 "normal" ;
VAL_ 1701 Led0159_fault 1 "fault" 0 "normal" ;
VAL_ 1701 Led0158_fault 1 "fault" 0 "normal" ;
VAL_ 1701 Led0157_fault 1 "fault" 0 "normal" ;
VAL_ 1701 Led0156_fault 1 "fault" 0 "normal" ;
VAL_ 1701 Led0155_fault 1 "fault" 0 "normal" ;
VAL_ 1701 Led0154_fault 1 "fault" 0 "normal" ;
VAL_ 1701 Led0153_fault 1 "fault" 0 "normal" ;
VAL_ 1701 Led0152_fault 1 "fault" 0 "normal" ;
VAL_ 1701 Led0151_fault 1 "fault" 0 "normal" ;
VAL_ 1701 Led0150_fault 1 "fault" 0 "normal" ;
VAL_ 1701 Led0149_fault 1 "fault" 0 "normal" ;
VAL_ 1701 Led0148_fault 1 "fault" 0 "normal" ;
VAL_ 1701 Led0147_fault 1 "fault" 0 "normal" ;
VAL_ 1701 Led0146_fault 1 "fault" 0 "normal" ;
VAL_ 1701 Led0145_fault 1 "fault" 0 "normal" ;
VAL_ 1701 Led0144_fault 1 "fault" 0 "normal" ;
VAL_ 1701 Led0143_fault 1 "fault" 0 "normal" ;
VAL_ 1701 Led0142_fault 1 "fault" 0 "normal" ;
VAL_ 1701 Led0141_fault 1 "fault" 0 "normal" ;
VAL_ 1701 Led0140_fault 1 "fault" 0 "normal" ;
VAL_ 1701 Led0139_fault 1 "fault" 0 "normal" ;
VAL_ 1701 Led0138_fault 1 "fault" 0 "normal" ;
VAL_ 1701 Led0137_fault 1 "fault" 0 "normal" ;
VAL_ 1701 Led0136_fault 1 "fault" 0 "normal" ;
VAL_ 1701 Led0135_fault 1 "fault" 0 "normal" ;
VAL_ 1701 Led0134_fault 1 "fault" 0 "normal" ;
VAL_ 1701 Led0133_fault 1 "fault" 0 "normal" ;
VAL_ 1701 Led0132_fault 1 "fault" 0 "normal" ;
VAL_ 1701 Led0131_fault 1 "fault" 0 "normal" ;
VAL_ 1701 Led0130_fault 1 "fault" 0 "normal" ;
VAL_ 1701 Led0129_fault 1 "fault" 0 "normal" ;
VAL_ 1701 Led0128_fault 1 "fault" 0 "normal" ;
VAL_ 1701 Led0127_fault 1 "fault" 0 "normal" ;
VAL_ 1701 Led0126_fault 1 "fault" 0 "normal" ;
VAL_ 1701 Led0125_fault 1 "fault" 0 "normal" ;
VAL_ 1701 Led0124_fault 1 "fault" 0 "normal" ;
VAL_ 1701 Led0123_fault 1 "fault" 0 "normal" ;
VAL_ 1701 Led0122_fault 1 "fault" 0 "normal" ;
VAL_ 1701 Led0121_fault 1 "fault" 0 "normal" ;
VAL_ 1701 Led0120_fault 1 "fault" 0 "normal" ;
VAL_ 1701 Led0119_fault 1 "fault" 0 "normal" ;
VAL_ 1701 Led0118_fault 1 "fault" 0 "normal" ;
VAL_ 1701 Led0117_fault 1 "fault" 0 "normal" ;
VAL_ 1701 Led0116_fault 1 "fault" 0 "normal" ;
VAL_ 1701 Led0115_fault 1 "fault" 0 "normal" ;
VAL_ 1701 Led0114_fault 1 "fault" 0 "normal" ;
VAL_ 1701 Led0113_fault 1 "fault" 0 "normal" ;
VAL_ 1701 Led0112_fault 1 "fault" 0 "normal" ;
VAL_ 1701 Led0111_fault 1 "fault" 0 "normal" ;
VAL_ 1701 Led0110_fault 1 "fault" 0 "normal" ;
VAL_ 1701 Led0109_fault 1 "fault" 0 "normal" ;
VAL_ 1701 Led0108_fault 1 "fault" 0 "normal" ;
VAL_ 1701 Led0107_fault 1 "fault" 0 "normal" ;
VAL_ 1701 Led0106_fault 1 "fault" 0 "normal" ;
VAL_ 1701 Led0105_fault 1 "fault" 0 "normal" ;
VAL_ 1701 Led0104_fault 1 "fault" 0 "normal" ;
VAL_ 1701 Led0103_fault 1 "fault" 0 "normal" ;
VAL_ 1701 Led0102_fault 1 "fault" 0 "normal" ;
VAL_ 1701 Led0101_fault 1 "fault" 0 "normal" ;
VAL_ 1701 Led0100_fault 1 "fault" 0 "normal" ;
VAL_ 1701 Led0099_fault 1 "fault" 0 "normal" ;
VAL_ 1701 Led0098_fault 1 "fault" 0 "normal" ;
VAL_ 1701 Led0097_fault 1 "fault" 0 "normal" ;
VAL_ 1701 Led0096_fault 1 "fault" 0 "normal" ;
VAL_ 1701 Led0095_fault 1 "fault" 0 "normal" ;
VAL_ 1701 Led0094_fault 1 "fault" 0 "normal" ;
VAL_ 1701 Led0093_fault 1 "fault" 0 "normal" ;
VAL_ 1701 Led0092_fault 1 "fault" 0 "normal" ;
VAL_ 1701 Led0091_fault 1 "fault" 0 "normal" ;
VAL_ 1701 Led0090_fault 1 "fault" 0 "normal" ;
VAL_ 1701 Led0089_fault 1 "fault" 0 "normal" ;
VAL_ 1701 Led0088_fault 1 "fault" 0 "normal" ;
VAL_ 1701 Led0087_fault 1 "fault" 0 "normal" ;
VAL_ 1701 Led0086_fault 1 "fault" 0 "normal" ;
VAL_ 1701 Led0085_fault 1 "fault" 0 "normal" ;
VAL_ 1701 Led0084_fault 1 "fault" 0 "normal" ;
VAL_ 1701 Led0083_fault 1 "fault" 0 "normal" ;
VAL_ 1701 Led0082_fault 1 "fault" 0 "normal" ;
VAL_ 1701 Led0081_fault 1 "fault" 0 "normal" ;
VAL_ 1701 Led0080_fault 1 "fault" 0 "normal" ;
VAL_ 1701 Led0079_fault 1 "fault" 0 "normal" ;
VAL_ 1701 Led0078_fault 1 "fault" 0 "normal" ;
VAL_ 1701 Led0077_fault 1 "fault" 0 "normal" ;
VAL_ 1701 Led0076_fault 1 "fault" 0 "normal" ;
VAL_ 1701 Led0075_fault 1 "fault" 0 "normal" ;
VAL_ 1701 Led0074_fault 1 "fault" 0 "normal" ;
VAL_ 1701 Led0073_fault 1 "fault" 0 "normal" ;
VAL_ 1701 Led0072_fault 1 "fault" 0 "normal" ;
VAL_ 1701 Led0071_fault 1 "fault" 0 "normal" ;
VAL_ 1701 Led0070_fault 1 "fault" 0 "normal" ;
VAL_ 1701 Led0069_fault 1 "fault" 0 "normal" ;
VAL_ 1701 Led0068_fault 1 "fault" 0 "normal" ;
VAL_ 1701 Led0067_fault 1 "fault" 0 "normal" ;
VAL_ 1701 Led0066_fault 1 "fault" 0 "normal" ;
VAL_ 1701 Led0065_fault 1 "fault" 0 "normal" ;
VAL_ 1701 Led0064_fault 1 "fault" 0 "normal" ;
VAL_ 1701 Led0063_fault 1 "fault" 0 "normal" ;
VAL_ 1701 Led0062_fault 1 "fault" 0 "normal" ;
VAL_ 1701 Led0061_fault 1 "fault" 0 "normal" ;
VAL_ 1701 Led0060_fault 1 "fault" 0 "normal" ;
VAL_ 1701 Led0059_fault 1 "fault" 0 "normal" ;
VAL_ 1701 Led0058_fault 1 "fault" 0 "normal" ;
VAL_ 1701 Led0057_fault 1 "fault" 0 "normal" ;
VAL_ 1701 Led0056_fault 1 "fault" 0 "normal" ;
VAL_ 1701 Led0055_fault 1 "fault" 0 "normal" ;
VAL_ 1701 Led0054_fault 1 "fault" 0 "normal" ;
VAL_ 1701 Led0053_fault 1 "fault" 0 "normal" ;
VAL_ 1701 Led0052_fault 1 "fault" 0 "normal" ;
VAL_ 1701 Led0051_fault 1 "fault" 0 "normal" ;
VAL_ 1701 Led0050_fault 1 "fault" 0 "normal" ;
VAL_ 1701 Led0049_fault 1 "fault" 0 "normal" ;
VAL_ 1701 Led0048_fault 1 "fault" 0 "normal" ;
VAL_ 1701 Led0047_fault 1 "fault" 0 "normal" ;
VAL_ 1701 Led0046_fault 1 "fault" 0 "normal" ;
VAL_ 1701 Led0045_fault 1 "fault" 0 "normal" ;
VAL_ 1701 Led0044_fault 1 "fault" 0 "normal" ;
VAL_ 1701 Led0043_fault 1 "fault" 0 "normal" ;
VAL_ 1701 Led0042_fault 1 "fault" 0 "normal" ;
VAL_ 1701 Led0041_fault 1 "fault" 0 "normal" ;
VAL_ 1701 Led0040_fault 1 "fault" 0 "normal" ;
VAL_ 1701 Led0039_fault 1 "fault" 0 "normal" ;
VAL_ 1701 Led0038_fault 1 "fault" 0 "normal" ;
VAL_ 1701 Led0037_fault 1 "fault" 0 "normal" ;
VAL_ 1701 Led0036_fault 1 "fault" 0 "normal" ;
VAL_ 1701 Led0035_fault 1 "fault" 0 "normal" ;
VAL_ 1701 Led0034_fault 1 "fault" 0 "normal" ;
VAL_ 1701 Led0033_fault 1 "fault" 0 "normal" ;
VAL_ 1701 Led0032_fault 1 "fault" 0 "normal" ;
VAL_ 1701 Led0031_fault 1 "fault" 0 "normal" ;
VAL_ 1701 Led0030_fault 1 "fault" 0 "normal" ;
VAL_ 1701 Led0029_fault 1 "fault" 0 "normal" ;
VAL_ 1701 Led0028_fault 1 "fault" 0 "normal" ;
VAL_ 1701 Led0027_fault 1 "fault" 0 "normal" ;
VAL_ 1701 Led0026_fault 1 "fault" 0 "normal" ;
VAL_ 1701 Led0025_fault 1 "fault" 0 "normal" ;
VAL_ 1701 Led0024_fault 1 "fault" 0 "normal" ;
VAL_ 1701 Led0023_fault 1 "fault" 0 "normal" ;
VAL_ 1701 Led0022_fault 1 "fault" 0 "normal" ;
VAL_ 1701 Led0021_fault 1 "fault" 0 "normal" ;
VAL_ 1701 Led0020_fault 1 "fault" 0 "normal" ;
VAL_ 1701 Led0019_fault 1 "fault" 0 "normal" ;
VAL_ 1701 Led0018_fault 1 "fault" 0 "normal" ;
VAL_ 1701 Led0017_fault 1 "fault" 0 "normal" ;
VAL_ 1701 Led0016_fault 1 "fault" 0 "normal" ;
VAL_ 1701 Led0015_fault 1 "fault" 0 "normal" ;
VAL_ 1701 Led0014_fault 1 "fault" 0 "normal" ;
VAL_ 1701 Led0013_fault 1 "fault" 0 "normal" ;
VAL_ 1701 Led0012_fault 1 "fault" 0 "normal" ;
VAL_ 1701 Led0011_fault 1 "fault" 0 "normal" ;
VAL_ 1701 Led0010_fault 1 "fault" 0 "normal" ;
VAL_ 1701 Led0007_fault 1 "fault" 0 "normal" ;
VAL_ 1701 Led0009_fault 1 "fault" 0 "normal" ;
VAL_ 1701 Led0008_fault 1 "fault" 0 "normal" ;
VAL_ 1701 Led0006_fault 1 "fault" 0 "normal" ;
VAL_ 1701 Led0005_fault 1 "fault" 0 "normal" ;
VAL_ 1701 Led0004_fault 1 "fault" 0 "normal" ;
VAL_ 1701 Led0003_fault 1 "fault" 0 "normal" ;
VAL_ 1701 Led0002_fault 1 "fault" 0 "normal" ;
VAL_ 1701 Led0001_fault 1 "fault" 0 "normal" ;
VAL_ 1700 Led0512_fault 1 "fault" 0 "normal" ;
VAL_ 1700 Led0511_fault 1 "fault" 0 "normal" ;
VAL_ 1700 Led0510_fault 1 "fault" 0 "normal" ;
VAL_ 1700 Led0509_fault 1 "fault" 0 "normal" ;
VAL_ 1700 Led0508_fault 1 "fault" 0 "normal" ;
VAL_ 1700 Led0507_fault 1 "fault" 0 "normal" ;
VAL_ 1700 Led0506_fault 1 "fault" 0 "normal" ;
VAL_ 1700 Led0505_fault 1 "fault" 0 "normal" ;
VAL_ 1700 Led0504_fault 1 "fault" 0 "normal" ;
VAL_ 1700 Led0503_fault 1 "fault" 0 "normal" ;
VAL_ 1700 Led0502_fault 1 "fault" 0 "normal" ;
VAL_ 1700 Led0501_fault 1 "fault" 0 "normal" ;
VAL_ 1700 Led0500_fault 1 "fault" 0 "normal" ;
VAL_ 1700 Led0499_fault 1 "fault" 0 "normal" ;
VAL_ 1700 Led0498_fault 1 "fault" 0 "normal" ;
VAL_ 1700 Led0497_fault 1 "fault" 0 "normal" ;
VAL_ 1700 Led0496_fault 1 "fault" 0 "normal" ;
VAL_ 1700 Led0495_fault 1 "fault" 0 "normal" ;
VAL_ 1700 Led0494_fault 1 "fault" 0 "normal" ;
VAL_ 1700 Led0493_fault 1 "fault" 0 "normal" ;
VAL_ 1700 Led0492_fault 1 "fault" 0 "normal" ;
VAL_ 1700 Led0491_fault 1 "fault" 0 "normal" ;
VAL_ 1700 Led0490_fault 1 "fault" 0 "normal" ;
VAL_ 1700 Led0489_fault 1 "fault" 0 "normal" ;
VAL_ 1700 Led0488_fault 1 "fault" 0 "normal" ;
VAL_ 1700 Led0487_fault 1 "fault" 0 "normal" ;
VAL_ 1700 Led0486_fault 1 "fault" 0 "normal" ;
VAL_ 1700 Led0485_fault 1 "fault" 0 "normal" ;
VAL_ 1700 Led0484_fault 1 "fault" 0 "normal" ;
VAL_ 1700 Led0483_fault 1 "fault" 0 "normal" ;
VAL_ 1700 Led0482_fault 1 "fault" 0 "normal" ;
VAL_ 1700 Led0481_fault 1 "fault" 0 "normal" ;
VAL_ 1700 Led0480_fault 1 "fault" 0 "normal" ;
VAL_ 1700 Led0479_fault 1 "fault" 0 "normal" ;
VAL_ 1700 Led0478_fault 1 "fault" 0 "normal" ;
VAL_ 1700 Led0477_fault 1 "fault" 0 "normal" ;
VAL_ 1700 Led0476_fault 1 "fault" 0 "normal" ;
VAL_ 1700 Led0475_fault 1 "fault" 0 "normal" ;
VAL_ 1700 Led0474_fault 1 "fault" 0 "normal" ;
VAL_ 1700 Led0473_fault 1 "fault" 0 "normal" ;
VAL_ 1700 Led0472_fault 1 "fault" 0 "normal" ;
VAL_ 1700 Led0471_fault 1 "fault" 0 "normal" ;
VAL_ 1700 Led0470_fault 1 "fault" 0 "normal" ;
VAL_ 1700 Led0469_fault 1 "fault" 0 "normal" ;
VAL_ 1700 Led0468_fault 1 "fault" 0 "normal" ;
VAL_ 1700 Led0467_fault 1 "fault" 0 "normal" ;
VAL_ 1700 Led0466_fault 1 "fault" 0 "normal" ;
VAL_ 1700 Led0465_fault 1 "fault" 0 "normal" ;
VAL_ 1700 Led0464_fault 1 "fault" 0 "normal" ;
VAL_ 1700 Led0463_fault 1 "fault" 0 "normal" ;
VAL_ 1700 Led0462_fault 1 "fault" 0 "normal" ;
VAL_ 1700 Led0461_fault 1 "fault" 0 "normal" ;
VAL_ 1700 Led0460_fault 1 "fault" 0 "normal" ;
VAL_ 1700 Led0459_fault 1 "fault" 0 "normal" ;
VAL_ 1700 Led0458_fault 1 "fault" 0 "normal" ;
VAL_ 1700 Led0457_fault 1 "fault" 0 "normal" ;
VAL_ 1700 Led0456_fault 1 "fault" 0 "normal" ;
VAL_ 1700 Led0455_fault 1 "fault" 0 "normal" ;
VAL_ 1700 Led0454_fault 1 "fault" 0 "normal" ;
VAL_ 1700 Led0453_fault 1 "fault" 0 "normal" ;
VAL_ 1700 Led0452_fault 1 "fault" 0 "normal" ;
VAL_ 1700 Led0451_fault 1 "fault" 0 "normal" ;
VAL_ 1700 Led0450_fault 1 "fault" 0 "normal" ;
VAL_ 1700 Led0449_fault 1 "fault" 0 "normal" ;
VAL_ 1700 Led0448_fault 1 "fault" 0 "normal" ;
VAL_ 1700 Led0447_fault 1 "fault" 0 "normal" ;
VAL_ 1700 Led0446_fault 1 "fault" 0 "normal" ;
VAL_ 1700 Led0445_fault 1 "fault" 0 "normal" ;
VAL_ 1700 Led0444_fault 1 "fault" 0 "normal" ;
VAL_ 1700 Led0443_fault 1 "fault" 0 "normal" ;
VAL_ 1700 Led0442_fault 1 "fault" 0 "normal" ;
VAL_ 1700 Led0441_fault 1 "fault" 0 "normal" ;
VAL_ 1700 Led0440_fault 1 "fault" 0 "normal" ;
VAL_ 1700 Led0439_fault 1 "fault" 0 "normal" ;
VAL_ 1700 Led0438_fault 1 "fault" 0 "normal" ;
VAL_ 1700 Led0437_fault 1 "fault" 0 "normal" ;
VAL_ 1700 Led0436_fault 1 "fault" 0 "normal" ;
VAL_ 1700 Led0435_fault 1 "fault" 0 "normal" ;
VAL_ 1700 Led0434_fault 1 "fault" 0 "normal" ;
VAL_ 1700 Led0433_fault 1 "fault" 0 "normal" ;
VAL_ 1700 Led0432_fault 1 "fault" 0 "normal" ;
VAL_ 1700 Led0431_fault 1 "fault" 0 "normal" ;
VAL_ 1700 Led0430_fault 1 "fault" 0 "normal" ;
VAL_ 1700 Led0429_fault 1 "fault" 0 "normal" ;
VAL_ 1700 Led0428_fault 1 "fault" 0 "normal" ;
VAL_ 1700 Led0427_fault 1 "fault" 0 "normal" ;
VAL_ 1700 Led0426_fault 1 "fault" 0 "normal" ;
VAL_ 1700 Led0425_fault 1 "fault" 0 "normal" ;
VAL_ 1700 Led0424_fault 1 "fault" 0 "normal" ;
VAL_ 1700 Led0423_fault 1 "fault" 0 "normal" ;
VAL_ 1700 Led0422_fault 1 "fault" 0 "normal" ;
VAL_ 1700 Led0421_fault 1 "fault" 0 "normal" ;
VAL_ 1700 Led0420_fault 1 "fault" 0 "normal" ;
VAL_ 1700 Led0419_fault 1 "fault" 0 "normal" ;
VAL_ 1700 Led0418_fault 1 "fault" 0 "normal" ;
VAL_ 1700 Led0417_fault 1 "fault" 0 "normal" ;
VAL_ 1700 Led0416_fault 1 "fault" 0 "normal" ;
VAL_ 1700 Led0415_fault 1 "fault" 0 "normal" ;
VAL_ 1700 Led0414_fault 1 "fault" 0 "normal" ;
VAL_ 1700 Led0413_fault 1 "fault" 0 "normal" ;
VAL_ 1700 Led0412_fault 1 "fault" 0 "normal" ;
VAL_ 1700 Led0411_fault 1 "fault" 0 "normal" ;
VAL_ 1700 Led0410_fault 1 "fault" 0 "normal" ;
VAL_ 1700 Led0409_fault 1 "fault" 0 "normal" ;
VAL_ 1700 Led0408_fault 1 "fault" 0 "normal" ;
VAL_ 1700 Led0407_fault 1 "fault" 0 "normal" ;
VAL_ 1700 Led0406_fault 1 "fault" 0 "normal" ;
VAL_ 1700 Led0405_fault 1 "fault" 0 "normal" ;
VAL_ 1700 Led0404_fault 1 "fault" 0 "normal" ;
VAL_ 1700 Led0403_fault 1 "fault" 0 "normal" ;
VAL_ 1700 Led0402_fault 1 "fault" 0 "normal" ;
VAL_ 1700 Led0401_fault 1 "fault" 0 "normal" ;
VAL_ 1700 Led0400_fault 1 "fault" 0 "normal" ;
VAL_ 1700 Led0399_fault 1 "fault" 0 "normal" ;
VAL_ 1700 Led0398_fault 1 "fault" 0 "normal" ;
VAL_ 1700 Led0397_fault 1 "fault" 0 "normal" ;
VAL_ 1700 Led0396_fault 1 "fault" 0 "normal" ;
VAL_ 1700 Led0395_fault 1 "fault" 0 "normal" ;
VAL_ 1700 Led0394_fault 1 "fault" 0 "normal" ;
VAL_ 1700 Led0393_fault 1 "fault" 0 "normal" ;
VAL_ 1700 Led0392_fault 1 "fault" 0 "normal" ;
VAL_ 1700 Led0391_fault 1 "fault" 0 "normal" ;
VAL_ 1700 Led0390_fault 1 "fault" 0 "normal" ;
VAL_ 1700 Led0389_fault 1 "fault" 0 "normal" ;
VAL_ 1700 Led0388_fault 1 "fault" 0 "normal" ;
VAL_ 1700 Led0387_fault 1 "fault" 0 "normal" ;
VAL_ 1700 Led0386_fault 1 "fault" 0 "normal" ;
VAL_ 1700 Led0385_fault 1 "fault" 0 "normal" ;
VAL_ 1700 Led0384_fault 1 "fault" 0 "normal" ;
VAL_ 1700 Led0383_fault 1 "fault" 0 "normal" ;
VAL_ 1700 Led0382_fault 1 "fault" 0 "normal" ;
VAL_ 1700 Led0381_fault 1 "fault" 0 "normal" ;
VAL_ 1700 Led0380_fault 1 "fault" 0 "normal" ;
VAL_ 1700 Led0379_fault 1 "fault" 0 "normal" ;
VAL_ 1700 Led0378_fault 1 "fault" 0 "normal" ;
VAL_ 1700 Led0377_fault 1 "fault" 0 "normal" ;
VAL_ 1700 Led0376_fault 1 "fault" 0 "normal" ;
VAL_ 1700 Led0375_fault 1 "fault" 0 "normal" ;
VAL_ 1700 Led0374_fault 1 "fault" 0 "normal" ;
VAL_ 1700 Led0373_fault 1 "fault" 0 "normal" ;
VAL_ 1700 Led0372_fault 1 "fault" 0 "normal" ;
VAL_ 1700 Led0371_fault 1 "fault" 0 "normal" ;
VAL_ 1700 Led0370_fault 1 "fault" 0 "normal" ;
VAL_ 1700 Led0369_fault 1 "fault" 0 "normal" ;
VAL_ 1700 Led0368_fault 1 "fault" 0 "normal" ;
VAL_ 1700 Led0367_fault 1 "fault" 0 "normal" ;
VAL_ 1700 Led0366_fault 1 "fault" 0 "normal" ;
VAL_ 1700 Led0365_fault 1 "fault" 0 "normal" ;
VAL_ 1700 Led0364_fault 1 "fault" 0 "normal" ;
VAL_ 1700 Led0363_fault 1 "fault" 0 "normal" ;
VAL_ 1700 Led0362_fault 1 "fault" 0 "normal" ;
VAL_ 1700 Led0361_fault 1 "fault" 0 "normal" ;
VAL_ 1700 Led0360_fault 1 "fault" 0 "normal" ;
VAL_ 1700 Led0359_fault 1 "fault" 0 "normal" ;
VAL_ 1700 Led0358_fault 1 "fault" 0 "normal" ;
VAL_ 1700 Led0357_fault 1 "fault" 0 "normal" ;
VAL_ 1700 Led0356_fault 1 "fault" 0 "normal" ;
VAL_ 1700 Led0355_fault 1 "fault" 0 "normal" ;
VAL_ 1700 Led0354_fault 1 "fault" 0 "normal" ;
VAL_ 1700 Led0353_fault 1 "fault" 0 "normal" ;
VAL_ 1700 Led0352_fault 1 "fault" 0 "normal" ;
VAL_ 1700 Led0351_fault 1 "fault" 0 "normal" ;
VAL_ 1700 Led0350_fault 1 "fault" 0 "normal" ;
VAL_ 1700 Led0349_fault 1 "fault" 0 "normal" ;
VAL_ 1700 Led0348_fault 1 "fault" 0 "normal" ;
VAL_ 1700 Led0347_fault 1 "fault" 0 "normal" ;
VAL_ 1700 Led0346_fault 1 "fault" 0 "normal" ;
VAL_ 1700 Led0345_fault 1 "fault" 0 "normal" ;
VAL_ 1700 Led0344_fault 1 "fault" 0 "normal" ;
VAL_ 1700 Led0343_fault 1 "fault" 0 "normal" ;
VAL_ 1700 Led0342_fault 1 "fault" 0 "normal" ;
VAL_ 1700 Led0341_fault 1 "fault" 0 "normal" ;
VAL_ 1700 Led0340_fault 1 "fault" 0 "normal" ;
VAL_ 1700 Led0339_fault 1 "fault" 0 "normal" ;
VAL_ 1700 Led0338_fault 1 "fault" 0 "normal" ;
VAL_ 1700 Led0337_fault 1 "fault" 0 "normal" ;
VAL_ 1700 Led0336_fault 1 "fault" 0 "normal" ;
VAL_ 1700 Led0335_fault 1 "fault" 0 "normal" ;
VAL_ 1700 Led0334_fault 1 "fault" 0 "normal" ;
VAL_ 1700 Led0333_fault 1 "fault" 0 "normal" ;
VAL_ 1700 Led0332_fault 1 "fault" 0 "normal" ;
VAL_ 1700 Led0331_fault 1 "fault" 0 "normal" ;
VAL_ 1700 Led0330_fault 1 "fault" 0 "normal" ;
VAL_ 1700 Led0329_fault 1 "fault" 0 "normal" ;
VAL_ 1700 Led0328_fault 1 "fault" 0 "normal" ;
VAL_ 1700 Led0327_fault 1 "fault" 0 "normal" ;
VAL_ 1700 Led0326_fault 1 "fault" 0 "normal" ;
VAL_ 1700 Led0325_fault 1 "fault" 0 "normal" ;
VAL_ 1700 Led0324_fault 1 "fault" 0 "normal" ;
VAL_ 1700 Led0323_fault 1 "fault" 0 "normal" ;
VAL_ 1700 Led0322_fault 1 "fault" 0 "normal" ;
VAL_ 1700 Led0321_fault 1 "fault" 0 "normal" ;
VAL_ 1700 Led0320_fault 1 "fault" 0 "normal" ;
VAL_ 1700 Led0319_fault 1 "fault" 0 "normal" ;
VAL_ 1700 Led0318_fault 1 "fault" 0 "normal" ;
VAL_ 1700 Led0317_fault 1 "fault" 0 "normal" ;
VAL_ 1700 Led0316_fault 1 "fault" 0 "normal" ;
VAL_ 1700 Led0315_fault 1 "fault" 0 "normal" ;
VAL_ 1700 Led0314_fault 1 "fault" 0 "normal" ;
VAL_ 1700 Led0313_fault 1 "fault" 0 "normal" ;
VAL_ 1700 Led0312_fault 1 "fault" 0 "normal" ;
VAL_ 1700 Led0311_fault 1 "fault" 0 "normal" ;
VAL_ 1700 Led0310_fault 1 "fault" 0 "normal" ;
VAL_ 1700 Led0309_fault 1 "fault" 0 "normal" ;
VAL_ 1700 Led0308_fault 1 "fault" 0 "normal" ;
VAL_ 1700 Led0307_fault 1 "fault" 0 "normal" ;
VAL_ 1700 Led0306_fault 1 "fault" 0 "normal" ;
VAL_ 1700 Led0305_fault 1 "fault" 0 "normal" ;
VAL_ 1700 Led0304_fault 1 "fault" 0 "normal" ;
VAL_ 1700 Led0303_fault 1 "fault" 0 "normal" ;
VAL_ 1700 Led0302_fault 1 "fault" 0 "normal" ;
VAL_ 1700 Led0301_fault 1 "fault" 0 "normal" ;
VAL_ 1700 Led0300_fault 1 "fault" 0 "normal" ;
VAL_ 1700 Led0299_fault 1 "fault" 0 "normal" ;
VAL_ 1700 Led0298_fault 1 "fault" 0 "normal" ;
VAL_ 1700 Led0297_fault 1 "fault" 0 "normal" ;
VAL_ 1700 Led0296_fault 1 "fault" 0 "normal" ;
VAL_ 1700 Led0295_fault 1 "fault" 0 "normal" ;
VAL_ 1700 Led0294_fault 1 "fault" 0 "normal" ;
VAL_ 1700 Led0293_fault 1 "fault" 0 "normal" ;
VAL_ 1700 Led0292_fault 1 "fault" 0 "normal" ;
VAL_ 1700 Led0291_fault 1 "fault" 0 "normal" ;
VAL_ 1700 Led0290_fault 1 "fault" 0 "normal" ;
VAL_ 1700 Led0289_fault 1 "fault" 0 "normal" ;
VAL_ 1700 Led0288_fault 1 "fault" 0 "normal" ;
VAL_ 1700 Led0287_fault 1 "fault" 0 "normal" ;
VAL_ 1700 Led0286_fault 1 "fault" 0 "normal" ;
VAL_ 1700 Led0285_fault 1 "fault" 0 "normal" ;
VAL_ 1700 Led0284_fault 1 "fault" 0 "normal" ;
VAL_ 1700 Led0283_fault 1 "fault" 0 "normal" ;
VAL_ 1700 Led0282_fault 1 "fault" 0 "normal" ;
VAL_ 1700 Led0281_fault 1 "fault" 0 "normal" ;
VAL_ 1700 Led0280_fault 1 "fault" 0 "normal" ;
VAL_ 1700 Led0279_fault 1 "fault" 0 "normal" ;
VAL_ 1700 Led0278_fault 1 "fault" 0 "normal" ;
VAL_ 1700 Led0277_fault 1 "fault" 0 "normal" ;
VAL_ 1700 Led0276_fault 1 "fault" 0 "normal" ;
VAL_ 1700 Led0275_fault 1 "fault" 0 "normal" ;
VAL_ 1700 Led0274_fault 1 "fault" 0 "normal" ;
VAL_ 1700 Led0273_fault 1 "fault" 0 "normal" ;
VAL_ 1700 Led0272_fault 1 "fault" 0 "normal" ;
VAL_ 1700 Led0271_fault 1 "fault" 0 "normal" ;
VAL_ 1700 Led0270_fault 1 "fault" 0 "normal" ;
VAL_ 1700 Led0269_fault 1 "fault" 0 "normal" ;
VAL_ 1700 Led0268_fault 1 "fault" 0 "normal" ;
VAL_ 1700 Led0267_fault 1 "fault" 0 "normal" ;
VAL_ 1700 Led0266_fault 1 "fault" 0 "normal" ;
VAL_ 1700 Led0265_fault 1 "fault" 0 "normal" ;
VAL_ 1700 Led0264_fault 1 "fault" 0 "normal" ;
VAL_ 1700 Led0263_fault 1 "fault" 0 "normal" ;
VAL_ 1700 Led0262_fault 1 "fault" 0 "normal" ;
VAL_ 1700 Led0261_fault 1 "fault" 0 "normal" ;
VAL_ 1700 Led0260_fault 1 "fault" 0 "normal" ;
VAL_ 1700 Led0259_fault 1 "fault" 0 "normal" ;
VAL_ 1700 Led0258_fault 1 "fault" 0 "normal" ;
VAL_ 1700 Led0257_fault 1 "fault" 0 "normal" ;
VAL_ 1700 Led0256_fault 1 "fault" 0 "normal" ;
VAL_ 1700 Led0255_fault 1 "fault" 0 "normal" ;
VAL_ 1700 Led0254_fault 1 "fault" 0 "normal" ;
VAL_ 1700 Led0253_fault 1 "fault" 0 "normal" ;
VAL_ 1700 Led0252_fault 1 "fault" 0 "normal" ;
VAL_ 1700 Led0251_fault 1 "fault" 0 "normal" ;
VAL_ 1700 Led0250_fault 1 "fault" 0 "normal" ;
VAL_ 1700 Led0249_fault 1 "fault" 0 "normal" ;
VAL_ 1700 Led0248_fault 1 "fault" 0 "normal" ;
VAL_ 1700 Led0247_fault 1 "fault" 0 "normal" ;
VAL_ 1700 Led0246_fault 1 "fault" 0 "normal" ;
VAL_ 1700 Led0245_fault 1 "fault" 0 "normal" ;
VAL_ 1700 Led0244_fault 1 "fault" 0 "normal" ;
VAL_ 1700 Led0243_fault 1 "fault" 0 "normal" ;
VAL_ 1700 Led0242_fault 1 "fault" 0 "normal" ;
VAL_ 1700 Led0241_fault 1 "fault" 0 "normal" ;
VAL_ 1700 Led0240_fault 1 "fault" 0 "normal" ;
VAL_ 1700 Led0239_fault 1 "fault" 0 "normal" ;
VAL_ 1700 Led0238_fault 1 "fault" 0 "normal" ;
VAL_ 1700 Led0237_fault 1 "fault" 0 "normal" ;
VAL_ 1700 Led0236_fault 1 "fault" 0 "normal" ;
VAL_ 1700 Led0235_fault 1 "fault" 0 "normal" ;
VAL_ 1700 Led0234_fault 1 "fault" 0 "normal" ;
VAL_ 1700 Led0233_fault 1 "fault" 0 "normal" ;
VAL_ 1700 Led0232_fault 1 "fault" 0 "normal" ;
VAL_ 1700 Led0231_fault 1 "fault" 0 "normal" ;
VAL_ 1700 Led0230_fault 1 "fault" 0 "normal" ;
VAL_ 1700 Led0229_fault 1 "fault" 0 "normal" ;
VAL_ 1700 Led0228_fault 1 "fault" 0 "normal" ;
VAL_ 1700 Led0227_fault 1 "fault" 0 "normal" ;
VAL_ 1700 Led0226_fault 1 "fault" 0 "normal" ;
VAL_ 1700 Led0225_fault 1 "fault" 0 "normal" ;
VAL_ 1700 Led0224_fault 1 "fault" 0 "normal" ;
VAL_ 1700 Led0223_fault 1 "fault" 0 "normal" ;
VAL_ 1700 Led0222_fault 1 "fault" 0 "normal" ;
VAL_ 1700 Led0221_fault 1 "fault" 0 "normal" ;
VAL_ 1700 Led0220_fault 1 "fault" 0 "normal" ;
VAL_ 1700 Led0219_fault 1 "fault" 0 "normal" ;
VAL_ 1700 Led0218_fault 1 "fault" 0 "normal" ;
VAL_ 1700 Led0217_fault 1 "fault" 0 "normal" ;
VAL_ 1700 Led0216_fault 1 "fault" 0 "normal" ;
VAL_ 1700 Led0215_fault 1 "fault" 0 "normal" ;
VAL_ 1700 Led0214_fault 1 "fault" 0 "normal" ;
VAL_ 1700 Led0213_fault 1 "fault" 0 "normal" ;
VAL_ 1700 Led0212_fault 1 "fault" 0 "normal" ;
VAL_ 1700 Led0211_fault 1 "fault" 0 "normal" ;
VAL_ 1700 Led0210_fault 1 "fault" 0 "normal" ;
VAL_ 1700 Led0209_fault 1 "fault" 0 "normal" ;
VAL_ 1700 Led0208_fault 1 "fault" 0 "normal" ;
VAL_ 1700 Led0207_fault 1 "fault" 0 "normal" ;
VAL_ 1700 Led0206_fault 1 "fault" 0 "normal" ;
VAL_ 1700 Led0205_fault 1 "fault" 0 "normal" ;
VAL_ 1700 Led0204_fault 1 "fault" 0 "normal" ;
VAL_ 1700 Led0203_fault 1 "fault" 0 "normal" ;
VAL_ 1700 Led0202_fault 1 "fault" 0 "normal" ;
VAL_ 1700 Led0201_fault 1 "fault" 0 "normal" ;
VAL_ 1700 Led0200_fault 1 "fault" 0 "normal" ;
VAL_ 1700 Led0199_fault 1 "fault" 0 "normal" ;
VAL_ 1700 Led0198_fault 1 "fault" 0 "normal" ;
VAL_ 1700 Led0197_fault 1 "fault" 0 "normal" ;
VAL_ 1700 Led0196_fault 1 "fault" 0 "normal" ;
VAL_ 1700 Led0195_fault 1 "fault" 0 "normal" ;
VAL_ 1700 Led0194_fault 1 "fault" 0 "normal" ;
VAL_ 1700 Led0193_fault 1 "fault" 0 "normal" ;
VAL_ 1700 Led0192_fault 1 "fault" 0 "normal" ;
VAL_ 1700 Led0191_fault 1 "fault" 0 "normal" ;
VAL_ 1700 Led0190_fault 1 "fault" 0 "normal" ;
VAL_ 1700 Led0189_fault 1 "fault" 0 "normal" ;
VAL_ 1700 Led0188_fault 1 "fault" 0 "normal" ;
VAL_ 1700 Led0187_fault 1 "fault" 0 "normal" ;
VAL_ 1700 Led0186_fault 1 "fault" 0 "normal" ;
VAL_ 1700 Led0185_fault 1 "fault" 0 "normal" ;
VAL_ 1700 Led0184_fault 1 "fault" 0 "normal" ;
VAL_ 1700 Led0183_fault 1 "fault" 0 "normal" ;
VAL_ 1700 Led0182_fault 1 "fault" 0 "normal" ;
VAL_ 1700 Led0181_fault 1 "fault" 0 "normal" ;
VAL_ 1700 Led0180_fault 1 "fault" 0 "normal" ;
VAL_ 1700 Led0179_fault 1 "fault" 0 "normal" ;
VAL_ 1700 Led0178_fault 1 "fault" 0 "normal" ;
VAL_ 1700 Led0177_fault 1 "fault" 0 "normal" ;
VAL_ 1700 Led0176_fault 1 "fault" 0 "normal" ;
VAL_ 1700 Led0175_fault 1 "fault" 0 "normal" ;
VAL_ 1700 Led0174_fault 1 "fault" 0 "normal" ;
VAL_ 1700 Led0173_fault 1 "fault" 0 "normal" ;
VAL_ 1700 Led0172_fault 1 "fault" 0 "normal" ;
VAL_ 1700 Led0171_fault 1 "fault" 0 "normal" ;
VAL_ 1700 Led0170_fault 1 "fault" 0 "normal" ;
VAL_ 1700 Led0169_fault 1 "fault" 0 "normal" ;
VAL_ 1700 Led0168_fault 1 "fault" 0 "normal" ;
VAL_ 1700 Led0167_fault 1 "fault" 0 "normal" ;
VAL_ 1700 Led0166_fault 1 "fault" 0 "normal" ;
VAL_ 1700 Led0165_fault 1 "fault" 0 "normal" ;
VAL_ 1700 Led0164_fault 1 "fault" 0 "normal" ;
VAL_ 1700 Led0163_fault 1 "fault" 0 "normal" ;
VAL_ 1700 Led0162_fault 1 "fault" 0 "normal" ;
VAL_ 1700 Led0161_fault 1 "fault" 0 "normal" ;
VAL_ 1700 Led0160_fault 1 "fault" 0 "normal" ;
VAL_ 1700 Led0159_fault 1 "fault" 0 "normal" ;
VAL_ 1700 Led0158_fault 1 "fault" 0 "normal" ;
VAL_ 1700 Led0157_fault 1 "fault" 0 "normal" ;
VAL_ 1700 Led0156_fault 1 "fault" 0 "normal" ;
VAL_ 1700 Led0155_fault 1 "fault" 0 "normal" ;
VAL_ 1700 Led0154_fault 1 "fault" 0 "normal" ;
VAL_ 1700 Led0153_fault 1 "fault" 0 "normal" ;
VAL_ 1700 Led0152_fault 1 "fault" 0 "normal" ;
VAL_ 1700 Led0151_fault 1 "fault" 0 "normal" ;
VAL_ 1700 Led0150_fault 1 "fault" 0 "normal" ;
VAL_ 1700 Led0149_fault 1 "fault" 0 "normal" ;
VAL_ 1700 Led0148_fault 1 "fault" 0 "normal" ;
VAL_ 1700 Led0147_fault 1 "fault" 0 "normal" ;
VAL_ 1700 Led0146_fault 1 "fault" 0 "normal" ;
VAL_ 1700 Led0145_fault 1 "fault" 0 "normal" ;
VAL_ 1700 Led0144_fault 1 "fault" 0 "normal" ;
VAL_ 1700 Led0143_fault 1 "fault" 0 "normal" ;
VAL_ 1700 Led0142_fault 1 "fault" 0 "normal" ;
VAL_ 1700 Led0141_fault 1 "fault" 0 "normal" ;
VAL_ 1700 Led0140_fault 1 "fault" 0 "normal" ;
VAL_ 1700 Led0139_fault 1 "fault" 0 "normal" ;
VAL_ 1700 Led0138_fault 1 "fault" 0 "normal" ;
VAL_ 1700 Led0137_fault 1 "fault" 0 "normal" ;
VAL_ 1700 Led0136_fault 1 "fault" 0 "normal" ;
VAL_ 1700 Led0135_fault 1 "fault" 0 "normal" ;
VAL_ 1700 Led0134_fault 1 "fault" 0 "normal" ;
VAL_ 1700 Led0133_fault 1 "fault" 0 "normal" ;
VAL_ 1700 Led0132_fault 1 "fault" 0 "normal" ;
VAL_ 1700 Led0131_fault 1 "fault" 0 "normal" ;
VAL_ 1700 Led0130_fault 1 "fault" 0 "normal" ;
VAL_ 1700 Led0129_fault 1 "fault" 0 "normal" ;
VAL_ 1700 Led0128_fault 1 "fault" 0 "normal" ;
VAL_ 1700 Led0127_fault 1 "fault" 0 "normal" ;
VAL_ 1700 Led0126_fault 1 "fault" 0 "normal" ;
VAL_ 1700 Led0125_fault 1 "fault" 0 "normal" ;
VAL_ 1700 Led0124_fault 1 "fault" 0 "normal" ;
VAL_ 1700 Led0123_fault 1 "fault" 0 "normal" ;
VAL_ 1700 Led0122_fault 1 "fault" 0 "normal" ;
VAL_ 1700 Led0121_fault 1 "fault" 0 "normal" ;
VAL_ 1700 Led0120_fault 1 "fault" 0 "normal" ;
VAL_ 1700 Led0119_fault 1 "fault" 0 "normal" ;
VAL_ 1700 Led0118_fault 1 "fault" 0 "normal" ;
VAL_ 1700 Led0117_fault 1 "fault" 0 "normal" ;
VAL_ 1700 Led0116_fault 1 "fault" 0 "normal" ;
VAL_ 1700 Led0115_fault 1 "fault" 0 "normal" ;
VAL_ 1700 Led0114_fault 1 "fault" 0 "normal" ;
VAL_ 1700 Led0113_fault 1 "fault" 0 "normal" ;
VAL_ 1700 Led0112_fault 1 "fault" 0 "normal" ;
VAL_ 1700 Led0111_fault 1 "fault" 0 "normal" ;
VAL_ 1700 Led0110_fault 1 "fault" 0 "normal" ;
VAL_ 1700 Led0109_fault 1 "fault" 0 "normal" ;
VAL_ 1700 Led0108_fault 1 "fault" 0 "normal" ;
VAL_ 1700 Led0107_fault 1 "fault" 0 "normal" ;
VAL_ 1700 Led0106_fault 1 "fault" 0 "normal" ;
VAL_ 1700 Led0105_fault 1 "fault" 0 "normal" ;
VAL_ 1700 Led0104_fault 1 "fault" 0 "normal" ;
VAL_ 1700 Led0103_fault 1 "fault" 0 "normal" ;
VAL_ 1700 Led0102_fault 1 "fault" 0 "normal" ;
VAL_ 1700 Led0101_fault 1 "fault" 0 "normal" ;
VAL_ 1700 Led0100_fault 1 "fault" 0 "normal" ;
VAL_ 1700 Led0099_fault 1 "fault" 0 "normal" ;
VAL_ 1700 Led0098_fault 1 "fault" 0 "normal" ;
VAL_ 1700 Led0097_fault 1 "fault" 0 "normal" ;
VAL_ 1700 Led0096_fault 1 "fault" 0 "normal" ;
VAL_ 1700 Led0095_fault 1 "fault" 0 "normal" ;
VAL_ 1700 Led0094_fault 1 "fault" 0 "normal" ;
VAL_ 1700 Led0093_fault 1 "fault" 0 "normal" ;
VAL_ 1700 Led0092_fault 1 "fault" 0 "normal" ;
VAL_ 1700 Led0091_fault 1 "fault" 0 "normal" ;
VAL_ 1700 Led0090_fault 1 "fault" 0 "normal" ;
VAL_ 1700 Led0089_fault 1 "fault" 0 "normal" ;
VAL_ 1700 Led0088_fault 1 "fault" 0 "normal" ;
VAL_ 1700 Led0087_fault 1 "fault" 0 "normal" ;
VAL_ 1700 Led0086_fault 1 "fault" 0 "normal" ;
VAL_ 1700 Led0085_fault 1 "fault" 0 "normal" ;
VAL_ 1700 Led0084_fault 1 "fault" 0 "normal" ;
VAL_ 1700 Led0083_fault 1 "fault" 0 "normal" ;
VAL_ 1700 Led0082_fault 1 "fault" 0 "normal" ;
VAL_ 1700 Led0081_fault 1 "fault" 0 "normal" ;
VAL_ 1700 Led0080_fault 1 "fault" 0 "normal" ;
VAL_ 1700 Led0079_fault 1 "fault" 0 "normal" ;
VAL_ 1700 Led0078_fault 1 "fault" 0 "normal" ;
VAL_ 1700 Led0077_fault 1 "fault" 0 "normal" ;
VAL_ 1700 Led0076_fault 1 "fault" 0 "normal" ;
VAL_ 1700 Led0075_fault 1 "fault" 0 "normal" ;
VAL_ 1700 Led0074_fault 1 "fault" 0 "normal" ;
VAL_ 1700 Led0073_fault 1 "fault" 0 "normal" ;
VAL_ 1700 Led0072_fault 1 "fault" 0 "normal" ;
VAL_ 1700 Led0071_fault 1 "fault" 0 "normal" ;
VAL_ 1700 Led0070_fault 1 "fault" 0 "normal" ;
VAL_ 1700 Led0069_fault 1 "fault" 0 "normal" ;
VAL_ 1700 Led0068_fault 1 "fault" 0 "normal" ;
VAL_ 1700 Led0067_fault 1 "fault" 0 "normal" ;
VAL_ 1700 Led0066_fault 1 "fault" 0 "normal" ;
VAL_ 1700 Led0065_fault 1 "fault" 0 "normal" ;
VAL_ 1700 Led0064_fault 1 "fault" 0 "normal" ;
VAL_ 1700 Led0063_fault 1 "fault" 0 "normal" ;
VAL_ 1700 Led0062_fault 1 "fault" 0 "normal" ;
VAL_ 1700 Led0061_fault 1 "fault" 0 "normal" ;
VAL_ 1700 Led0060_fault 1 "fault" 0 "normal" ;
VAL_ 1700 Led0059_fault 1 "fault" 0 "normal" ;
VAL_ 1700 Led0058_fault 1 "fault" 0 "normal" ;
VAL_ 1700 Led0057_fault 1 "fault" 0 "normal" ;
VAL_ 1700 Led0056_fault 1 "fault" 0 "normal" ;
VAL_ 1700 Led0055_fault 1 "fault" 0 "normal" ;
VAL_ 1700 Led0054_fault 1 "fault" 0 "normal" ;
VAL_ 1700 Led0053_fault 1 "fault" 0 "normal" ;
VAL_ 1700 Led0052_fault 1 "fault" 0 "normal" ;
VAL_ 1700 Led0051_fault 1 "fault" 0 "normal" ;
VAL_ 1700 Led0050_fault 1 "fault" 0 "normal" ;
VAL_ 1700 Led0049_fault 1 "fault" 0 "normal" ;
VAL_ 1700 Led0048_fault 1 "fault" 0 "normal" ;
VAL_ 1700 Led0047_fault 1 "fault" 0 "normal" ;
VAL_ 1700 Led0046_fault 1 "fault" 0 "normal" ;
VAL_ 1700 Led0045_fault 1 "fault" 0 "normal" ;
VAL_ 1700 Led0044_fault 1 "fault" 0 "normal" ;
VAL_ 1700 Led0043_fault 1 "fault" 0 "normal" ;
VAL_ 1700 Led0042_fault 1 "fault" 0 "normal" ;
VAL_ 1700 Led0041_fault 1 "fault" 0 "normal" ;
VAL_ 1700 Led0040_fault 1 "fault" 0 "normal" ;
VAL_ 1700 Led0039_fault 1 "fault" 0 "normal" ;
VAL_ 1700 Led0038_fault 1 "fault" 0 "normal" ;
VAL_ 1700 Led0037_fault 1 "fault" 0 "normal" ;
VAL_ 1700 Led0036_fault 1 "fault" 0 "normal" ;
VAL_ 1700 Led0035_fault 1 "fault" 0 "normal" ;
VAL_ 1700 Led0034_fault 1 "fault" 0 "normal" ;
VAL_ 1700 Led0033_fault 1 "fault" 0 "normal" ;
VAL_ 1700 Led0032_fault 1 "fault" 0 "normal" ;
VAL_ 1700 Led0031_fault 1 "fault" 0 "normal" ;
VAL_ 1700 Led0030_fault 1 "fault" 0 "normal" ;
VAL_ 1700 Led0029_fault 1 "fault" 0 "normal" ;
VAL_ 1700 Led0028_fault 1 "fault" 0 "normal" ;
VAL_ 1700 Led0027_fault 1 "fault" 0 "normal" ;
VAL_ 1700 Led0026_fault 1 "fault" 0 "normal" ;
VAL_ 1700 Led0025_fault 1 "fault" 0 "normal" ;
VAL_ 1700 Led0024_fault 1 "fault" 0 "normal" ;
VAL_ 1700 Led0023_fault 1 "fault" 0 "normal" ;
VAL_ 1700 Led0022_fault 1 "fault" 0 "normal" ;
VAL_ 1700 Led0021_fault 1 "fault" 0 "normal" ;
VAL_ 1700 Led0020_fault 1 "fault" 0 "normal" ;
VAL_ 1700 Led0019_fault 1 "fault" 0 "normal" ;
VAL_ 1700 Led0018_fault 1 "fault" 0 "normal" ;
VAL_ 1700 Led0017_fault 1 "fault" 0 "normal" ;
VAL_ 1700 Led0016_fault 1 "fault" 0 "normal" ;
VAL_ 1700 Led0015_fault 1 "fault" 0 "normal" ;
VAL_ 1700 Led0014_fault 1 "fault" 0 "normal" ;
VAL_ 1700 Led0013_fault 1 "fault" 0 "normal" ;
VAL_ 1700 Led0012_fault 1 "fault" 0 "normal" ;
VAL_ 1700 Led0011_fault 1 "fault" 0 "normal" ;
VAL_ 1700 Led0010_fault 1 "fault" 0 "normal" ;
VAL_ 1700 Led0007_fault 1 "fault" 0 "normal" ;
VAL_ 1700 Led0009_fault 1 "fault" 0 "normal" ;
VAL_ 1700 Led0008_fault 1 "fault" 0 "normal" ;
VAL_ 1700 Led0006_fault 1 "fault" 0 "normal" ;
VAL_ 1700 Led0005_fault 1 "fault" 0 "normal" ;
VAL_ 1700 Led0004_fault 1 "fault" 0 "normal" ;
VAL_ 1700 Led0003_fault 1 "fault" 0 "normal" ;
VAL_ 1700 Led0002_fault 1 "fault" 0 "normal" ;
VAL_ 1700 Led0001_fault 1 "fault" 0 "normal" ;
